VERSION ""

NS_ :

BS_:

BU_: VMCU VGGSECUSystem TECU TACHO RECU_Virt HMIIOM GSSA EMS EBS DACU CIOM BBM ATCU ACM

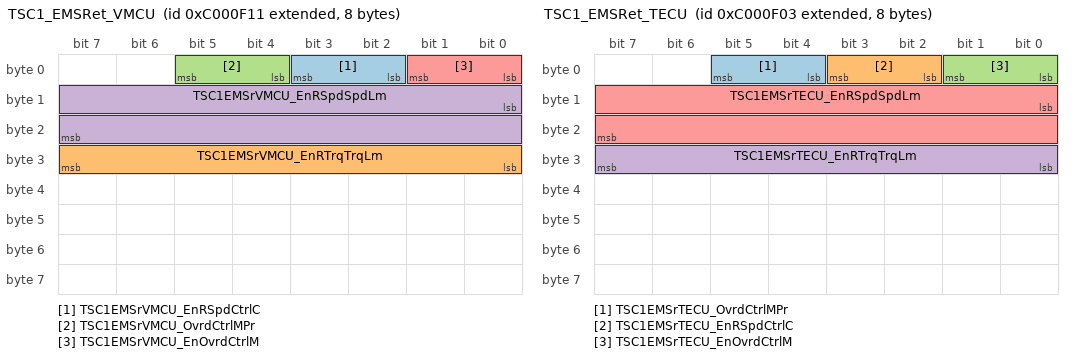
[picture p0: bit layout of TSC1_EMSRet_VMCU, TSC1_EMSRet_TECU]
BO_ 2348814097 TSC1_EMSRet_VMCU: 8 VMCU
 SG_ TSC1EMSrVMCU_EnRSpdCtrlC : 2|2@1+ (1,0) [0|0] ""  EBS,EMS
 SG_ TSC1EMSrVMCU_EnRTrqTrqLm : 24|8@1+ (1,-125) [-125|130] "Percent"  EMS,EBS
 SG_ TSC1EMSrVMCU_OvrdCtrlMPr : 4|2@1+ (1,0) [0|0] ""  EMS,EBS
 SG_ TSC1EMSrVMCU_EnRSpdSpdLm : 8|16@1+ (0.125,0) [0|8191.875] "rpm"  EBS,EMS
 SG_ TSC1EMSrVMCU_EnOvrdCtrlM : 0|2@1+ (1,0) [0|0] ""  EMS,EBS

BO_ 2348814083 TSC1_EMSRet_TECU: 8 TECU
 SG_ TSC1EMSrTECU_OvrdCtrlMPr : 4|2@1+ (1,0) [0|0] ""  EMS
 SG_ TSC1EMSrTECU_EnRSpdCtrlC : 2|2@1+ (1,0) [0|0] ""  EMS
 SG_ TSC1EMSrTECU_EnOvrdCtrlM : 0|2@1+ (1,0) [0|0] ""  EMS
 SG_ TSC1EMSrTECU_EnRTrqTrqLm : 24|8@1+ (1,-125) [-125|130] "Percent"  EMS
 SG_ TSC1EMSrTECU_EnRSpdSpdLm : 8|16@1+ (0.125,0) [0|8191.875] "rpm"  EMS

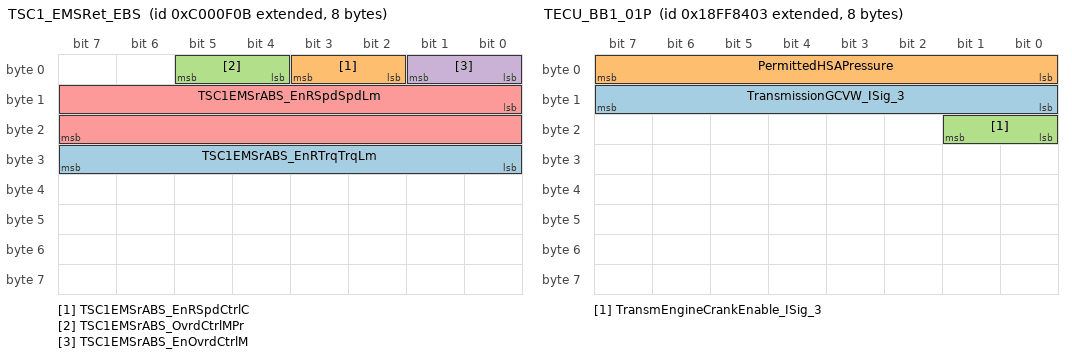
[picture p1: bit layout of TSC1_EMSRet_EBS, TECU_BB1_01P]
BO_ 2348814091 TSC1_EMSRet_EBS: 8 EBS
 SG_ TSC1EMSrABS_EnRTrqTrqLm : 24|8@1+ (1,-125) [-125|130] "Percent"  TECU,EMS
 SG_ TSC1EMSrABS_EnRSpdCtrlC : 2|2@1+ (1,0) [0|0] ""  TECU,EMS
 SG_ TSC1EMSrABS_OvrdCtrlMPr : 4|2@1+ (1,0) [0|0] ""  TECU,EMS
 SG_ TSC1EMSrABS_EnOvrdCtrlM : 0|2@1+ (1,0) [0|0] ""  TECU,EMS
 SG_ TSC1EMSrABS_EnRSpdSpdLm : 8|16@1+ (0.125,0) [0|8191.875] "rpm"  TECU,EMS

BO_ 2566755587 TRF2_X_TCU: 8 Vector__XXX

BO_ 2566846467 TRF1_X_TECU: 8 TECU
 SG_ TransmissionOilTemp_ISig_3 : 32|16@1+ (0.03125,-273) [-273|1774.96875] "DegreeC"  BBM,EMS,HMIIOM
 SG_ TransmissionOilLevel_ISig_3 : 8|8@1+ (0.4,0) [0|102] "Percent"  HMIIOM

BO_ 2565603075 TPDT_X_TECU: 8 TECU
 SG_ TPDT_SeqNo_TECU : 0|8@1+ (1,0) [0|0] ""  HMIIOM

BO_ 2565603310 TPDT_X_TACHO: 8 TACHO
 SG_ TPDT_SeqNo_TACHO : 0|8@1+ (1,0) [0|0] ""  HMIIOM,VMCU,CIOM

BO_ 2565603088 TPDT_X_RECU: 8 RECU_Virt
 SG_ TPDT_SeqNo_RECU : 0|8@1+ (1,0) [0|0] ""  DACU,EMS,VMCU,TECU,EBS

BO_ 2565603077 TPDT_X_GSSA: 8 Vector__XXX

BO_ 2565603087 TPDT_X_EMSRet: 8 EMS
 SG_ TPDT_SeqNo_EMSRet : 0|8@1+ (1,0) [0|0] ""  TECU,RECU_Virt,DACU,EBS,VGGSECUSystem,HMIIOM,VMCU

BO_ 2565603072 TPDT_X_EMS: 8 EMS
 SG_ TPDT_SeqNo_EMS : 0|8@1+ (1,0) [0|0] ""  TECU,DACU,HMIIOM,VMCU,VGGSECUSystem,EBS,RECU_Virt

BO_ 2565603083 TPDT_X_EBS: 8 EBS
 SG_ TPDT_SeqNo_EBS : 0|8@1+ (1,0) [0|0] ""  HMIIOM,VMCU

BO_ 2565603133 TPDT_X_ACM: 8 ACM
 SG_ TPDT_SeqNo_ACM : 0|8@1+ (1,0) [0|0] ""  HMIIOM

BO_ 2565668611 TPCM_X_TECU: 8 TECU
 SG_ TPCM_ControlByte_TECU : 0|8@1+ (1,0) [0|0] ""  HMIIOM

BO_ 2565668846 TPCM_X_TACHO: 8 TACHO
 SG_ TPCM_ControlByte_TACHO : 0|8@1+ (1,0) [0|0] ""  VMCU,CIOM,HMIIOM

BO_ 2565668624 TPCM_X_RECU: 8 RECU_Virt
 SG_ TPCM_ControlByte_RECU : 0|8@1+ (1,0) [0|0] ""  TECU,EMS,VMCU,DACU,EBS

BO_ 2565668613 TPCM_X_GSSA: 8 Vector__XXX

BO_ 2565668623 TPCM_X_EMSRet: 8 EMS
 SG_ TPCM_ControlByte_EMSRet : 0|8@1+ (1,0) [0|0] ""  DACU,VGGSECUSystem,HMIIOM,EBS,RECU_Virt,VMCU,TECU

BO_ 2565668608 TPCM_X_EMS: 8 EMS
 SG_ TPCM_ControlByte_EMS : 0|8@1+ (1,0) [0|0] ""  EBS,DACU,RECU_Virt,TECU,VGGSECUSystem,VMCU,HMIIOM

BO_ 2565668619 TPCM_X_EBS: 8 EBS
 SG_ TPCM_ControlByte_EBS : 0|8@1+ (1,0) [0|0] ""  HMIIOM,VMCU

BO_ 2565668669 TPCM_X_ACM: 8 ACM
 SG_ TPCM_ControlByte_ACM : 0|8@1+ (1,0) [0|0] ""  HMIIOM

BO_ 2633844483 TML_X_TCU: 8 Vector__XXX

BO_ 2566882307 TECU_BB1_01P: 8 TECU
 SG_ TransmissionGCVW_ISig_3 : 8|8@1+ (1000,0) [0|255000] "kg"  HMIIOM,EMS,VMCU
 SG_ PermittedHSAPressure : 0|8@1+ (0.4,0) [0|102] "Percent"  EBS
 SG_ TransmEngineCrankEnable_ISig_3 : 16|2@1+ (1,0) [0|0] ""  VMCU

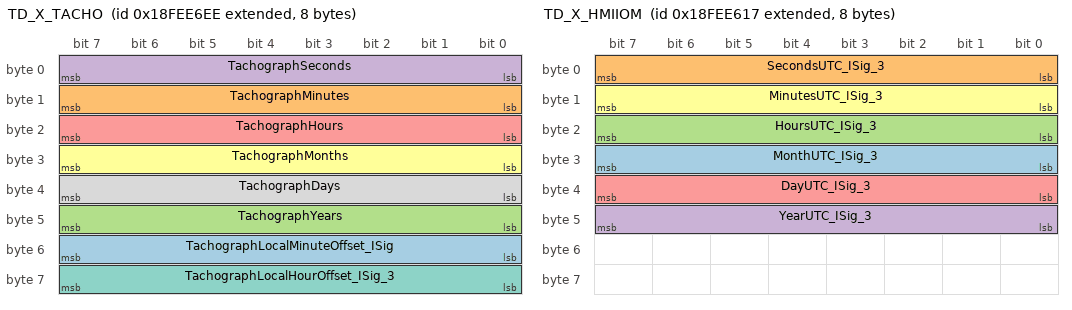
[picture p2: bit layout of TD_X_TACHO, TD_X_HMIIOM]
BO_ 2566842094 TD_X_TACHO: 8 TACHO
 SG_ TachographLocalMinuteOffset_ISig : 48|8@1+ (1,-125) [-125|130] "min"  HMIIOM,BBM
 SG_ TachographMinutes : 8|8@1+ (1,0) [0|255] "min"  HMIIOM
 SG_ TachographYears : 40|8@1+ (1,1985) [1985|2240] "Years"  HMIIOM
 SG_ TachographSeconds : 0|8@1+ (0.25,0) [0|63.75] "s"  HMIIOM
 SG_ TachographHours : 16|8@1+ (1,0) [0|255] "h"  HMIIOM
 SG_ TachographMonths : 24|8@1+ (1,0) [0|255] "Months"  HMIIOM
 SG_ TachographLocalHourOffset_ISig_3 : 56|8@1+ (1,-125) [-125|130] "h"  BBM,HMIIOM
 SG_ TachographDays : 32|8@1+ (0.25,0) [0|63.75] "Days"  HMIIOM

BO_ 2566841879 TD_X_HMIIOM: 8 HMIIOM
 SG_ MonthUTC_ISig_3 : 24|8@1+ (1,0) [0|255] "Months"  EBS,TECU,ACM,DACU,EMS,BBM,VMCU,CIOM
 SG_ SecondsUTC_ISig_3 : 0|8@1+ (0.25,0) [0|63.75] "s"  DACU,TECU,CIOM,ACM,VMCU,BBM,EBS,EMS
 SG_ HoursUTC_ISig_3 : 16|8@1+ (1,0) [0|255] "h"  EBS,DACU,ACM,BBM,TECU,CIOM,VMCU,EMS
 SG_ YearUTC_ISig_3 : 40|8@1+ (1,1985) [1985|2240] "Years"  EBS,EMS,DACU,VMCU,ACM,BBM,CIOM,TECU
 SG_ DayUTC_ISig_3 : 32|8@1+ (0.25,0) [0|63.75] "Days"  TECU,CIOM,EBS,VMCU,EMS,DACU,ACM,BBM
 SG_ MinutesUTC_ISig_3 : 8|8@1+ (1,0) [0|255] "min"  DACU,VMCU,TECU,CIOM,ACM,EMS,EBS,BBM

BO_ 2564156951 TDA_X_HMIIOM: 8 HMIIOM
 SG_ AdjustLocalMinuteOffset : 48|8@1+ (1,-125) [-125|130] "min"  TACHO
 SG_ AdjustLocalHourOffset : 56|8@1+ (1,-125) [-125|130] "h"  TACHO

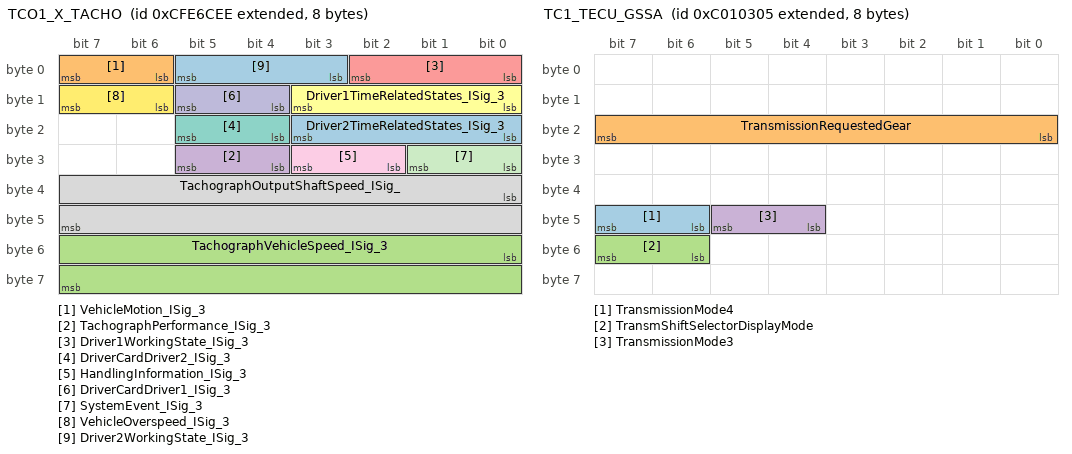
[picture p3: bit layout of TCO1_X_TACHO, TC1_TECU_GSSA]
BO_ 2365484270 TCO1_X_TACHO: 8 TACHO
 SG_ Driver2TimeRelatedStates_ISig_3 : 16|4@1+ (1,0) [0|0] ""  BBM,CIOM,HMIIOM
 SG_ VehicleMotion_ISig_3 : 6|2@1+ (1,0) [0|0] ""  HMIIOM,CIOM,BBM
 SG_ TachographVehicleSpeed_ISig_3 : 48|16@1+ (0.00390625,0) [0|255.99609375] "Km_per_h"  CIOM,VMCU,BBM,HMIIOM
 SG_ TachographPerformance_ISig_3 : 28|2@1+ (1,0) [0|0] ""  BBM,CIOM,HMIIOM,VMCU
 SG_ Driver1WorkingState_ISig_3 : 0|3@1+ (1,0) [0|0] ""  BBM,HMIIOM,CIOM
 SG_ Driver1TimeRelatedStates_ISig_3 : 8|4@1+ (1,0) [0|0] ""  CIOM,BBM,HMIIOM
 SG_ DriverCardDriver2_ISig_3 : 20|2@1+ (1,0) [0|0] ""  CIOM,BBM,HMIIOM
 SG_ TachographOutputShaftSpeed_ISig_ : 32|16@1+ (0.125,0) [0|8191.875] "rpm"  VMCU,BBM
 SG_ HandlingInformation_ISig_3 : 26|2@1+ (1,0) [0|0] ""  CIOM,VMCU,HMIIOM,BBM
 SG_ DriverCardDriver1_ISig_3 : 12|2@1+ (1,0) [0|0] ""  CIOM,VMCU,HMIIOM,BBM,DACU
 SG_ SystemEvent_ISig_3 : 24|2@1+ (1,0) [0|0] ""  HMIIOM,BBM,VMCU,CIOM
 SG_ VehicleOverspeed_ISig_3 : 14|2@1+ (1,0) [0|0] ""  CIOM,BBM,HMIIOM
 SG_ Driver2WorkingState_ISig_3 : 3|3@1+ (1,0) [0|0] ""  CIOM,BBM,HMIIOM

BO_ 2566840835 TCFG_X_TCU: 8 Vector__XXX

BO_ 2348876549 TC1_TECU_GSSA: 8 GSSA
 SG_ TransmissionMode4 : 46|2@1+ (1,0) [0|0] ""  TECU
 SG_ TransmissionRequestedGear : 16|8@1+ (1,-125) [-125|130] "GearValue"  TECU
 SG_ TransmShiftSelectorDisplayMode : 54|2@1+ (1,0) [0|0] ""  TECU
 SG_ TransmissionMode3 : 44|2@1+ (1,0) [0|0] ""  TECU

BO_ 2566838787 SOFT_X_TCU: 8 Vector__XXX

BO_ 2566838789 SOFT_X_GSSA: 8 Vector__XXX

BO_ 2566862055 Reserved_VDC_BB1: 8 Vector__XXX

BO_ 2566862311 Reserved_CCU_BB1_04P: 8 Vector__XXX

BO_ 2566861799 Reserved_CCU_BB1_03P: 8 Vector__XXX

BO_ 2566861543 Reserved_CCU_BB1_02P: 8 Vector__XXX

BO_ 2566861287 Reserved_CCU_BB1_01P: 8 Vector__XXX

BO_ 2566862567 Reserved_BMS_BB1_01P: 8 Vector__XXX

BO_ 2565537539 RQST_X_TCU: 8 Vector__XXX

BO_ 2565533233 RQST_TACHO_CIOM: 3 CIOM
 SG_ PGNReq_Tacho_CIOM : 0|24@1+ (1,0) [0|0] ""  TACHO

BO_ 2565473539 RQST_GSSA_TCU: 8 Vector__XXX

BO_ 2631855639 RESET_TACHO_HMIIOM: 8 HMIIOM
 SG_ CounterReset_GUIEventCmd : 2|2@1+ (1,0) [0|0] ""  TACHO

BO_ 2499792656 RECU_BB1_01P: 8 RECU_Virt
 SG_ DrivelineRetarderStat_ISig_3 : 0|2@1+ (1,0) [0|0] ""  HMIIOM

BO_ 2566840592 RC_X_RECU: 19 RECU_Virt
 SG_ DrivelineRetarderRefTorque : 128|16@1+ (1,0) [0|65535] "Nm"  EBS,VMCU,DACU,TECU,EMS
 SG_ DrivelineRetarderLocation : 4|4@1+ (1,0) [0|0] ""  EMS,DACU,EBS
 SG_ DrivelineRetarderType : 0|4@1+ (1,0) [0|0] ""  EBS

BO_ 2566840591 RC_X_EMSRet: 19 EMS
 SG_ EngRetConf_RetCtrlMethod : 8|8@1+ (1,0) [0|255] "Step"  TECU
 SG_ EngRetConf_RetSpeedAtP4 : 88|16@1+ (0.125,0) [0|8191.875] "rpm"  TECU
 SG_ EngRetConf_MaxRetSpeedP2 : 40|16@1+ (0.125,0) [0|8191.875] "rpm"  HMIIOM,TECU
 SG_ EngRetConf_PerTrqAtP3 : 80|8@1+ (1,-125) [-125|130] "Percent"  TECU
 SG_ EngRetConf_RetSpeedAtP5 : 112|16@1+ (0.125,0) [0|8191.875] "rpm"  TECU
 SG_ EngRetConf_speedAtIdleP1 : 16|16@1+ (0.125,0) [0|8191.875] "rpm"  TECU
 SG_ EngRetConf_PerTrqAtP4 : 104|8@1+ (1,-125) [-125|130] "Percent"  TECU
 SG_ ReferenceEngineRetarderTorque : 128|16@1+ (1,0) [0|65535] "Nm"  VMCU,EBS,VGGSECUSystem,DACU,RECU_Virt,TECU
 SG_ EngRetConf_PerTrqAtIdleP1 : 32|8@1+ (1,-125) [-125|130] "Percent"  TECU
 SG_ EngRetConf_RetSpeedAtP3 : 64|16@1+ (0.125,0) [0|8191.875] "rpm"  TECU
 SG_ EngRetConf_PerTrqAtMaxSpeedP2 : 56|8@1+ (1,-125) [-125|130] "Percent"  TECU
 SG_ EngRetConf_PerTrqAtP5 : 144|8@1+ (1,-125) [-125|130] "Percent"  TECU

BO_ 2566899694 PropTCO4_X_TACHO: 44 TACHO
 SG_ TwoWeeksTotalOdometer : 288|16@1+ (1,0) [0|65535] "km"  HMIIOM
 SG_ WeeklyTotalOdometer : 272|16@1+ (1,0) [0|65535] "km"  HMIIOM
 SG_ DailyRestingTimeShift1_ISig_3 : 144|15@1+ (1,0) [0|32767] "min"  HMIIOM
 SG_ RestingPeriodFlagShift2_ISig_3 : 79|1@1+ (1,0) [0|0] ""  HMIIOM
 SG_ AvailableCounter : 336|16@1+ (1,0) [0|65535] "min"  HMIIOM
 SG_ DailyDrivingTimeShift4_ISig_3 : 96|15@1+ (1,0) [0|32767] "min"  HMIIOM
 SG_ DailyDrivingPeriod_ISig_3 : 32|15@1+ (1,0) [0|32767] "min"  HMIIOM
 SG_ DailyRestingTimeShift7_ISig_3 : 240|15@1+ (1,0) [0|32767] "min"  HMIIOM
 SG_ UnknownPeriodShift1_ISig_3 : 159|1@1+ (1,0) [0|0] ""  HMIIOM
 SG_ RestingPeriodFlagShift1_ISig_3 : 63|1@1+ (1,0) [0|0] ""  HMIIOM
 SG_ DrivingCounter : 304|16@1+ (1,0) [0|65535] "min"  HMIIOM
 SG_ DailyDrivingTimeShift3_ISig_3 : 80|15@1+ (1,0) [0|32767] "min"  HMIIOM
 SG_ DailyRestingTimeShift2_ISig_3 : 160|15@1+ (1,0) [0|32767] "min"  HMIIOM
 SG_ DailyRestingTimeShift3_ISig_3 : 176|15@1+ (1,0) [0|32767] "min"  HMIIOM
 SG_ UnknownPeriodShift2_ISig_3 : 175|1@1+ (1,0) [0|0] ""  HMIIOM
 SG_ RestingPeriodFlag_ISig_3 : 47|1@1+ (1,0) [0|0] ""  HMIIOM
 SG_ TwoWeekTotalDrvingTime_ISig_3 : 0|16@1+ (1,0) [0|65535] "min"  HMIIOM
 SG_ UnknownPeriodShift4_ISig_3 : 207|1@1+ (1,0) [0|0] ""  HMIIOM
 SG_ DailyDrivingTimeShift2_ISig_3 : 64|15@1+ (1,0) [0|32767] "min"  HMIIOM
 SG_ RestingPeriodFlagShift6_ISig_3 : 143|1@1+ (1,0) [0|0] ""  HMIIOM
 SG_ DailyRestingTimeShift4_ISig_3 : 192|15@1+ (1,0) [0|32767] "min"  HMIIOM
 SG_ RestingPeriodFlagShift5_ISig_3 : 127|1@1+ (1,0) [0|0] ""  HMIIOM
 SG_ RestingPeriodFlagShift3_ISig_3 : 95|1@1+ (1,0) [0|0] ""  HMIIOM
 SG_ DailyDrivingTimeShift5_ISig_3 : 112|15@1+ (1,0) [0|32767] "min"  HMIIOM
 SG_ DailyRestingTimeShift6_ISig_3 : 224|15@1+ (1,0) [0|32767] "min"  HMIIOM
 SG_ WeeklyTotalDrivingTime_ISig_3 : 16|16@1+ (1,0) [0|65535] "min"  HMIIOM
 SG_ UnknownPeriodShift7_ISig_3 : 255|1@1+ (1,0) [0|0] ""  HMIIOM
 SG_ DailyOdometer : 256|16@1+ (1,0) [0|65535] "km"  HMIIOM
 SG_ UnknownPeriodShift6_ISig_3 : 239|1@1+ (1,0) [0|0] ""  HMIIOM
 SG_ DailyRestingTimeShift5_ISig_3 : 208|15@1+ (1,0) [0|32767] "min"  HMIIOM
 SG_ DailyDrivingTimeShift1_ISig_3 : 48|15@1+ (1,0) [0|32767] "min"  HMIIOM
 SG_ UnknownPeriodShift3_ISig_3 : 191|1@1+ (1,0) [0|0] ""  HMIIOM
 SG_ RestingPeriodFlagShift4_ISig_3 : 111|1@1+ (1,0) [0|0] ""  HMIIOM
 SG_ DailyDrivingTimeShift6_ISig_3 : 128|15@1+ (1,0) [0|32767] "min"  HMIIOM
 SG_ UnknownPeriodShift5_ISig_3 : 223|1@1+ (1,0) [0|0] ""  HMIIOM
 SG_ WorkCounter : 320|16@1+ (1,0) [0|65535] "min"  HMIIOM

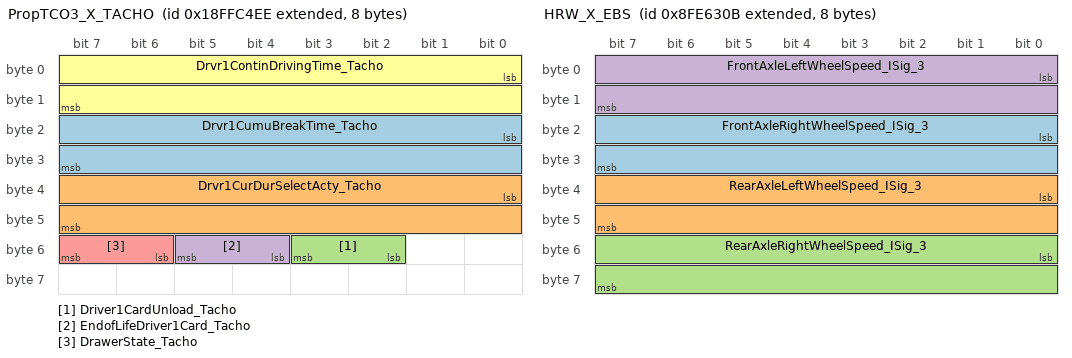
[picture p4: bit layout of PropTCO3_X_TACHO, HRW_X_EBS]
BO_ 2566898926 PropTCO3_X_TACHO: 8 TACHO
 SG_ Drvr1CumuBreakTime_Tacho : 16|16@1+ (1,0) [0|65535] "min"  VMCU
 SG_ Drvr1CurDurSelectActy_Tacho : 32|16@1+ (1,0) [0|65535] "min"  VMCU
 SG_ Driver1CardUnload_Tacho : 50|2@1+ (1,0) [0|0] ""  VMCU
 SG_ EndofLifeDriver1Card_Tacho : 52|2@1+ (1,0) [0|0] ""  VMCU
 SG_ DrawerState_Tacho : 54|2@1+ (1,0) [0|0] ""  VMCU
 SG_ Drvr1ContinDrivingTime_Tacho : 0|16@1+ (1,0) [0|65535] "min"  VMCU

BO_ 2566898670 PropTCO2_X_TACHO: 21 TACHO
 SG_ NextCalibrationDateDay : 136|8@1+ (0.25,0) [0|63.75] "Days"  VMCU
 SG_ WVehicleCharacteristicFactor : 152|16@1+ (0.001,0) [0|65.535] "NotApplicable"  VMCU
 SG_ NextCalibrationDateMonth : 128|8@1+ (1,0) [0|255] "Months"  VMCU
 SG_ Driver1Identification_ISig_3 : 0|112@1+ (1,0) [0|0] ""  HMIIOM,CIOM
 SG_ NextCalibrationDateYear : 144|8@1+ (1,1985) [1985|2240] "Years"  VMCU

BO_ 2565800709 PropA_TCU_GSSA: 8 Vector__XXX

BO_ 2565801219 PropA_GSSA_TCU: 8 Vector__XXX

BO_ 2671833838 PhysDiagRespMsg_F2_EE_BB1: 8 TACHO
 SG_ PhysDiagRespSig_F2_EE_ISig_3 : 0|64@1+ (1,0) [0|0] ""  VMCU

BO_ 2671833640 PhysDiagRespMsg_F2_28_BB1: 8 EBS
 SG_ PhysDiagRespSig_F2_28_ISig_3 : 0|64@1+ (1,0) [0|0] ""  VMCU

BO_ 2671833617 PhysDiagRespMsg_F2_11_BB1: 8 ACM
 SG_ PhysDiagRespSig_F2_11_ISig_3 : 0|64@1+ (1,0) [0|0] ""  VMCU

BO_ 2671833361 PhysDiagRespMsg_F1_11_BB1: 8 ACM
 SG_ PhysDiagRespSig_F1_11_ISig_3 : 0|64@1+ (1,0) [0|0] ""  VMCU

BO_ 2671832818 PhysDiagReqMsg_EE_F2_BB1: 8 VMCU
 SG_ PhysDiagReqSig_EE_F2_ISig_3 : 0|64@1+ (1,0) [0|0] ""  TACHO

BO_ 2671782130 PhysDiagReqMsg_28_F2_BB1: 8 VMCU
 SG_ PhysDiagReqSig_28_F2_ISig_3 : 0|64@1+ (1,0) [0|0] ""  EBS

BO_ 2671776242 PhysDiagReqMsg_11_F2_BB1: 8 VMCU
 SG_ PhysDiagReqSig_11_F2_ISig_3 : 0|64@1+ (1,0) [0|0] ""  ACM

BO_ 2671776241 PhysDiagReqMsg_11_F1_BB1: 8 VMCU
 SG_ PhysDiagReqSig_11_F1_ISig_3 : 0|64@1+ (1,0) [0|0] ""  ACM

BO_ 2566759457 PTODE_X_VMCU: 8 VMCU
 SG_ Pto2EnableSwitch : 4|2@1+ (1,0) [0|0] ""  TECU
 SG_ Pto1EnableSwitch : 6|2@1+ (1,0) [0|0] ""  TECU

BO_ 2566759427 PTODE_X_TECU: 8 TECU
 SG_ Pto2EngagementConsent : 20|2@1+ (1,0) [0|0] ""  VMCU
 SG_ Pto1EngagementConsent : 22|2@1+ (1,0) [0|0] ""  VMCU

BO_ 2671850481 OBDFuncDiagMsg_BB1: 8 VMCU
 SG_ FuncDiagDataOBD_ISig_3 : 0|64@1+ (1,0) [0|0] ""  ACM

BO_ 2566844928 LFE_X_EMS: 8 EMS
 SG_ InstantaneousFuelEconomy_ISig_3 : 16|16@1+ (0.001953125,0) [0|127.998046875] "km_per_l"  CIOM,HMIIOM
 SG_ EngineFuelRate_ISig_3 : 0|16@1+ (0.05,0) [0|3276.75] "l_per_h"  BBM,VMCU,HMIIOM,CIOM

BO_ 2564428270 KWP2000Resp_VMCU_TACHO: 8 TACHO
 SG_ KWP2000Response_TACHO : 0|64@1+ (1,0) [0|0] ""  VMCU

BO_ 2564484625 KWP2000Req_TACHO_VMCU: 8 VMCU
 SG_ KWP2000Request_TACHO : 0|64@1+ (1,0) [0|0] ""  TACHO

BO_ 2633861635 J2012_X_TCU: 8 Vector__XXX

BO_ 2671902708 IntTesterTGW2FuncDiagMsg_BB1: 8 HMIIOM
 SG_ FuncDiagDataIntTesterTGW2_ISig_3 : 0|64@1+ (1,0) [0|0] ""  TACHO,EBS,ACM

BO_ 2566825472 IMT1_X_EMS: 8 EMS
 SG_ EngineTurbo1BoostPressure : 0|16@1+ (0.125,0) [0|8191.875] "kPa"  VGGSECUSystem,HMIIOM,ACM

BO_ 2566845952 IC1_X_EMS: 8 EMS
 SG_ EngIntakeManifold1Temp : 16|8@1+ (1,-40) [-40|215] "DegreeC"  VGGSECUSystem

BO_ 2298372875 HRW_X_EBS: 8 EBS
 SG_ FrontAxleRightWheelSpeed_ISig_3 : 16|16@1+ (0.00390625,0) [0|255.99609375] "Km_per_h"  VMCU,BBM,DACU,VGGSECUSystem,TECU,HMIIOM
 SG_ RearAxleLeftWheelSpeed_ISig_3 : 32|16@1+ (0.00390625,0) [0|255.99609375] "Km_per_h"  BBM,VMCU,VGGSECUSystem,TECU,DACU
 SG_ RearAxleRightWheelSpeed_ISig_3 : 48|16@1+ (0.00390625,0) [0|255.99609375] "Km_per_h"  BBM,VMCU,TECU,DACU,VGGSECUSystem
 SG_ FrontAxleLeftWheelSpeed_ISig_3 : 0|16@1+ (0.00390625,0) [0|255.99609375] "Km_per_h"  TECU,HMIIOM,DACU,BBM,VMCU,VGGSECUSystem

BO_ 2566719744 HRLFC_X_EMS: 8 EMS
 SG_ HighResEngineTotalFuelUsed_ISig_ : 32|32@1+ (0.001,0) [0|4294967.295] "l"  HMIIOM,BBM,CIOM

BO_ 2566841600 HOURS_X_EMS: 8 EMS
 SG_ EngineRevolutions_ISig_3 : 32|32@1+ (1000,0) [0|4294967295000] "r"  HMIIOM

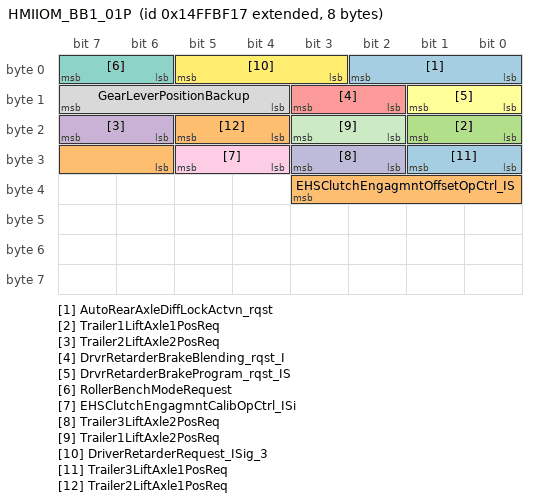
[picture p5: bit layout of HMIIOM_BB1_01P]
BO_ 2499788567 HMIIOM_BB1_01P: 8 HMIIOM
 SG_ AutoRearAxleDiffLockActvn_rqst : 0|3@1+ (1,0) [0|0] ""  EBS
 SG_ EHSClutchEngagmntOffsetOpCtrl_IS : 30|6@1+ (1,-30) [-30|33] "Step"  EBS
 SG_ Trailer1LiftAxle1PosReq : 16|2@1+ (1,0) [0|0] ""  EBS
 SG_ Trailer2LiftAxle2PosReq : 22|2@1+ (1,0) [0|0] ""  EBS
 SG_ DrvrRetarderBrakeBlending_rqst_I : 10|2@1+ (1,0) [0|0] ""  TECU,EBS,VMCU
 SG_ DrvrRetarderBrakeProgram_rqst_IS : 8|2@1+ (1,0) [0|0] ""  VMCU,TECU
 SG_ RollerBenchModeRequest : 6|2@1+ (1,0) [0|0] ""  EBS
 SG_ GearLeverPositionBackup : 12|4@1+ (1,0) [0|0] ""  TECU
 SG_ EHSClutchEngagmntCalibOpCtrl_ISi : 28|2@1+ (1,0) [0|0] ""  EBS
 SG_ Trailer3LiftAxle2PosReq : 26|2@1+ (1,0) [0|0] ""  EBS
 SG_ Trailer1LiftAxle2PosReq : 18|2@1+ (1,0) [0|0] ""  EBS
 SG_ DriverRetarderRequest_ISig_3 : 3|3@1+ (1,0) [0|0] ""  VMCU,EBS,TECU,EMS,RECU_Virt
 SG_ Trailer3LiftAxle1PosReq : 24|2@1+ (1,0) [0|0] ""  EBS
 SG_ Trailer2LiftAxle1PosReq : 20|2@1+ (1,0) [0|0] ""  EBS

CM_ BO_ 2348814097 "PGN 0 Torque/Speed Control 1, From VMCU to EMS Retarder";
CM_ SG_ 2348814097 TSC1EMSrVMCU_EnRTrqTrqLm "254 Error ; 255 Not available";
CM_ SG_ 2348814097 TSC1EMSrVMCU_EnRSpdSpdLm "65024 - 65279 Error ; 65280 - 65535 Not available";
CM_ BO_ 2348814083 "PGN 0 Torque/Speed Control 1, From TECU to EMS Retarder";
CM_ SG_ 2348814083 TSC1EMSrTECU_EnRTrqTrqLm "254 Error ; 255 Not available";
CM_ SG_ 2348814083 TSC1EMSrTECU_EnRSpdSpdLm "65024 - 65279 Error ; 65280 - 65535 Not available";
CM_ BO_ 2348814091 "PGN 0 Torque/Speed Control 1, From EBS to EMS Retarder";
CM_ SG_ 2348814091 TSC1EMSrABS_EnRTrqTrqLm "254 Error ; 255 Not available";
CM_ SG_ 2348814091 TSC1EMSrABS_EnRSpdSpdLm "65024 - 65279 Error ; 65280 - 65535 Not available";
CM_ BO_ 2566755587 "PGN 64917 Transmission Fluids 2";
CM_ BO_ 2566846467 "PGN 65272 Transmission Fluids 1";
CM_ SG_ 2566846467 TransmissionOilTemp_ISig_3 "65024 - 65279 Error ; 65280 - 65535 Not available";
CM_ BO_ 2565603075 "PGN 60160 Transport Protocol Data Transfer, From TECU";
CM_ BO_ 2565603310 "PGN 60160 Transport Protocol Data Transfer, From TACHO";
CM_ BO_ 2565603088 "PGN 60160 Transport Protocol Data Transfer, From RECU";
CM_ BO_ 2565603077 "PGN 60160 Transport Protocol Data Transfer";
CM_ BO_ 2565603087 "PGN 60160 Transport Protocol Data Transfer, From EMS Retarder";
CM_ BO_ 2565603072 "PGN 60160 Transport Protocol Data Transfer, From EMS";
CM_ BO_ 2565603083 "PGN 60160 Transport Protocol Data Transfer, From EBS";
CM_ BO_ 2565603133 "PGN 60160 Transport Protocol Data Transfer, From ACM";
CM_ BO_ 2565668611 "PGN 60416 Transport Protocol Connection Management, From TECU";
CM_ BO_ 2565668846 "PGN 60416 Transport Protocol Connection Management, From TACHO";
CM_ BO_ 2565668624 "PGN 60416 Transport Protocol Connection Management, From RECU";
CM_ BO_ 2565668613 "PGN 60416 Transport Protocol Connection Management";
CM_ BO_ 2565668623 "PGN 60416 Transport Protocol Connection Management, From EMS Retarder";
CM_ BO_ 2565668608 "PGN 60416 Transport Protocol Connection Management, From EMS";
CM_ BO_ 2565668619 "PGN 60416 Transport Protocol Connection Management, From EBS";
CM_ BO_ 2565668669 "PGN 60416 Transport Protocol Connection Management, From ACM";
CM_ BO_ 2633844483 "PGN64839 Transmission Mode Labels";
CM_ SG_ 2566882307 TransmissionGCVW_ISig_3 "254 Error ; 255 Not available";
CM_ SG_ 2566882307 PermittedHSAPressure "254 Error ; 255 Not available";
CM_ BO_ 2566842094 "PGN 65254 Time/Date, From TACHO";
CM_ SG_ 2566842094 TachographLocalMinuteOffset_ISig "254 Error ; 255 Not available";
CM_ SG_ 2566842094 TachographMinutes "254 Error ; 255 Not available";
CM_ SG_ 2566842094 TachographYears "254 Error ; 255 Not available";
CM_ SG_ 2566842094 TachographSeconds "254 Error ; 255 Not available";
CM_ SG_ 2566842094 TachographHours "254 Error ; 255 Not available";
CM_ SG_ 2566842094 TachographMonths "254 Error ; 255 Not available";
CM_ SG_ 2566842094 TachographLocalHourOffset_ISig_3 "254 Error ; 255 Not available";
CM_ SG_ 2566842094 TachographDays "254 Error ; 255 Not available";
CM_ BO_ 2566841879 "PGN 65254 Time/Date, From HMIIOM";
CM_ SG_ 2566841879 MonthUTC_ISig_3 "254 Error ; 255 Not available";
CM_ SG_ 2566841879 SecondsUTC_ISig_3 "254 Error ; 255 Not available";
CM_ SG_ 2566841879 HoursUTC_ISig_3 "254 Error ; 255 Not available";
CM_ SG_ 2566841879 YearUTC_ISig_3 "254 Error ; 255 Not available";
CM_ SG_ 2566841879 DayUTC_ISig_3 "254 Error ; 255 Not available";
CM_ SG_ 2566841879 MinutesUTC_ISig_3 "254 Error ; 255 Not available";
CM_ BO_ 2564156951 "PGN 54528 TimeDate Adjust";
CM_ SG_ 2564156951 AdjustLocalMinuteOffset "254 Error ; 255 Not available";
CM_ SG_ 2564156951 AdjustLocalHourOffset "254 Error ; 255 Not available";
CM_ BO_ 2365484270 "PGN 65132 Tachograph";
CM_ SG_ 2365484270 TachographVehicleSpeed_ISig_3 "65024 - 65279 Error ; 65280 - 65535 Not available";
CM_ SG_ 2365484270 TachographOutputShaftSpeed_ISig_ "65024 - 65279 Error ; 65280 - 65535 Not available";
CM_ BO_ 2566840835 "PGN 65250 Transmission Configuration";
CM_ BO_ 2348876549 "PGN 256 Transmission Control 1, Gearshift selector to Transmission.
Transmission rate: When active; 50 ms to transmission and axles";
CM_ BO_ 2566838787 "PGN 65242 Software Identification";
CM_ BO_ 2566838789 "PGN 65242 Software Identification";
CM_ BO_ 2566862055 "Reserved ID for EBMR tx100ms";
CM_ BO_ 2566862311 "Reserved ID for EBMR tx100ms";
CM_ BO_ 2566861799 "Reserved ID for EBMR tx100ms";
CM_ BO_ 2566861543 "Reserved ID for EBMR tx100ms";
CM_ BO_ 2566861287 "Reserved ID for EBMR tx250ms +100ms state change";
CM_ BO_ 2566862567 "Reserved ID for EBMR tx1000ms, Note SA may be modified";
CM_ BO_ 2565537539 "PGN59904 Request PGN Global sent by Transmission ECU";
CM_ BO_ 2565533233 "PGN 59904 Request PGN ";
CM_ BO_ 2565473539 "PGN59904 Request PGN to GearShiftSelector sent by Transmission ECU";
CM_ BO_ 2631855639 "PGN 56832 Reset, from HMIIOM to TACHO";
CM_ BO_ 2566840592 "PGN 65249 Retarder Configuration from RECU";
CM_ SG_ 2566840592 DrivelineRetarderRefTorque "65024 - 65279 Error ; 65280 - 65535 Not available";
CM_ BO_ 2566840591 "PGN 65249 Retarder Configuration from EMSRetarder";
CM_ SG_ 2566840591 EngRetConf_RetCtrlMethod "254 Error ; 255 Not available";
CM_ SG_ 2566840591 EngRetConf_RetSpeedAtP4 "65024 - 65279 Error ; 65280 - 65535 Not available";
CM_ SG_ 2566840591 EngRetConf_MaxRetSpeedP2 "65024 - 65279 Error ; 65280 - 65535 Not available";
CM_ SG_ 2566840591 EngRetConf_PerTrqAtP3 "254 Error ; 255 Not available";
CM_ SG_ 2566840591 EngRetConf_RetSpeedAtP5 "65024 - 65279 Error ; 65280 - 65535 Not available";
CM_ SG_ 2566840591 EngRetConf_speedAtIdleP1 "65024 - 65279 Error ; 65280 - 65535 Not available";
CM_ SG_ 2566840591 EngRetConf_PerTrqAtP4 "254 Error ; 255 Not available";
CM_ SG_ 2566840591 ReferenceEngineRetarderTorque "65024 - 65279 Error ; 65280 - 65535 Not available";
CM_ SG_ 2566840591 EngRetConf_PerTrqAtIdleP1 "254 Error ; 255 Not available";
CM_ SG_ 2566840591 EngRetConf_RetSpeedAtP3 "65024 - 65279 Error ; 65280 - 65535 Not available";
CM_ SG_ 2566840591 EngRetConf_PerTrqAtMaxSpeedP2 "254 Error ; 255 Not available";
CM_ SG_ 2566840591 EngRetConf_PerTrqAtP5 "254 Error ; 255 Not available";
CM_ BO_ 2566899694 "Proprietary TACHO message 4";
CM_ SG_ 2566899694 TwoWeekTotalDrvingTime_ISig_3 "65024 - 65279 Error ; 65280 - 65535 Not available";
CM_ SG_ 2566899694 WeeklyTotalDrivingTime_ISig_3 "65024 - 65279 Error ; 65280 - 65535 Not available";
CM_ BO_ 2566898926 "Proprietary TACHO message 3";
CM_ SG_ 2566898926 Drvr1CumuBreakTime_Tacho "65024 - 65279 Error ; 65280 - 65535 Not available";
CM_ SG_ 2566898926 Drvr1CurDurSelectActy_Tacho "65024 - 65279 Error ; 65280 - 65535 Not available";
CM_ SG_ 2566898926 Drvr1ContinDrivingTime_Tacho "65024 - 65279 Error ; 65280 - 65535 Not available";
CM_ BO_ 2566898670 "Proprietary TACHO message 2";
CM_ SG_ 2566898670 NextCalibrationDateDay "254 Error ; 255 Not available";
CM_ SG_ 2566898670 NextCalibrationDateMonth "254 Error ; 255 Not available";
CM_ SG_ 2566898670 NextCalibrationDateYear "254 Error ; 255 Not available";
CM_ BO_ 2565800709 "PGN61184 Proprietary A data sent by Transmission ECU to Gearshift selector";
CM_ BO_ 2565801219 "PGN61184 Proprietary A data sent by Gearshift selector to Transmission ECU";
CM_ BO_ 2566759457 "PGN 64932 PTO Drive Engagement";
CM_ BO_ 2566759427 "PGN 64932 PTO Drive Engagement
";
CM_ BO_ 2566844928 "PGN 65266 Fuel Economy (Liquid)";
CM_ SG_ 2566844928 InstantaneousFuelEconomy_ISig_3 "64256 - 65023 Spare
65024 - 65279 Error
65280 - 65535 NotAvailable";
CM_ SG_ 2566844928 EngineFuelRate_ISig_3 "65024 - 65279 Error ; 65280 - 65535 Not available";
CM_ BO_ 2633861635 "PGN 64906 SAE J2012 DTC Display";
CM_ BO_ 2566825472 "PGN 65190 Intake Manifold Information 1";
CM_ SG_ 2566825472 EngineTurbo1BoostPressure "65024 - 65279 Error ; 65280 - 65535 Not Available";
CM_ BO_ 2566845952 "PGN 65270 Inlet/Exhaust Conditions 1";
CM_ BO_ 2298372875 "PGN 65134 High Resolution Wheel Speed";
CM_ SG_ 2298372875 FrontAxleRightWheelSpeed_ISig_3 "65024 - 65279 Error ; 65280 - 65535 Not available";
CM_ SG_ 2298372875 RearAxleLeftWheelSpeed_ISig_3 "65024 - 65279 Error ; 65280 - 65535 Not available";
CM_ SG_ 2298372875 RearAxleRightWheelSpeed_ISig_3 "65024 - 65279 Error ; 65280 - 65535 Not available";
CM_ SG_ 2298372875 FrontAxleLeftWheelSpeed_ISig_3 "65024 - 65279 Error ; 65280 - 65535 Not available";
CM_ BO_ 2566719744 "PGN 64777 High Resolution Fuel Consumption (Liquid)";
CM_ SG_ 2566719744 HighResEngineTotalFuelUsed_ISig_ "4211081216 - 4261412863 Spare
4261412864 - 4278190079 Error
4278190080 - 4294967295 NotAvailable";
CM_ BO_ 2566841600 "PGN 65253 Engine Hours, Revolutions";
CM_ SG_ 2566841600 EngineRevolutions_ISig_3 "4261412864 - 4278190079 Error ; 4278190080 - 4294967295 Not available";
BA_DEF_ BO_  "GenMsgStartDelayTime" INT 0 0;
BA_DEF_ BO_  "GenMsgDelayTime" INT 0 0;
BA_DEF_ BO_  "GenMsgNrOfRepetition" INT 0 0;
BA_DEF_ BO_  "GenMsgCycleTimeFast" INT 0 0;
BA_DEF_ BO_  "GenMsgCycleTime" INT 0 0;
BA_DEF_ BO_  "GenMsgSendType" ENUM  "Cyclic","NotUsed","NotUsed","NotUsed","NotUsed","NotUsed","NotUsed","IfActive","NoMsgSendType","NotUsed";
BA_DEF_ SG_  "GenSigStartValue" INT 0 0;
BA_DEF_ SG_  "GenSigCycleTimeActive" INT 0 0;
BA_DEF_ SG_  "GenSigCycleTime" INT 0 0;
BA_DEF_ SG_  "GenSigSendType" ENUM  "Cyclic","OnWrite","OnWriteWithRepetition","OnChange","OnChangeWithRepetition","IfActive","IfActiveWithRepetition","NoSigSendType","NotUsed","NotUsed","NotUsed","NotUsed","NotUsed";
BA_DEF_ BO_  "VFrameFormat" ENUM  "StandardCAN","ExtendedCAN","reserved","J1939PG";
BA_DEF_ BO_  "TpJ1939VarDlc" ENUM  "No","Yes";
BA_DEF_ SG_  "SigType" ENUM  "Default","Range","RangeSigned","ASCII","Discrete","Control","ReferencePGN","DTC","StringDelimiter","StringLength","StringLengthControl";
BA_DEF_ SG_  "SeToolVersion_SIGNAL" STRING ;
BA_DEF_ SG_  "SeToolUniqueID_SIGNAL" STRING ;
BA_DEF_ SG_  "SeToolOwnerSigGroup_SIGNAL" STRING ;
BA_DEF_ SG_  "SeToolOwnerSigGroupID_SIGNAL" STRING ;
BA_DEF_ SG_  "SeToolName_SIGNAL" STRING ;
BA_DEF_ SG_  "SeToolItemID_SIGNAL" STRING ;
BA_DEF_ SG_  "SeToolAncestorID_SIGNAL" STRING ;
BA_DEF_ SG_  "SPN" INT 0 524287;
BA_DEF_ SG_  "Platform_VMCU1_Sig" ENUM  "No","Yes";
BA_DEF_ SG_  "NeedsUpdateBit" ENUM  "No","Yes";
BA_DEF_ SG_  "GenSigMaxLatency" INT 0 65535;
BA_DEF_ SG_  "GenSigILSupport" ENUM  "Yes","No";
BA_DEF_ BO_  "GenMsgRequestable" INT 0 1;
BA_DEF_ BO_  "GenMsgILSupport" ENUM  "No","Yes";
BA_DEF_ BO_  "DiagUUDTResponse" ENUM  "No","Yes";
BA_DEF_ BO_  "DiagState" ENUM  "No","Yes";
BA_DEF_ BO_  "DiagResponse" ENUM  "No","Yes";
BA_DEF_ BO_  "DiagRequest" ENUM  "No","Yes";
BA_DEF_ BO_  "DiagConnection" HEX 0 65535;
BA_DEF_ BO_  "CanTpFcFrameId" HEX 0 2147483647;
BA_DEF_ BO_  "CanTpBs" INT 0 255;
BA_DEF_ SG_  "SystemSignalLongSymbol" STRING ;
BA_DEF_REL_ BU_SG_REL_  "GenSigTimeoutTime" INT 0 65535;
BA_DEF_REL_ BU_SG_REL_  "GenSigFirstTimeoutTime" INT 0 65535;
BA_DEF_DEF_  "GenMsgStartDelayTime" 0;
BA_DEF_DEF_  "GenMsgDelayTime" 0;
BA_DEF_DEF_  "GenMsgNrOfRepetition" 0;
BA_DEF_DEF_  "GenMsgCycleTimeFast" 0;
BA_DEF_DEF_  "GenMsgCycleTime" 0;
BA_DEF_DEF_  "GenMsgSendType" "Cyclic";
BA_DEF_DEF_  "GenSigStartValue" 0;
BA_DEF_DEF_  "GenSigCycleTimeActive" 0;
BA_DEF_DEF_  "GenSigCycleTime" 0;
BA_DEF_DEF_  "GenSigSendType" "Cyclic";
BA_DEF_DEF_  "VFrameFormat" "ExtendedCAN";
BA_DEF_DEF_  "TpJ1939VarDlc" "No";
BA_DEF_DEF_  "SigType" "Default";
BA_DEF_DEF_  "SeToolVersion_SIGNAL" "";
BA_DEF_DEF_  "SeToolUniqueID_SIGNAL" "";
BA_DEF_DEF_  "SeToolOwnerSigGroup_SIGNAL" "";
BA_DEF_DEF_  "SeToolOwnerSigGroupID_SIGNAL" "";
BA_DEF_DEF_  "SeToolName_SIGNAL" "";
BA_DEF_DEF_  "SeToolItemID_SIGNAL" "";
BA_DEF_DEF_  "SeToolAncestorID_SIGNAL" "";
BA_DEF_DEF_  "SPN" 0;
BA_DEF_DEF_  "Platform_VMCU1_Sig" "No";
BA_DEF_DEF_  "NeedsUpdateBit" "No";
BA_DEF_DEF_  "GenSigMaxLatency" 0;
BA_DEF_DEF_  "GenSigILSupport" "Yes";
BA_DEF_DEF_  "GenMsgRequestable" 1;
BA_DEF_DEF_  "GenMsgILSupport" "Yes";
BA_DEF_DEF_  "DiagUUDTResponse" "No";
BA_DEF_DEF_  "DiagState" "No";
BA_DEF_DEF_  "DiagResponse" "No";
BA_DEF_DEF_  "DiagRequest" "No";
BA_DEF_DEF_  "DiagConnection" 0;
BA_DEF_DEF_  "CanTpFcFrameId" 2147483647;
BA_DEF_DEF_  "CanTpBs" 255;
BA_DEF_DEF_REL_ "GenSigTimeoutTime" 0;
BA_DEF_DEF_REL_ "GenSigFirstTimeoutTime" 0;
BA_DEF_DEF_  "SystemSignalLongSymbol" "";
BA_ "GenMsgSendType" BO_ 2348814097 7;
BA_ "GenMsgCycleTimeFast" BO_ 2348814097 50;
BA_ "GenMsgNrOfRepetition" BO_ 2348814097 3;
BA_ "VFrameFormat" BO_ 2348814097 3;
BA_ "GenMsgSendType" BO_ 2348814083 7;
BA_ "GenMsgCycleTimeFast" BO_ 2348814083 50;
BA_ "GenMsgNrOfRepetition" BO_ 2348814083 3;
BA_ "VFrameFormat" BO_ 2348814083 3;
BA_ "GenMsgSendType" BO_ 2348814091 7;
BA_ "GenMsgCycleTimeFast" BO_ 2348814091 50;
BA_ "GenMsgNrOfRepetition" BO_ 2348814091 3;
BA_ "VFrameFormat" BO_ 2348814091 3;
BA_ "VFrameFormat" BO_ 2566755587 3;
BA_ "GenMsgCycleTime" BO_ 2566846467 1000;
BA_ "GenMsgStartDelayTime" BO_ 2566846467 20;
BA_ "VFrameFormat" BO_ 2566846467 3;
BA_ "GenMsgILSupport" BO_ 2565603075 0;
BA_ "GenMsgSendType" BO_ 2565603075 8;
BA_ "VFrameFormat" BO_ 2565603075 3;
BA_ "GenMsgILSupport" BO_ 2565603310 0;
BA_ "GenMsgSendType" BO_ 2565603310 8;
BA_ "VFrameFormat" BO_ 2565603310 3;
BA_ "GenMsgILSupport" BO_ 2565603088 0;
BA_ "GenMsgSendType" BO_ 2565603088 8;
BA_ "VFrameFormat" BO_ 2565603088 3;
BA_ "GenMsgILSupport" BO_ 2565603077 0;
BA_ "VFrameFormat" BO_ 2565603077 3;
BA_ "GenMsgILSupport" BO_ 2565603087 0;
BA_ "GenMsgSendType" BO_ 2565603087 8;
BA_ "VFrameFormat" BO_ 2565603087 3;
BA_ "GenMsgILSupport" BO_ 2565603072 0;
BA_ "GenMsgSendType" BO_ 2565603072 8;
BA_ "VFrameFormat" BO_ 2565603072 3;
BA_ "GenMsgILSupport" BO_ 2565603083 0;
BA_ "GenMsgSendType" BO_ 2565603083 8;
BA_ "VFrameFormat" BO_ 2565603083 3;
BA_ "GenMsgILSupport" BO_ 2565603133 0;
BA_ "GenMsgSendType" BO_ 2565603133 8;
BA_ "VFrameFormat" BO_ 2565603133 3;
BA_ "GenMsgILSupport" BO_ 2565668611 0;
BA_ "GenMsgSendType" BO_ 2565668611 8;
BA_ "VFrameFormat" BO_ 2565668611 3;
BA_ "GenMsgILSupport" BO_ 2565668846 0;
BA_ "GenMsgSendType" BO_ 2565668846 8;
BA_ "VFrameFormat" BO_ 2565668846 3;
BA_ "GenMsgILSupport" BO_ 2565668624 0;
BA_ "GenMsgSendType" BO_ 2565668624 8;
BA_ "VFrameFormat" BO_ 2565668624 3;
BA_ "GenMsgILSupport" BO_ 2565668613 0;
BA_ "VFrameFormat" BO_ 2565668613 3;
BA_ "GenMsgILSupport" BO_ 2565668623 0;
BA_ "GenMsgSendType" BO_ 2565668623 8;
BA_ "VFrameFormat" BO_ 2565668623 3;
BA_ "GenMsgILSupport" BO_ 2565668608 0;
BA_ "GenMsgSendType" BO_ 2565668608 8;
BA_ "VFrameFormat" BO_ 2565668608 3;
BA_ "GenMsgILSupport" BO_ 2565668619 0;
BA_ "GenMsgSendType" BO_ 2565668619 8;
BA_ "VFrameFormat" BO_ 2565668619 3;
BA_ "GenMsgILSupport" BO_ 2565668669 0;
BA_ "GenMsgSendType" BO_ 2565668669 8;
BA_ "VFrameFormat" BO_ 2565668669 3;
BA_ "TpJ1939VarDlc" BO_ 2633844483 1;
BA_ "VFrameFormat" BO_ 2633844483 3;
BA_ "GenMsgCycleTime" BO_ 2566882307 95;
BA_ "GenMsgStartDelayTime" BO_ 2566882307 5;
BA_ "VFrameFormat" BO_ 2566882307 3;
BA_ "GenMsgCycleTime" BO_ 2566842094 1000;
BA_ "VFrameFormat" BO_ 2566842094 3;
BA_ "GenMsgCycleTime" BO_ 2566841879 250;
BA_ "GenMsgStartDelayTime" BO_ 2566841879 50;
BA_ "VFrameFormat" BO_ 2566841879 3;
BA_ "GenMsgSendType" BO_ 2564156951 8;
BA_ "GenMsgDelayTime" BO_ 2564156951 100;
BA_ "VFrameFormat" BO_ 2564156951 3;
BA_ "GenMsgCycleTime" BO_ 2365484270 20;
BA_ "VFrameFormat" BO_ 2365484270 3;
BA_ "TpJ1939VarDlc" BO_ 2566840835 1;
BA_ "VFrameFormat" BO_ 2566840835 3;
BA_ "GenMsgCycleTime" BO_ 2348876549 50;
BA_ "VFrameFormat" BO_ 2348876549 3;
BA_ "TpJ1939VarDlc" BO_ 2566838787 1;
BA_ "VFrameFormat" BO_ 2566838787 3;
BA_ "TpJ1939VarDlc" BO_ 2566838789 1;
BA_ "VFrameFormat" BO_ 2566838789 3;
BA_ "VFrameFormat" BO_ 2566862055 3;
BA_ "VFrameFormat" BO_ 2566862311 3;
BA_ "VFrameFormat" BO_ 2566861799 3;
BA_ "VFrameFormat" BO_ 2566861543 3;
BA_ "VFrameFormat" BO_ 2566861287 3;
BA_ "VFrameFormat" BO_ 2566862567 3;
BA_ "VFrameFormat" BO_ 2565537539 3;
BA_ "GenMsgCycleTime" BO_ 2565533233 30000;
BA_ "GenMsgStartDelayTime" BO_ 2565533233 25;
BA_ "VFrameFormat" BO_ 2565533233 3;
BA_ "VFrameFormat" BO_ 2565473539 3;
BA_ "GenMsgSendType" BO_ 2631855639 8;
BA_ "GenMsgDelayTime" BO_ 2631855639 200;
BA_ "VFrameFormat" BO_ 2631855639 3;
BA_ "GenMsgCycleTime" BO_ 2499792656 150;
BA_ "GenMsgStartDelayTime" BO_ 2499792656 10;
BA_ "VFrameFormat" BO_ 2499792656 3;
BA_ "GenMsgCycleTime" BO_ 2566840592 5000;
BA_ "GenMsgStartDelayTime" BO_ 2566840592 25;
BA_ "VFrameFormat" BO_ 2566840592 3;
BA_ "GenMsgCycleTime" BO_ 2566840591 5000;
BA_ "GenMsgStartDelayTime" BO_ 2566840591 555;
BA_ "VFrameFormat" BO_ 2566840591 3;
BA_ "GenMsgCycleTime" BO_ 2566899694 60000;
BA_ "GenMsgDelayTime" BO_ 2566899694 995;
BA_ "VFrameFormat" BO_ 2566899694 3;
BA_ "GenMsgCycleTime" BO_ 2566898926 10000;
BA_ "GenMsgDelayTime" BO_ 2566898926 995;
BA_ "VFrameFormat" BO_ 2566898926 3;
BA_ "GenMsgCycleTime" BO_ 2566898670 60000;
BA_ "GenMsgDelayTime" BO_ 2566898670 995;
BA_ "VFrameFormat" BO_ 2566898670 3;
BA_ "VFrameFormat" BO_ 2565800709 3;
BA_ "VFrameFormat" BO_ 2565801219 3;
BA_ "DiagConnection" BO_ 2671833838 62190;
BA_ "DiagResponse" BO_ 2671833838 1;
BA_ "GenMsgILSupport" BO_ 2671833838 0;
BA_ "GenMsgSendType" BO_ 2671833838 8;
BA_ "VFrameFormat" BO_ 2671833838 3;
BA_ "DiagConnection" BO_ 2671833640 61992;
BA_ "DiagResponse" BO_ 2671833640 1;
BA_ "GenMsgILSupport" BO_ 2671833640 0;
BA_ "GenMsgSendType" BO_ 2671833640 8;
BA_ "VFrameFormat" BO_ 2671833640 3;
BA_ "DiagConnection" BO_ 2671833617 61969;
BA_ "DiagResponse" BO_ 2671833617 1;
BA_ "GenMsgILSupport" BO_ 2671833617 0;
BA_ "GenMsgSendType" BO_ 2671833617 8;
BA_ "VFrameFormat" BO_ 2671833617 3;
BA_ "DiagConnection" BO_ 2671833361 61713;
BA_ "DiagResponse" BO_ 2671833361 1;
BA_ "GenMsgILSupport" BO_ 2671833361 0;
BA_ "GenMsgSendType" BO_ 2671833361 8;
BA_ "VFrameFormat" BO_ 2671833361 3;
BA_ "DiagConnection" BO_ 2671832818 62190;
BA_ "DiagRequest" BO_ 2671832818 1;
BA_ "GenMsgILSupport" BO_ 2671832818 0;
BA_ "GenMsgSendType" BO_ 2671832818 8;
BA_ "VFrameFormat" BO_ 2671832818 3;
BA_ "DiagConnection" BO_ 2671782130 61992;
BA_ "DiagRequest" BO_ 2671782130 1;
BA_ "GenMsgILSupport" BO_ 2671782130 0;
BA_ "GenMsgSendType" BO_ 2671782130 8;
BA_ "VFrameFormat" BO_ 2671782130 3;
BA_ "DiagConnection" BO_ 2671776242 61969;
BA_ "DiagRequest" BO_ 2671776242 1;
BA_ "GenMsgILSupport" BO_ 2671776242 0;
BA_ "GenMsgSendType" BO_ 2671776242 8;
BA_ "VFrameFormat" BO_ 2671776242 3;
BA_ "DiagConnection" BO_ 2671776241 61713;
BA_ "DiagRequest" BO_ 2671776241 1;
BA_ "GenMsgILSupport" BO_ 2671776241 0;
BA_ "GenMsgSendType" BO_ 2671776241 8;
BA_ "VFrameFormat" BO_ 2671776241 3;
BA_ "GenMsgCycleTime" BO_ 2566759457 100;
BA_ "VFrameFormat" BO_ 2566759457 3;
BA_ "GenMsgCycleTime" BO_ 2566759427 100;
BA_ "GenMsgStartDelayTime" BO_ 2566759427 20;
BA_ "VFrameFormat" BO_ 2566759427 3;
BA_ "DiagConnection" BO_ 2671850481 61713;
BA_ "DiagState" BO_ 2671850481 1;
BA_ "GenMsgILSupport" BO_ 2671850481 0;
BA_ "GenMsgSendType" BO_ 2671850481 8;
BA_ "VFrameFormat" BO_ 2671850481 3;
BA_ "GenMsgCycleTime" BO_ 2566844928 100;
BA_ "GenMsgStartDelayTime" BO_ 2566844928 15;
BA_ "VFrameFormat" BO_ 2566844928 3;
BA_ "GenMsgSendType" BO_ 2564428270 8;
BA_ "VFrameFormat" BO_ 2564428270 3;
BA_ "GenMsgSendType" BO_ 2564484625 8;
BA_ "VFrameFormat" BO_ 2564484625 3;
BA_ "TpJ1939VarDlc" BO_ 2633861635 1;
BA_ "VFrameFormat" BO_ 2633861635 3;
BA_ "DiagConnection" BO_ 2671902708 62467;
BA_ "DiagState" BO_ 2671902708 1;
BA_ "GenMsgILSupport" BO_ 2671902708 0;
BA_ "GenMsgSendType" BO_ 2671902708 8;
BA_ "VFrameFormat" BO_ 2671902708 3;
BA_ "GenMsgCycleTime" BO_ 2566825472 500;
BA_ "VFrameFormat" BO_ 2566825472 3;
BA_ "GenMsgCycleTime" BO_ 2566845952 500;
BA_ "VFrameFormat" BO_ 2566845952 3;
BA_ "GenMsgCycleTime" BO_ 2298372875 20;
BA_ "VFrameFormat" BO_ 2298372875 3;
BA_ "GenMsgCycleTime" BO_ 2566719744 1000;
BA_ "VFrameFormat" BO_ 2566719744 3;
BA_ "GenMsgCycleTime" BO_ 2566841600 5000;
BA_ "GenMsgStartDelayTime" BO_ 2566841600 345;
BA_ "VFrameFormat" BO_ 2566841600 3;
BA_ "GenMsgCycleTime" BO_ 2499788567 75;
BA_ "GenMsgStartDelayTime" BO_ 2499788567 5;
BA_ "VFrameFormat" BO_ 2499788567 3;
BA_ "GenSigSendType" SG_ 2348814097 TSC1EMSrVMCU_EnRSpdCtrlC 7;
BA_ "GenSigCycleTime" SG_ 2348814097 TSC1EMSrVMCU_EnRSpdCtrlC 100;
BA_ "GenSigCycleTimeActive" SG_ 2348814097 TSC1EMSrVMCU_EnRSpdCtrlC 100;
BA_ "Platform_VMCU1_Sig" SG_ 2348814097 TSC1EMSrVMCU_EnRSpdCtrlC 1;
BA_ "SPN" SG_ 2348814097 TSC1EMSrVMCU_EnRSpdCtrlC 696;
BA_ "SeToolAncestorID_SIGNAL" SG_ 2348814097 TSC1EMSrVMCU_EnRSpdCtrlC "x0000001D042564C9";
BA_ "SeToolItemID_SIGNAL" SG_ 2348814097 TSC1EMSrVMCU_EnRSpdCtrlC "x0000001D042564C9";
BA_ "SeToolName_SIGNAL" SG_ 2348814097 TSC1EMSrVMCU_EnRSpdCtrlC "EnRSpdCtrlC";
BA_ "SeToolOwnerSigGroupID_SIGNAL" SG_ 2348814097 TSC1EMSrVMCU_EnRSpdCtrlC "x0000001D043FB6F7";
BA_ "SeToolOwnerSigGroup_SIGNAL" SG_ 2348814097 TSC1EMSrVMCU_EnRSpdCtrlC "TSC1EMSrVMCU";
BA_ "SeToolVersion_SIGNAL" SG_ 2348814097 TSC1EMSrVMCU_EnRSpdCtrlC "1";
BA_ "GenSigSendType" SG_ 2348814097 TSC1EMSrVMCU_EnRTrqTrqLm 7;
BA_ "GenSigCycleTime" SG_ 2348814097 TSC1EMSrVMCU_EnRTrqTrqLm 100;
BA_ "GenSigCycleTimeActive" SG_ 2348814097 TSC1EMSrVMCU_EnRTrqTrqLm 100;
BA_ "GenSigStartValue" SG_ 2348814097 TSC1EMSrVMCU_EnRTrqTrqLm 255;
BA_ "Platform_VMCU1_Sig" SG_ 2348814097 TSC1EMSrVMCU_EnRTrqTrqLm 1;
BA_ "SPN" SG_ 2348814097 TSC1EMSrVMCU_EnRTrqTrqLm 518;
BA_ "SeToolAncestorID_SIGNAL" SG_ 2348814097 TSC1EMSrVMCU_EnRTrqTrqLm "x0000001D042564D4";
BA_ "SeToolItemID_SIGNAL" SG_ 2348814097 TSC1EMSrVMCU_EnRTrqTrqLm "x0000001D042564D4";
BA_ "SeToolName_SIGNAL" SG_ 2348814097 TSC1EMSrVMCU_EnRTrqTrqLm "EnRTrqTrqLm";
BA_ "SeToolOwnerSigGroupID_SIGNAL" SG_ 2348814097 TSC1EMSrVMCU_EnRTrqTrqLm "x0000001D043FB6F7";
BA_ "SeToolOwnerSigGroup_SIGNAL" SG_ 2348814097 TSC1EMSrVMCU_EnRTrqTrqLm "TSC1EMSrVMCU";
BA_ "SeToolVersion_SIGNAL" SG_ 2348814097 TSC1EMSrVMCU_EnRTrqTrqLm "1";
BA_ "GenSigSendType" SG_ 2348814097 TSC1EMSrVMCU_OvrdCtrlMPr 7;
BA_ "GenSigCycleTime" SG_ 2348814097 TSC1EMSrVMCU_OvrdCtrlMPr 100;
BA_ "GenSigCycleTimeActive" SG_ 2348814097 TSC1EMSrVMCU_OvrdCtrlMPr 100;
BA_ "GenSigStartValue" SG_ 2348814097 TSC1EMSrVMCU_OvrdCtrlMPr 3;
BA_ "Platform_VMCU1_Sig" SG_ 2348814097 TSC1EMSrVMCU_OvrdCtrlMPr 1;
BA_ "SPN" SG_ 2348814097 TSC1EMSrVMCU_OvrdCtrlMPr 897;
BA_ "SeToolAncestorID_SIGNAL" SG_ 2348814097 TSC1EMSrVMCU_OvrdCtrlMPr "x0000001D042564CE";
BA_ "SeToolItemID_SIGNAL" SG_ 2348814097 TSC1EMSrVMCU_OvrdCtrlMPr "x0000001D042564CE";
BA_ "SeToolName_SIGNAL" SG_ 2348814097 TSC1EMSrVMCU_OvrdCtrlMPr "OvrdCtrlMPr";
BA_ "SeToolOwnerSigGroupID_SIGNAL" SG_ 2348814097 TSC1EMSrVMCU_OvrdCtrlMPr "x0000001D043FB6F7";
BA_ "SeToolOwnerSigGroup_SIGNAL" SG_ 2348814097 TSC1EMSrVMCU_OvrdCtrlMPr "TSC1EMSrVMCU";
BA_ "SeToolVersion_SIGNAL" SG_ 2348814097 TSC1EMSrVMCU_OvrdCtrlMPr "1";
BA_ "GenSigSendType" SG_ 2348814097 TSC1EMSrVMCU_EnRSpdSpdLm 7;
BA_ "GenSigCycleTime" SG_ 2348814097 TSC1EMSrVMCU_EnRSpdSpdLm 100;
BA_ "GenSigCycleTimeActive" SG_ 2348814097 TSC1EMSrVMCU_EnRSpdSpdLm 100;
BA_ "GenSigStartValue" SG_ 2348814097 TSC1EMSrVMCU_EnRSpdSpdLm 65535;
BA_ "Platform_VMCU1_Sig" SG_ 2348814097 TSC1EMSrVMCU_EnRSpdSpdLm 1;
BA_ "SPN" SG_ 2348814097 TSC1EMSrVMCU_EnRSpdSpdLm 898;
BA_ "SeToolAncestorID_SIGNAL" SG_ 2348814097 TSC1EMSrVMCU_EnRSpdSpdLm "x0000001D042564D1";
BA_ "SeToolItemID_SIGNAL" SG_ 2348814097 TSC1EMSrVMCU_EnRSpdSpdLm "x0000001D042564D1";
BA_ "SeToolName_SIGNAL" SG_ 2348814097 TSC1EMSrVMCU_EnRSpdSpdLm "EnRSpdSpdLm";
BA_ "SeToolOwnerSigGroupID_SIGNAL" SG_ 2348814097 TSC1EMSrVMCU_EnRSpdSpdLm "x0000001D043FB6F7";
BA_ "SeToolOwnerSigGroup_SIGNAL" SG_ 2348814097 TSC1EMSrVMCU_EnRSpdSpdLm "TSC1EMSrVMCU";
BA_ "SeToolVersion_SIGNAL" SG_ 2348814097 TSC1EMSrVMCU_EnRSpdSpdLm "1";
BA_ "GenSigSendType" SG_ 2348814097 TSC1EMSrVMCU_EnOvrdCtrlM 6;
BA_ "Platform_VMCU1_Sig" SG_ 2348814097 TSC1EMSrVMCU_EnOvrdCtrlM 1;
BA_ "SPN" SG_ 2348814097 TSC1EMSrVMCU_EnOvrdCtrlM 695;
BA_ "SeToolAncestorID_SIGNAL" SG_ 2348814097 TSC1EMSrVMCU_EnOvrdCtrlM "x0000001D042564C7";
BA_ "SeToolItemID_SIGNAL" SG_ 2348814097 TSC1EMSrVMCU_EnOvrdCtrlM "x0000001D042564C7";
BA_ "SeToolName_SIGNAL" SG_ 2348814097 TSC1EMSrVMCU_EnOvrdCtrlM "EnOvrdCtrlM";
BA_ "SeToolOwnerSigGroupID_SIGNAL" SG_ 2348814097 TSC1EMSrVMCU_EnOvrdCtrlM "x0000001D043FB6F7";
BA_ "SeToolOwnerSigGroup_SIGNAL" SG_ 2348814097 TSC1EMSrVMCU_EnOvrdCtrlM "TSC1EMSrVMCU";
BA_ "SeToolVersion_SIGNAL" SG_ 2348814097 TSC1EMSrVMCU_EnOvrdCtrlM "1";
BA_ "GenSigSendType" SG_ 2348814083 TSC1EMSrTECU_OvrdCtrlMPr 7;
BA_ "GenSigCycleTime" SG_ 2348814083 TSC1EMSrTECU_OvrdCtrlMPr 100;
BA_ "GenSigCycleTimeActive" SG_ 2348814083 TSC1EMSrTECU_OvrdCtrlMPr 100;
BA_ "GenSigStartValue" SG_ 2348814083 TSC1EMSrTECU_OvrdCtrlMPr 3;
BA_ "Platform_VMCU1_Sig" SG_ 2348814083 TSC1EMSrTECU_OvrdCtrlMPr 1;
BA_ "SPN" SG_ 2348814083 TSC1EMSrTECU_OvrdCtrlMPr 897;
BA_ "SeToolAncestorID_SIGNAL" SG_ 2348814083 TSC1EMSrTECU_OvrdCtrlMPr "x0000001D042564CE";
BA_ "SeToolItemID_SIGNAL" SG_ 2348814083 TSC1EMSrTECU_OvrdCtrlMPr "x0000001D042564CE";
BA_ "SeToolName_SIGNAL" SG_ 2348814083 TSC1EMSrTECU_OvrdCtrlMPr "OvrdCtrlMPr";
BA_ "SeToolOwnerSigGroupID_SIGNAL" SG_ 2348814083 TSC1EMSrTECU_OvrdCtrlMPr "x0000001D043D766D";
BA_ "SeToolOwnerSigGroup_SIGNAL" SG_ 2348814083 TSC1EMSrTECU_OvrdCtrlMPr "TSC1_TECU_EMS_Ret";
BA_ "SeToolVersion_SIGNAL" SG_ 2348814083 TSC1EMSrTECU_OvrdCtrlMPr "1";
BA_ "GenSigSendType" SG_ 2348814083 TSC1EMSrTECU_EnRSpdCtrlC 7;
BA_ "GenSigCycleTime" SG_ 2348814083 TSC1EMSrTECU_EnRSpdCtrlC 100;
BA_ "GenSigCycleTimeActive" SG_ 2348814083 TSC1EMSrTECU_EnRSpdCtrlC 100;
BA_ "Platform_VMCU1_Sig" SG_ 2348814083 TSC1EMSrTECU_EnRSpdCtrlC 1;
BA_ "SPN" SG_ 2348814083 TSC1EMSrTECU_EnRSpdCtrlC 696;
BA_ "SeToolAncestorID_SIGNAL" SG_ 2348814083 TSC1EMSrTECU_EnRSpdCtrlC "x0000001D042564C9";
BA_ "SeToolItemID_SIGNAL" SG_ 2348814083 TSC1EMSrTECU_EnRSpdCtrlC "x0000001D042564C9";
BA_ "SeToolName_SIGNAL" SG_ 2348814083 TSC1EMSrTECU_EnRSpdCtrlC "EnRSpdCtrlC";
BA_ "SeToolOwnerSigGroupID_SIGNAL" SG_ 2348814083 TSC1EMSrTECU_EnRSpdCtrlC "x0000001D043D766D";
BA_ "SeToolOwnerSigGroup_SIGNAL" SG_ 2348814083 TSC1EMSrTECU_EnRSpdCtrlC "TSC1_TECU_EMS_Ret";
BA_ "SeToolVersion_SIGNAL" SG_ 2348814083 TSC1EMSrTECU_EnRSpdCtrlC "1";
BA_ "GenSigSendType" SG_ 2348814083 TSC1EMSrTECU_EnOvrdCtrlM 6;
BA_ "Platform_VMCU1_Sig" SG_ 2348814083 TSC1EMSrTECU_EnOvrdCtrlM 1;
BA_ "SPN" SG_ 2348814083 TSC1EMSrTECU_EnOvrdCtrlM 695;
BA_ "SeToolAncestorID_SIGNAL" SG_ 2348814083 TSC1EMSrTECU_EnOvrdCtrlM "x0000001D042564C7";
BA_ "SeToolItemID_SIGNAL" SG_ 2348814083 TSC1EMSrTECU_EnOvrdCtrlM "x0000001D042564C7";
BA_ "SeToolName_SIGNAL" SG_ 2348814083 TSC1EMSrTECU_EnOvrdCtrlM "EnOvrdCtrlM";
BA_ "SeToolOwnerSigGroupID_SIGNAL" SG_ 2348814083 TSC1EMSrTECU_EnOvrdCtrlM "x0000001D043D766D";
BA_ "SeToolOwnerSigGroup_SIGNAL" SG_ 2348814083 TSC1EMSrTECU_EnOvrdCtrlM "TSC1_TECU_EMS_Ret";
BA_ "SeToolVersion_SIGNAL" SG_ 2348814083 TSC1EMSrTECU_EnOvrdCtrlM "1";
BA_ "GenSigSendType" SG_ 2348814083 TSC1EMSrTECU_EnRTrqTrqLm 7;
BA_ "GenSigCycleTime" SG_ 2348814083 TSC1EMSrTECU_EnRTrqTrqLm 100;
BA_ "GenSigCycleTimeActive" SG_ 2348814083 TSC1EMSrTECU_EnRTrqTrqLm 100;
BA_ "GenSigStartValue" SG_ 2348814083 TSC1EMSrTECU_EnRTrqTrqLm 255;
BA_ "Platform_VMCU1_Sig" SG_ 2348814083 TSC1EMSrTECU_EnRTrqTrqLm 1;
BA_ "SPN" SG_ 2348814083 TSC1EMSrTECU_EnRTrqTrqLm 518;
BA_ "SeToolAncestorID_SIGNAL" SG_ 2348814083 TSC1EMSrTECU_EnRTrqTrqLm "x0000001D042564D4";
BA_ "SeToolItemID_SIGNAL" SG_ 2348814083 TSC1EMSrTECU_EnRTrqTrqLm "x0000001D042564D4";
BA_ "SeToolName_SIGNAL" SG_ 2348814083 TSC1EMSrTECU_EnRTrqTrqLm "EnRTrqTrqLm";
BA_ "SeToolOwnerSigGroupID_SIGNAL" SG_ 2348814083 TSC1EMSrTECU_EnRTrqTrqLm "x0000001D043D766D";
BA_ "SeToolOwnerSigGroup_SIGNAL" SG_ 2348814083 TSC1EMSrTECU_EnRTrqTrqLm "TSC1_TECU_EMS_Ret";
BA_ "SeToolVersion_SIGNAL" SG_ 2348814083 TSC1EMSrTECU_EnRTrqTrqLm "1";
BA_ "GenSigSendType" SG_ 2348814083 TSC1EMSrTECU_EnRSpdSpdLm 7;
BA_ "GenSigCycleTime" SG_ 2348814083 TSC1EMSrTECU_EnRSpdSpdLm 100;
BA_ "GenSigCycleTimeActive" SG_ 2348814083 TSC1EMSrTECU_EnRSpdSpdLm 100;
BA_ "GenSigStartValue" SG_ 2348814083 TSC1EMSrTECU_EnRSpdSpdLm 65535;
BA_ "Platform_VMCU1_Sig" SG_ 2348814083 TSC1EMSrTECU_EnRSpdSpdLm 1;
BA_ "SPN" SG_ 2348814083 TSC1EMSrTECU_EnRSpdSpdLm 898;
BA_ "SeToolAncestorID_SIGNAL" SG_ 2348814083 TSC1EMSrTECU_EnRSpdSpdLm "x0000001D042564D1";
BA_ "SeToolItemID_SIGNAL" SG_ 2348814083 TSC1EMSrTECU_EnRSpdSpdLm "x0000001D042564D1";
BA_ "SeToolName_SIGNAL" SG_ 2348814083 TSC1EMSrTECU_EnRSpdSpdLm "EnRSpdSpdLm";
BA_ "SeToolOwnerSigGroupID_SIGNAL" SG_ 2348814083 TSC1EMSrTECU_EnRSpdSpdLm "x0000001D043D766D";
BA_ "SeToolOwnerSigGroup_SIGNAL" SG_ 2348814083 TSC1EMSrTECU_EnRSpdSpdLm "TSC1_TECU_EMS_Ret";
BA_ "SeToolVersion_SIGNAL" SG_ 2348814083 TSC1EMSrTECU_EnRSpdSpdLm "1";
BA_ "GenSigSendType" SG_ 2348814091 TSC1EMSrABS_EnRTrqTrqLm 7;
BA_ "GenSigCycleTime" SG_ 2348814091 TSC1EMSrABS_EnRTrqTrqLm 100;
BA_ "GenSigCycleTimeActive" SG_ 2348814091 TSC1EMSrABS_EnRTrqTrqLm 100;
BA_ "GenSigStartValue" SG_ 2348814091 TSC1EMSrABS_EnRTrqTrqLm 255;
BA_ "Platform_VMCU1_Sig" SG_ 2348814091 TSC1EMSrABS_EnRTrqTrqLm 1;
BA_ "SPN" SG_ 2348814091 TSC1EMSrABS_EnRTrqTrqLm 518;
BA_ "SeToolAncestorID_SIGNAL" SG_ 2348814091 TSC1EMSrABS_EnRTrqTrqLm "x0000001D042564D4";
BA_ "SeToolItemID_SIGNAL" SG_ 2348814091 TSC1EMSrABS_EnRTrqTrqLm "x0000001D042564D4";
BA_ "SeToolName_SIGNAL" SG_ 2348814091 TSC1EMSrABS_EnRTrqTrqLm "EnRTrqTrqLm";
BA_ "SeToolOwnerSigGroupID_SIGNAL" SG_ 2348814091 TSC1EMSrABS_EnRTrqTrqLm "x0000001D043D6A13";
BA_ "SeToolOwnerSigGroup_SIGNAL" SG_ 2348814091 TSC1EMSrABS_EnRTrqTrqLm "TSC1EMSrABS";
BA_ "SeToolVersion_SIGNAL" SG_ 2348814091 TSC1EMSrABS_EnRTrqTrqLm "1";
BA_ "GenSigSendType" SG_ 2348814091 TSC1EMSrABS_EnRSpdCtrlC 7;
BA_ "GenSigCycleTime" SG_ 2348814091 TSC1EMSrABS_EnRSpdCtrlC 100;
BA_ "GenSigCycleTimeActive" SG_ 2348814091 TSC1EMSrABS_EnRSpdCtrlC 100;
BA_ "Platform_VMCU1_Sig" SG_ 2348814091 TSC1EMSrABS_EnRSpdCtrlC 1;
BA_ "SPN" SG_ 2348814091 TSC1EMSrABS_EnRSpdCtrlC 696;
BA_ "SeToolAncestorID_SIGNAL" SG_ 2348814091 TSC1EMSrABS_EnRSpdCtrlC "x0000001D042564C9";
BA_ "SeToolItemID_SIGNAL" SG_ 2348814091 TSC1EMSrABS_EnRSpdCtrlC "x0000001D042564C9";
BA_ "SeToolName_SIGNAL" SG_ 2348814091 TSC1EMSrABS_EnRSpdCtrlC "EnRSpdCtrlC";
BA_ "SeToolOwnerSigGroupID_SIGNAL" SG_ 2348814091 TSC1EMSrABS_EnRSpdCtrlC "x0000001D043D6A13";
BA_ "SeToolOwnerSigGroup_SIGNAL" SG_ 2348814091 TSC1EMSrABS_EnRSpdCtrlC "TSC1EMSrABS";
BA_ "SeToolVersion_SIGNAL" SG_ 2348814091 TSC1EMSrABS_EnRSpdCtrlC "1";
BA_ "GenSigSendType" SG_ 2348814091 TSC1EMSrABS_OvrdCtrlMPr 7;
BA_ "GenSigCycleTime" SG_ 2348814091 TSC1EMSrABS_OvrdCtrlMPr 100;
BA_ "GenSigCycleTimeActive" SG_ 2348814091 TSC1EMSrABS_OvrdCtrlMPr 100;
BA_ "GenSigStartValue" SG_ 2348814091 TSC1EMSrABS_OvrdCtrlMPr 3;
BA_ "Platform_VMCU1_Sig" SG_ 2348814091 TSC1EMSrABS_OvrdCtrlMPr 1;
BA_ "SPN" SG_ 2348814091 TSC1EMSrABS_OvrdCtrlMPr 897;
BA_ "SeToolAncestorID_SIGNAL" SG_ 2348814091 TSC1EMSrABS_OvrdCtrlMPr "x0000001D042564CE";
BA_ "SeToolItemID_SIGNAL" SG_ 2348814091 TSC1EMSrABS_OvrdCtrlMPr "x0000001D042564CE";
BA_ "SeToolName_SIGNAL" SG_ 2348814091 TSC1EMSrABS_OvrdCtrlMPr "OvrdCtrlMPr";
BA_ "SeToolOwnerSigGroupID_SIGNAL" SG_ 2348814091 TSC1EMSrABS_OvrdCtrlMPr "x0000001D043D6A13";
BA_ "SeToolOwnerSigGroup_SIGNAL" SG_ 2348814091 TSC1EMSrABS_OvrdCtrlMPr "TSC1EMSrABS";
BA_ "SeToolVersion_SIGNAL" SG_ 2348814091 TSC1EMSrABS_OvrdCtrlMPr "1";
BA_ "GenSigSendType" SG_ 2348814091 TSC1EMSrABS_EnOvrdCtrlM 6;
BA_ "Platform_VMCU1_Sig" SG_ 2348814091 TSC1EMSrABS_EnOvrdCtrlM 1;
BA_ "SPN" SG_ 2348814091 TSC1EMSrABS_EnOvrdCtrlM 695;
BA_ "SeToolAncestorID_SIGNAL" SG_ 2348814091 TSC1EMSrABS_EnOvrdCtrlM "x0000001D042564C7";
BA_ "SeToolItemID_SIGNAL" SG_ 2348814091 TSC1EMSrABS_EnOvrdCtrlM "x0000001D042564C7";
BA_ "SeToolName_SIGNAL" SG_ 2348814091 TSC1EMSrABS_EnOvrdCtrlM "EnOvrdCtrlM";
BA_ "SeToolOwnerSigGroupID_SIGNAL" SG_ 2348814091 TSC1EMSrABS_EnOvrdCtrlM "x0000001D043D6A13";
BA_ "SeToolOwnerSigGroup_SIGNAL" SG_ 2348814091 TSC1EMSrABS_EnOvrdCtrlM "TSC1EMSrABS";
BA_ "SeToolVersion_SIGNAL" SG_ 2348814091 TSC1EMSrABS_EnOvrdCtrlM "1";
BA_ "GenSigSendType" SG_ 2348814091 TSC1EMSrABS_EnRSpdSpdLm 7;
BA_ "GenSigCycleTime" SG_ 2348814091 TSC1EMSrABS_EnRSpdSpdLm 100;
BA_ "GenSigCycleTimeActive" SG_ 2348814091 TSC1EMSrABS_EnRSpdSpdLm 100;
BA_ "GenSigStartValue" SG_ 2348814091 TSC1EMSrABS_EnRSpdSpdLm 65535;
BA_ "Platform_VMCU1_Sig" SG_ 2348814091 TSC1EMSrABS_EnRSpdSpdLm 1;
BA_ "SPN" SG_ 2348814091 TSC1EMSrABS_EnRSpdSpdLm 898;
BA_ "SeToolAncestorID_SIGNAL" SG_ 2348814091 TSC1EMSrABS_EnRSpdSpdLm "x0000001D042564D1";
BA_ "SeToolItemID_SIGNAL" SG_ 2348814091 TSC1EMSrABS_EnRSpdSpdLm "x0000001D042564D1";
BA_ "SeToolName_SIGNAL" SG_ 2348814091 TSC1EMSrABS_EnRSpdSpdLm "EnRSpdSpdLm";
BA_ "SeToolOwnerSigGroupID_SIGNAL" SG_ 2348814091 TSC1EMSrABS_EnRSpdSpdLm "x0000001D043D6A13";
BA_ "SeToolOwnerSigGroup_SIGNAL" SG_ 2348814091 TSC1EMSrABS_EnRSpdSpdLm "TSC1EMSrABS";
BA_ "SeToolVersion_SIGNAL" SG_ 2348814091 TSC1EMSrABS_EnRSpdSpdLm "1";
BA_ "GenSigCycleTime" SG_ 2566846467 TransmissionOilTemp_ISig_3 100;
BA_ "GenSigCycleTimeActive" SG_ 2566846467 TransmissionOilTemp_ISig_3 100;
BA_ "GenSigStartValue" SG_ 2566846467 TransmissionOilTemp_ISig_3 65535;
BA_ "Platform_VMCU1_Sig" SG_ 2566846467 TransmissionOilTemp_ISig_3 1;
BA_ "SPN" SG_ 2566846467 TransmissionOilTemp_ISig_3 177;
BA_ "SeToolAncestorID_SIGNAL" SG_ 2566846467 TransmissionOilTemp_ISig_3 "x0000001D04131792";
BA_ "SeToolItemID_SIGNAL" SG_ 2566846467 TransmissionOilTemp_ISig_3 "x0000001D04131792";
BA_ "SeToolName_SIGNAL" SG_ 2566846467 TransmissionOilTemp_ISig_3 "TransmissionOilTemp";
BA_ "SeToolVersion_SIGNAL" SG_ 2566846467 TransmissionOilTemp_ISig_3 "1";
BA_ "GenSigCycleTime" SG_ 2566846467 TransmissionOilLevel_ISig_3 100;
BA_ "GenSigCycleTimeActive" SG_ 2566846467 TransmissionOilLevel_ISig_3 100;
BA_ "GenSigStartValue" SG_ 2566846467 TransmissionOilLevel_ISig_3 255;
BA_ "Platform_VMCU1_Sig" SG_ 2566846467 TransmissionOilLevel_ISig_3 1;
BA_ "SPN" SG_ 2566846467 TransmissionOilLevel_ISig_3 124;
BA_ "GenSigSendType" SG_ 2565603075 TPDT_SeqNo_TECU 7;
BA_ "Platform_VMCU1_Sig" SG_ 2565603075 TPDT_SeqNo_TECU 1;
BA_ "GenSigSendType" SG_ 2565603310 TPDT_SeqNo_TACHO 7;
BA_ "Platform_VMCU1_Sig" SG_ 2565603310 TPDT_SeqNo_TACHO 1;
BA_ "GenSigSendType" SG_ 2565603088 TPDT_SeqNo_RECU 7;
BA_ "Platform_VMCU1_Sig" SG_ 2565603088 TPDT_SeqNo_RECU 1;
BA_ "GenSigSendType" SG_ 2565603087 TPDT_SeqNo_EMSRet 7;
BA_ "Platform_VMCU1_Sig" SG_ 2565603087 TPDT_SeqNo_EMSRet 1;
BA_ "GenSigSendType" SG_ 2565603072 TPDT_SeqNo_EMS 7;
BA_ "Platform_VMCU1_Sig" SG_ 2565603072 TPDT_SeqNo_EMS 1;
BA_ "GenSigSendType" SG_ 2565603083 TPDT_SeqNo_EBS 7;
BA_ "GenSigSendType" SG_ 2565603133 TPDT_SeqNo_ACM 7;
BA_ "Platform_VMCU1_Sig" SG_ 2565603133 TPDT_SeqNo_ACM 1;
BA_ "GenSigSendType" SG_ 2565668611 TPCM_ControlByte_TECU 7;
BA_ "Platform_VMCU1_Sig" SG_ 2565668611 TPCM_ControlByte_TECU 1;
BA_ "GenSigSendType" SG_ 2565668846 TPCM_ControlByte_TACHO 7;
BA_ "Platform_VMCU1_Sig" SG_ 2565668846 TPCM_ControlByte_TACHO 1;
BA_ "GenSigSendType" SG_ 2565668624 TPCM_ControlByte_RECU 7;
BA_ "Platform_VMCU1_Sig" SG_ 2565668624 TPCM_ControlByte_RECU 1;
BA_ "GenSigSendType" SG_ 2565668623 TPCM_ControlByte_EMSRet 7;
BA_ "Platform_VMCU1_Sig" SG_ 2565668623 TPCM_ControlByte_EMSRet 1;
BA_ "GenSigSendType" SG_ 2565668608 TPCM_ControlByte_EMS 7;
BA_ "Platform_VMCU1_Sig" SG_ 2565668608 TPCM_ControlByte_EMS 1;
BA_ "GenSigSendType" SG_ 2565668619 TPCM_ControlByte_EBS 7;
BA_ "GenSigSendType" SG_ 2565668669 TPCM_ControlByte_ACM 7;
BA_ "Platform_VMCU1_Sig" SG_ 2565668669 TPCM_ControlByte_ACM 1;
BA_ "GenSigCycleTime" SG_ 2566882307 TransmissionGCVW_ISig_3 100;
BA_ "GenSigCycleTimeActive" SG_ 2566882307 TransmissionGCVW_ISig_3 100;
BA_ "GenSigStartValue" SG_ 2566882307 TransmissionGCVW_ISig_3 255;
BA_ "Platform_VMCU1_Sig" SG_ 2566882307 TransmissionGCVW_ISig_3 1;
BA_ "GenSigCycleTime" SG_ 2566882307 PermittedHSAPressure 100;
BA_ "GenSigCycleTimeActive" SG_ 2566882307 PermittedHSAPressure 100;
BA_ "GenSigStartValue" SG_ 2566882307 PermittedHSAPressure 255;
BA_ "GenSigMaxLatency" SG_ 2566882307 PermittedHSAPressure 110;
BA_ "Platform_VMCU1_Sig" SG_ 2566882307 PermittedHSAPressure 1;
BA_ "SeToolAncestorID_SIGNAL" SG_ 2566882307 PermittedHSAPressure "x0000001D0410CF7A";
BA_ "SeToolItemID_SIGNAL" SG_ 2566882307 PermittedHSAPressure "x0000001D0435749F";
BA_ "SeToolName_SIGNAL" SG_ 2566882307 PermittedHSAPressure "PermittedHSAPressure";
BA_ "SeToolVersion_SIGNAL" SG_ 2566882307 PermittedHSAPressure "2";
BA_ "GenSigCycleTime" SG_ 2566882307 TransmEngineCrankEnable_ISig_3 100;
BA_ "GenSigCycleTimeActive" SG_ 2566882307 TransmEngineCrankEnable_ISig_3 100;
BA_ "GenSigStartValue" SG_ 2566882307 TransmEngineCrankEnable_ISig_3 3;
BA_ "Platform_VMCU1_Sig" SG_ 2566882307 TransmEngineCrankEnable_ISig_3 1;
BA_ "SeToolAncestorID_SIGNAL" SG_ 2566882307 TransmEngineCrankEnable_ISig_3 "x0000001D041FEE2F";
BA_ "SeToolItemID_SIGNAL" SG_ 2566882307 TransmEngineCrankEnable_ISig_3 "x0000001D041FEE2F";
BA_ "SeToolName_SIGNAL" SG_ 2566882307 TransmEngineCrankEnable_ISig_3 "TransmEngineCrankEnable";
BA_ "SeToolVersion_SIGNAL" SG_ 2566882307 TransmEngineCrankEnable_ISig_3 "1";
BA_ "GenSigCycleTime" SG_ 2566842094 TachographLocalMinuteOffset_ISig 100;
BA_ "GenSigCycleTimeActive" SG_ 2566842094 TachographLocalMinuteOffset_ISig 100;
BA_ "GenSigStartValue" SG_ 2566842094 TachographLocalMinuteOffset_ISig 255;
BA_ "Platform_VMCU1_Sig" SG_ 2566842094 TachographLocalMinuteOffset_ISig 1;
BA_ "SPN" SG_ 2566842094 TachographLocalMinuteOffset_ISig 1601;
BA_ "SystemSignalLongSymbol" SG_ 2566842094 TachographLocalMinuteOffset_ISig "TachographLocalMinuteOffset_ISig_3";
BA_ "GenSigCycleTime" SG_ 2566842094 TachographMinutes 100;
BA_ "GenSigCycleTimeActive" SG_ 2566842094 TachographMinutes 100;
BA_ "GenSigStartValue" SG_ 2566842094 TachographMinutes 255;
BA_ "Platform_VMCU1_Sig" SG_ 2566842094 TachographMinutes 1;
BA_ "SPN" SG_ 2566842094 TachographMinutes 960;
BA_ "GenSigCycleTime" SG_ 2566842094 TachographYears 100;
BA_ "GenSigCycleTimeActive" SG_ 2566842094 TachographYears 100;
BA_ "GenSigStartValue" SG_ 2566842094 TachographYears 255;
BA_ "Platform_VMCU1_Sig" SG_ 2566842094 TachographYears 1;
BA_ "SPN" SG_ 2566842094 TachographYears 964;
BA_ "SeToolAncestorID_SIGNAL" SG_ 2566842094 TachographYears "x0000001D0419B88C";
BA_ "SeToolItemID_SIGNAL" SG_ 2566842094 TachographYears "x0000001D0419B88C";
BA_ "SeToolName_SIGNAL" SG_ 2566842094 TachographYears "TachographYears";
BA_ "SeToolVersion_SIGNAL" SG_ 2566842094 TachographYears "1";
BA_ "GenSigCycleTime" SG_ 2566842094 TachographSeconds 100;
BA_ "GenSigCycleTimeActive" SG_ 2566842094 TachographSeconds 100;
BA_ "GenSigStartValue" SG_ 2566842094 TachographSeconds 255;
BA_ "Platform_VMCU1_Sig" SG_ 2566842094 TachographSeconds 1;
BA_ "SPN" SG_ 2566842094 TachographSeconds 959;
BA_ "GenSigCycleTime" SG_ 2566842094 TachographHours 100;
BA_ "GenSigCycleTimeActive" SG_ 2566842094 TachographHours 100;
BA_ "GenSigStartValue" SG_ 2566842094 TachographHours 255;
BA_ "Platform_VMCU1_Sig" SG_ 2566842094 TachographHours 1;
BA_ "SPN" SG_ 2566842094 TachographHours 961;
BA_ "GenSigCycleTime" SG_ 2566842094 TachographMonths 100;
BA_ "GenSigCycleTimeActive" SG_ 2566842094 TachographMonths 100;
BA_ "GenSigStartValue" SG_ 2566842094 TachographMonths 255;
BA_ "Platform_VMCU1_Sig" SG_ 2566842094 TachographMonths 1;
BA_ "SPN" SG_ 2566842094 TachographMonths 963;
BA_ "SeToolAncestorID_SIGNAL" SG_ 2566842094 TachographMonths "x0000001D0419B85C";
BA_ "SeToolItemID_SIGNAL" SG_ 2566842094 TachographMonths "x0000001D0419B85C";
BA_ "SeToolName_SIGNAL" SG_ 2566842094 TachographMonths "TachographMonths";
BA_ "SeToolVersion_SIGNAL" SG_ 2566842094 TachographMonths "1";
BA_ "GenSigCycleTime" SG_ 2566842094 TachographLocalHourOffset_ISig_3 100;
BA_ "GenSigCycleTimeActive" SG_ 2566842094 TachographLocalHourOffset_ISig_3 100;
BA_ "GenSigStartValue" SG_ 2566842094 TachographLocalHourOffset_ISig_3 255;
BA_ "Platform_VMCU1_Sig" SG_ 2566842094 TachographLocalHourOffset_ISig_3 1;
BA_ "SPN" SG_ 2566842094 TachographLocalHourOffset_ISig_3 1602;
BA_ "GenSigCycleTime" SG_ 2566842094 TachographDays 100;
BA_ "GenSigCycleTimeActive" SG_ 2566842094 TachographDays 100;
BA_ "GenSigStartValue" SG_ 2566842094 TachographDays 255;
BA_ "Platform_VMCU1_Sig" SG_ 2566842094 TachographDays 1;
BA_ "SPN" SG_ 2566842094 TachographDays 962;
BA_ "SeToolAncestorID_SIGNAL" SG_ 2566842094 TachographDays "x0000001D0419B848";
BA_ "SeToolItemID_SIGNAL" SG_ 2566842094 TachographDays "x0000001D0419B848";
BA_ "SeToolName_SIGNAL" SG_ 2566842094 TachographDays "TachographDays";
BA_ "SeToolVersion_SIGNAL" SG_ 2566842094 TachographDays "1";
BA_ "GenSigCycleTime" SG_ 2566841879 MonthUTC_ISig_3 100;
BA_ "GenSigCycleTimeActive" SG_ 2566841879 MonthUTC_ISig_3 100;
BA_ "GenSigStartValue" SG_ 2566841879 MonthUTC_ISig_3 255;
BA_ "Platform_VMCU1_Sig" SG_ 2566841879 MonthUTC_ISig_3 1;
BA_ "SPN" SG_ 2566841879 MonthUTC_ISig_3 963;
BA_ "SeToolAncestorID_SIGNAL" SG_ 2566841879 MonthUTC_ISig_3 "x0000001D0412FAC9";
BA_ "SeToolItemID_SIGNAL" SG_ 2566841879 MonthUTC_ISig_3 "x0000001D041EBD16";
BA_ "SeToolName_SIGNAL" SG_ 2566841879 MonthUTC_ISig_3 "MonthUTC";
BA_ "SeToolVersion_SIGNAL" SG_ 2566841879 MonthUTC_ISig_3 "2";
BA_ "GenSigCycleTime" SG_ 2566841879 SecondsUTC_ISig_3 100;
BA_ "GenSigCycleTimeActive" SG_ 2566841879 SecondsUTC_ISig_3 100;
BA_ "GenSigStartValue" SG_ 2566841879 SecondsUTC_ISig_3 255;
BA_ "Platform_VMCU1_Sig" SG_ 2566841879 SecondsUTC_ISig_3 1;
BA_ "SPN" SG_ 2566841879 SecondsUTC_ISig_3 959;
BA_ "SeToolAncestorID_SIGNAL" SG_ 2566841879 SecondsUTC_ISig_3 "x0000001D0412FABE";
BA_ "SeToolItemID_SIGNAL" SG_ 2566841879 SecondsUTC_ISig_3 "x0000001D041EBD32";
BA_ "SeToolName_SIGNAL" SG_ 2566841879 SecondsUTC_ISig_3 "SecondsUTC";
BA_ "SeToolVersion_SIGNAL" SG_ 2566841879 SecondsUTC_ISig_3 "2";
BA_ "GenSigCycleTime" SG_ 2566841879 HoursUTC_ISig_3 100;
BA_ "GenSigCycleTimeActive" SG_ 2566841879 HoursUTC_ISig_3 100;
BA_ "GenSigStartValue" SG_ 2566841879 HoursUTC_ISig_3 255;
BA_ "Platform_VMCU1_Sig" SG_ 2566841879 HoursUTC_ISig_3 1;
BA_ "SPN" SG_ 2566841879 HoursUTC_ISig_3 961;
BA_ "SeToolAncestorID_SIGNAL" SG_ 2566841879 HoursUTC_ISig_3 "x0000001D0412FAC2";
BA_ "SeToolItemID_SIGNAL" SG_ 2566841879 HoursUTC_ISig_3 "x0000001D041EBD20";
BA_ "SeToolName_SIGNAL" SG_ 2566841879 HoursUTC_ISig_3 "HoursUTC";
BA_ "SeToolVersion_SIGNAL" SG_ 2566841879 HoursUTC_ISig_3 "2";
BA_ "GenSigCycleTime" SG_ 2566841879 YearUTC_ISig_3 100;
BA_ "GenSigCycleTimeActive" SG_ 2566841879 YearUTC_ISig_3 100;
BA_ "GenSigStartValue" SG_ 2566841879 YearUTC_ISig_3 255;
BA_ "Platform_VMCU1_Sig" SG_ 2566841879 YearUTC_ISig_3 1;
BA_ "SPN" SG_ 2566841879 YearUTC_ISig_3 964;
BA_ "SeToolAncestorID_SIGNAL" SG_ 2566841879 YearUTC_ISig_3 "x0000001D0412FACB";
BA_ "SeToolItemID_SIGNAL" SG_ 2566841879 YearUTC_ISig_3 "x0000001D041EBCEF";
BA_ "SeToolName_SIGNAL" SG_ 2566841879 YearUTC_ISig_3 "YearUTC";
BA_ "SeToolVersion_SIGNAL" SG_ 2566841879 YearUTC_ISig_3 "2";
BA_ "GenSigCycleTime" SG_ 2566841879 DayUTC_ISig_3 100;
BA_ "GenSigCycleTimeActive" SG_ 2566841879 DayUTC_ISig_3 100;
BA_ "GenSigStartValue" SG_ 2566841879 DayUTC_ISig_3 255;
BA_ "Platform_VMCU1_Sig" SG_ 2566841879 DayUTC_ISig_3 1;
BA_ "SPN" SG_ 2566841879 DayUTC_ISig_3 962;
BA_ "SeToolAncestorID_SIGNAL" SG_ 2566841879 DayUTC_ISig_3 "x0000001D0412FAC4";
BA_ "SeToolItemID_SIGNAL" SG_ 2566841879 DayUTC_ISig_3 "x0000001D041EBD81";
BA_ "SeToolName_SIGNAL" SG_ 2566841879 DayUTC_ISig_3 "DayUTC";
BA_ "SeToolVersion_SIGNAL" SG_ 2566841879 DayUTC_ISig_3 "2";
BA_ "GenSigCycleTime" SG_ 2566841879 MinutesUTC_ISig_3 100;
BA_ "GenSigCycleTimeActive" SG_ 2566841879 MinutesUTC_ISig_3 100;
BA_ "GenSigStartValue" SG_ 2566841879 MinutesUTC_ISig_3 255;
BA_ "Platform_VMCU1_Sig" SG_ 2566841879 MinutesUTC_ISig_3 1;
BA_ "SPN" SG_ 2566841879 MinutesUTC_ISig_3 960;
BA_ "SeToolAncestorID_SIGNAL" SG_ 2566841879 MinutesUTC_ISig_3 "x0000001D0412FAC0";
BA_ "SeToolItemID_SIGNAL" SG_ 2566841879 MinutesUTC_ISig_3 "x0000001D041EBD29";
BA_ "SeToolName_SIGNAL" SG_ 2566841879 MinutesUTC_ISig_3 "MinutesUTC";
BA_ "SeToolVersion_SIGNAL" SG_ 2566841879 MinutesUTC_ISig_3 "2";
BA_ "GenSigSendType" SG_ 2564156951 AdjustLocalMinuteOffset 1;
BA_ "GenSigStartValue" SG_ 2564156951 AdjustLocalMinuteOffset 255;
BA_ "Platform_VMCU1_Sig" SG_ 2564156951 AdjustLocalMinuteOffset 1;
BA_ "SPN" SG_ 2564156951 AdjustLocalMinuteOffset 1609;
BA_ "GenSigSendType" SG_ 2564156951 AdjustLocalHourOffset 1;
BA_ "GenSigStartValue" SG_ 2564156951 AdjustLocalHourOffset 255;
BA_ "Platform_VMCU1_Sig" SG_ 2564156951 AdjustLocalHourOffset 1;
BA_ "SPN" SG_ 2564156951 AdjustLocalHourOffset 1610;
BA_ "GenSigCycleTime" SG_ 2365484270 Driver2TimeRelatedStates_ISig_3 100;
BA_ "GenSigCycleTimeActive" SG_ 2365484270 Driver2TimeRelatedStates_ISig_3 100;
BA_ "GenSigStartValue" SG_ 2365484270 Driver2TimeRelatedStates_ISig_3 15;
BA_ "Platform_VMCU1_Sig" SG_ 2365484270 Driver2TimeRelatedStates_ISig_3 1;
BA_ "SPN" SG_ 2365484270 Driver2TimeRelatedStates_ISig_3 1618;
BA_ "GenSigCycleTime" SG_ 2365484270 VehicleMotion_ISig_3 100;
BA_ "GenSigCycleTimeActive" SG_ 2365484270 VehicleMotion_ISig_3 100;
BA_ "GenSigStartValue" SG_ 2365484270 VehicleMotion_ISig_3 3;
BA_ "Platform_VMCU1_Sig" SG_ 2365484270 VehicleMotion_ISig_3 1;
BA_ "SPN" SG_ 2365484270 VehicleMotion_ISig_3 1611;
BA_ "GenSigCycleTime" SG_ 2365484270 TachographVehicleSpeed_ISig_3 100;
BA_ "GenSigCycleTimeActive" SG_ 2365484270 TachographVehicleSpeed_ISig_3 100;
BA_ "GenSigStartValue" SG_ 2365484270 TachographVehicleSpeed_ISig_3 65535;
BA_ "Platform_VMCU1_Sig" SG_ 2365484270 TachographVehicleSpeed_ISig_3 1;
BA_ "SPN" SG_ 2365484270 TachographVehicleSpeed_ISig_3 1624;
BA_ "SeToolAncestorID_SIGNAL" SG_ 2365484270 TachographVehicleSpeed_ISig_3 "x0000001D0414CAF5";
BA_ "SeToolItemID_SIGNAL" SG_ 2365484270 TachographVehicleSpeed_ISig_3 "x0000001D0414CAF5";
BA_ "SeToolName_SIGNAL" SG_ 2365484270 TachographVehicleSpeed_ISig_3 "TachographVehicleSpeed";
BA_ "SeToolVersion_SIGNAL" SG_ 2365484270 TachographVehicleSpeed_ISig_3 "1";
BA_ "GenSigCycleTime" SG_ 2365484270 TachographPerformance_ISig_3 100;
BA_ "GenSigCycleTimeActive" SG_ 2365484270 TachographPerformance_ISig_3 100;
BA_ "GenSigStartValue" SG_ 2365484270 TachographPerformance_ISig_3 3;
BA_ "Platform_VMCU1_Sig" SG_ 2365484270 TachographPerformance_ISig_3 1;
BA_ "SPN" SG_ 2365484270 TachographPerformance_ISig_3 1620;
BA_ "GenSigCycleTime" SG_ 2365484270 Driver1WorkingState_ISig_3 100;
BA_ "GenSigCycleTimeActive" SG_ 2365484270 Driver1WorkingState_ISig_3 100;
BA_ "GenSigStartValue" SG_ 2365484270 Driver1WorkingState_ISig_3 7;
BA_ "Platform_VMCU1_Sig" SG_ 2365484270 Driver1WorkingState_ISig_3 1;
BA_ "SPN" SG_ 2365484270 Driver1WorkingState_ISig_3 1612;
BA_ "SeToolAncestorID_SIGNAL" SG_ 2365484270 Driver1WorkingState_ISig_3 "x0000001D0417BE44";
BA_ "SeToolItemID_SIGNAL" SG_ 2365484270 Driver1WorkingState_ISig_3 "x0000001D0417BE44";
BA_ "SeToolName_SIGNAL" SG_ 2365484270 Driver1WorkingState_ISig_3 "Driver1WorkingState";
BA_ "SeToolVersion_SIGNAL" SG_ 2365484270 Driver1WorkingState_ISig_3 "1";
BA_ "GenSigCycleTime" SG_ 2365484270 Driver1TimeRelatedStates_ISig_3 100;
BA_ "GenSigCycleTimeActive" SG_ 2365484270 Driver1TimeRelatedStates_ISig_3 100;
BA_ "GenSigStartValue" SG_ 2365484270 Driver1TimeRelatedStates_ISig_3 15;
BA_ "Platform_VMCU1_Sig" SG_ 2365484270 Driver1TimeRelatedStates_ISig_3 1;
BA_ "SPN" SG_ 2365484270 Driver1TimeRelatedStates_ISig_3 1617;
BA_ "SeToolAncestorID_SIGNAL" SG_ 2365484270 Driver1TimeRelatedStates_ISig_3 "x0000001D0417BECF";
BA_ "SeToolItemID_SIGNAL" SG_ 2365484270 Driver1TimeRelatedStates_ISig_3 "x0000001D0417BECF";
BA_ "SeToolName_SIGNAL" SG_ 2365484270 Driver1TimeRelatedStates_ISig_3 "Driver1TimeRelatedStates";
BA_ "SeToolVersion_SIGNAL" SG_ 2365484270 Driver1TimeRelatedStates_ISig_3 "1";
BA_ "GenSigCycleTime" SG_ 2365484270 DriverCardDriver2_ISig_3 100;
BA_ "GenSigCycleTimeActive" SG_ 2365484270 DriverCardDriver2_ISig_3 100;
BA_ "GenSigStartValue" SG_ 2365484270 DriverCardDriver2_ISig_3 3;
BA_ "Platform_VMCU1_Sig" SG_ 2365484270 DriverCardDriver2_ISig_3 1;
BA_ "SPN" SG_ 2365484270 DriverCardDriver2_ISig_3 1616;
BA_ "GenSigCycleTime" SG_ 2365484270 TachographOutputShaftSpeed_ISig_ 100;
BA_ "GenSigCycleTimeActive" SG_ 2365484270 TachographOutputShaftSpeed_ISig_ 100;
BA_ "GenSigStartValue" SG_ 2365484270 TachographOutputShaftSpeed_ISig_ 65535;
BA_ "Platform_VMCU1_Sig" SG_ 2365484270 TachographOutputShaftSpeed_ISig_ 1;
BA_ "SPN" SG_ 2365484270 TachographOutputShaftSpeed_ISig_ 1623;
BA_ "SeToolAncestorID_SIGNAL" SG_ 2365484270 TachographOutputShaftSpeed_ISig_ "x0000001D041285E8";
BA_ "SeToolItemID_SIGNAL" SG_ 2365484270 TachographOutputShaftSpeed_ISig_ "x0000001D041285E8";
BA_ "SeToolName_SIGNAL" SG_ 2365484270 TachographOutputShaftSpeed_ISig_ "TachographOutputShaftSpeed";
BA_ "SeToolVersion_SIGNAL" SG_ 2365484270 TachographOutputShaftSpeed_ISig_ "1";
BA_ "SystemSignalLongSymbol" SG_ 2365484270 TachographOutputShaftSpeed_ISig_ "TachographOutputShaftSpeed_ISig_3";
BA_ "GenSigCycleTime" SG_ 2365484270 HandlingInformation_ISig_3 100;
BA_ "GenSigCycleTimeActive" SG_ 2365484270 HandlingInformation_ISig_3 100;
BA_ "GenSigStartValue" SG_ 2365484270 HandlingInformation_ISig_3 3;
BA_ "Platform_VMCU1_Sig" SG_ 2365484270 HandlingInformation_ISig_3 1;
BA_ "SPN" SG_ 2365484270 HandlingInformation_ISig_3 1621;
BA_ "GenSigCycleTime" SG_ 2365484270 DriverCardDriver1_ISig_3 100;
BA_ "GenSigCycleTimeActive" SG_ 2365484270 DriverCardDriver1_ISig_3 100;
BA_ "GenSigStartValue" SG_ 2365484270 DriverCardDriver1_ISig_3 3;
BA_ "Platform_VMCU1_Sig" SG_ 2365484270 DriverCardDriver1_ISig_3 1;
BA_ "SPN" SG_ 2365484270 DriverCardDriver1_ISig_3 1615;
BA_ "GenSigCycleTime" SG_ 2365484270 SystemEvent_ISig_3 100;
BA_ "GenSigCycleTimeActive" SG_ 2365484270 SystemEvent_ISig_3 100;
BA_ "GenSigStartValue" SG_ 2365484270 SystemEvent_ISig_3 3;
BA_ "Platform_VMCU1_Sig" SG_ 2365484270 SystemEvent_ISig_3 1;
BA_ "SPN" SG_ 2365484270 SystemEvent_ISig_3 1622;
BA_ "GenSigCycleTime" SG_ 2365484270 VehicleOverspeed_ISig_3 100;
BA_ "GenSigCycleTimeActive" SG_ 2365484270 VehicleOverspeed_ISig_3 100;
BA_ "GenSigStartValue" SG_ 2365484270 VehicleOverspeed_ISig_3 3;
BA_ "Platform_VMCU1_Sig" SG_ 2365484270 VehicleOverspeed_ISig_3 1;
BA_ "SPN" SG_ 2365484270 VehicleOverspeed_ISig_3 1614;
BA_ "SeToolAncestorID_SIGNAL" SG_ 2365484270 VehicleOverspeed_ISig_3 "x0000001D0417BEBB";
BA_ "SeToolItemID_SIGNAL" SG_ 2365484270 VehicleOverspeed_ISig_3 "x0000001D0417BEBB";
BA_ "SeToolName_SIGNAL" SG_ 2365484270 VehicleOverspeed_ISig_3 "VehicleOverspeed";
BA_ "SeToolVersion_SIGNAL" SG_ 2365484270 VehicleOverspeed_ISig_3 "1";
BA_ "GenSigCycleTime" SG_ 2365484270 Driver2WorkingState_ISig_3 100;
BA_ "GenSigCycleTimeActive" SG_ 2365484270 Driver2WorkingState_ISig_3 100;
BA_ "GenSigStartValue" SG_ 2365484270 Driver2WorkingState_ISig_3 7;
BA_ "Platform_VMCU1_Sig" SG_ 2365484270 Driver2WorkingState_ISig_3 1;
BA_ "SPN" SG_ 2365484270 Driver2WorkingState_ISig_3 1613;
BA_ "SeToolAncestorID_SIGNAL" SG_ 2365484270 Driver2WorkingState_ISig_3 "x0000001D0417BEAC";
BA_ "SeToolItemID_SIGNAL" SG_ 2365484270 Driver2WorkingState_ISig_3 "x0000001D0417BEAC";
BA_ "SeToolName_SIGNAL" SG_ 2365484270 Driver2WorkingState_ISig_3 "Driver2WorkingState";
BA_ "SeToolVersion_SIGNAL" SG_ 2365484270 Driver2WorkingState_ISig_3 "1";
BA_ "GenSigCycleTime" SG_ 2348876549 TransmissionMode4 100;
BA_ "GenSigCycleTimeActive" SG_ 2348876549 TransmissionMode4 100;
BA_ "GenSigStartValue" SG_ 2348876549 TransmissionMode4 3;
BA_ "SPN" SG_ 2348876549 TransmissionMode4 1855;
BA_ "GenSigCycleTime" SG_ 2348876549 TransmissionRequestedGear 100;
BA_ "GenSigCycleTimeActive" SG_ 2348876549 TransmissionRequestedGear 100;
BA_ "GenSigStartValue" SG_ 2348876549 TransmissionRequestedGear 255;
BA_ "SPN" SG_ 2348876549 TransmissionRequestedGear 525;
BA_ "GenSigCycleTime" SG_ 2348876549 TransmShiftSelectorDisplayMode 100;
BA_ "GenSigCycleTimeActive" SG_ 2348876549 TransmShiftSelectorDisplayMode 100;
BA_ "GenSigStartValue" SG_ 2348876549 TransmShiftSelectorDisplayMode 3;
BA_ "SPN" SG_ 2348876549 TransmShiftSelectorDisplayMode 2985;
BA_ "GenSigCycleTime" SG_ 2348876549 TransmissionMode3 100;
BA_ "GenSigCycleTimeActive" SG_ 2348876549 TransmissionMode3 100;
BA_ "GenSigStartValue" SG_ 2348876549 TransmissionMode3 3;
BA_ "SPN" SG_ 2348876549 TransmissionMode3 1854;
BA_ "GenSigCycleTime" SG_ 2565533233 PGNReq_Tacho_CIOM 100;
BA_ "GenSigCycleTimeActive" SG_ 2565533233 PGNReq_Tacho_CIOM 100;
BA_ "GenSigStartValue" SG_ 2565533233 PGNReq_Tacho_CIOM 65131;
BA_ "Platform_VMCU1_Sig" SG_ 2565533233 PGNReq_Tacho_CIOM 1;
BA_ "GenSigSendType" SG_ 2631855639 CounterReset_GUIEventCmd 1;
BA_ "GenSigStartValue" SG_ 2631855639 CounterReset_GUIEventCmd 3;
BA_ "Platform_VMCU1_Sig" SG_ 2631855639 CounterReset_GUIEventCmd 1;
BA_ "SPN" SG_ 2631855639 CounterReset_GUIEventCmd 989;
BA_ "GenSigCycleTime" SG_ 2499792656 DrivelineRetarderStat_ISig_3 100;
BA_ "GenSigCycleTimeActive" SG_ 2499792656 DrivelineRetarderStat_ISig_3 100;
BA_ "GenSigStartValue" SG_ 2499792656 DrivelineRetarderStat_ISig_3 3;
BA_ "GenSigMaxLatency" SG_ 2499792656 DrivelineRetarderStat_ISig_3 100;
BA_ "Platform_VMCU1_Sig" SG_ 2499792656 DrivelineRetarderStat_ISig_3 1;
BA_ "GenSigCycleTime" SG_ 2566840592 DrivelineRetarderRefTorque 100;
BA_ "GenSigCycleTimeActive" SG_ 2566840592 DrivelineRetarderRefTorque 100;
BA_ "GenSigStartValue" SG_ 2566840592 DrivelineRetarderRefTorque 65535;
BA_ "Platform_VMCU1_Sig" SG_ 2566840592 DrivelineRetarderRefTorque 1;
BA_ "SPN" SG_ 2566840592 DrivelineRetarderRefTorque 556;
BA_ "SeToolAncestorID_SIGNAL" SG_ 2566840592 DrivelineRetarderRefTorque "x0000001D041286D2";
BA_ "SeToolItemID_SIGNAL" SG_ 2566840592 DrivelineRetarderRefTorque "x0000001D041286D2";
BA_ "SeToolName_SIGNAL" SG_ 2566840592 DrivelineRetarderRefTorque "ReferenceDrivelineRetarderTorque";
BA_ "SeToolVersion_SIGNAL" SG_ 2566840592 DrivelineRetarderRefTorque "1";
BA_ "GenSigCycleTime" SG_ 2566840592 DrivelineRetarderLocation 100;
BA_ "GenSigCycleTimeActive" SG_ 2566840592 DrivelineRetarderLocation 100;
BA_ "GenSigStartValue" SG_ 2566840592 DrivelineRetarderLocation 15;
BA_ "Platform_VMCU1_Sig" SG_ 2566840592 DrivelineRetarderLocation 1;
BA_ "SPN" SG_ 2566840592 DrivelineRetarderLocation 902;
BA_ "GenSigCycleTime" SG_ 2566840592 DrivelineRetarderType 100;
BA_ "GenSigCycleTimeActive" SG_ 2566840592 DrivelineRetarderType 100;
BA_ "GenSigStartValue" SG_ 2566840592 DrivelineRetarderType 15;
BA_ "Platform_VMCU1_Sig" SG_ 2566840592 DrivelineRetarderType 1;
BA_ "SPN" SG_ 2566840592 DrivelineRetarderType 901;
BA_ "GenSigCycleTime" SG_ 2566840591 EngRetConf_RetCtrlMethod 100;
BA_ "GenSigCycleTimeActive" SG_ 2566840591 EngRetConf_RetCtrlMethod 100;
BA_ "GenSigStartValue" SG_ 2566840591 EngRetConf_RetCtrlMethod 255;
BA_ "Platform_VMCU1_Sig" SG_ 2566840591 EngRetConf_RetCtrlMethod 1;
BA_ "SPN" SG_ 2566840591 EngRetConf_RetCtrlMethod 557;
BA_ "SeToolAncestorID_SIGNAL" SG_ 2566840591 EngRetConf_RetCtrlMethod "x0000001D0431F119";
BA_ "SeToolItemID_SIGNAL" SG_ 2566840591 EngRetConf_RetCtrlMethod "x0000001D0431F119";
BA_ "SeToolName_SIGNAL" SG_ 2566840591 EngRetConf_RetCtrlMethod "EngRetConf_RetCtrlMethod";
BA_ "SeToolVersion_SIGNAL" SG_ 2566840591 EngRetConf_RetCtrlMethod "1";
BA_ "GenSigCycleTime" SG_ 2566840591 EngRetConf_RetSpeedAtP4 100;
BA_ "GenSigCycleTimeActive" SG_ 2566840591 EngRetConf_RetSpeedAtP4 100;
BA_ "GenSigStartValue" SG_ 2566840591 EngRetConf_RetSpeedAtP4 65535;
BA_ "Platform_VMCU1_Sig" SG_ 2566840591 EngRetConf_RetSpeedAtP4 1;
BA_ "SPN" SG_ 2566840591 EngRetConf_RetSpeedAtP4 550;
BA_ "SeToolAncestorID_SIGNAL" SG_ 2566840591 EngRetConf_RetSpeedAtP4 "x0000001D0431F0E0";
BA_ "SeToolItemID_SIGNAL" SG_ 2566840591 EngRetConf_RetSpeedAtP4 "x0000001D0431F0E0";
BA_ "SeToolName_SIGNAL" SG_ 2566840591 EngRetConf_RetSpeedAtP4 "EngRetConf_RetSpeedAtP4";
BA_ "SeToolVersion_SIGNAL" SG_ 2566840591 EngRetConf_RetSpeedAtP4 "1";
BA_ "GenSigCycleTime" SG_ 2566840591 EngRetConf_MaxRetSpeedP2 100;
BA_ "GenSigCycleTimeActive" SG_ 2566840591 EngRetConf_MaxRetSpeedP2 100;
BA_ "GenSigStartValue" SG_ 2566840591 EngRetConf_MaxRetSpeedP2 65535;
BA_ "Platform_VMCU1_Sig" SG_ 2566840591 EngRetConf_MaxRetSpeedP2 1;
BA_ "SPN" SG_ 2566840591 EngRetConf_MaxRetSpeedP2 548;
BA_ "SeToolAncestorID_SIGNAL" SG_ 2566840591 EngRetConf_MaxRetSpeedP2 "x0000001D0431F0DC";
BA_ "SeToolItemID_SIGNAL" SG_ 2566840591 EngRetConf_MaxRetSpeedP2 "x0000001D0431F0DC";
BA_ "SeToolName_SIGNAL" SG_ 2566840591 EngRetConf_MaxRetSpeedP2 "EngRetConf_MaxRetSpeedP2";
BA_ "SeToolVersion_SIGNAL" SG_ 2566840591 EngRetConf_MaxRetSpeedP2 "1";
BA_ "GenSigCycleTime" SG_ 2566840591 EngRetConf_PerTrqAtP3 100;
BA_ "GenSigCycleTimeActive" SG_ 2566840591 EngRetConf_PerTrqAtP3 100;
BA_ "GenSigStartValue" SG_ 2566840591 EngRetConf_PerTrqAtP3 255;
BA_ "Platform_VMCU1_Sig" SG_ 2566840591 EngRetConf_PerTrqAtP3 1;
BA_ "SPN" SG_ 2566840591 EngRetConf_PerTrqAtP3 553;
BA_ "SeToolAncestorID_SIGNAL" SG_ 2566840591 EngRetConf_PerTrqAtP3 "x0000001D0431F0E4";
BA_ "SeToolItemID_SIGNAL" SG_ 2566840591 EngRetConf_PerTrqAtP3 "x0000001D0431F0E4";
BA_ "SeToolName_SIGNAL" SG_ 2566840591 EngRetConf_PerTrqAtP3 "EngRetConf_PerTrqAtP3";
BA_ "SeToolVersion_SIGNAL" SG_ 2566840591 EngRetConf_PerTrqAtP3 "1";
BA_ "GenSigCycleTime" SG_ 2566840591 EngRetConf_RetSpeedAtP5 100;
BA_ "GenSigCycleTimeActive" SG_ 2566840591 EngRetConf_RetSpeedAtP5 100;
BA_ "GenSigStartValue" SG_ 2566840591 EngRetConf_RetSpeedAtP5 65535;
BA_ "Platform_VMCU1_Sig" SG_ 2566840591 EngRetConf_RetSpeedAtP5 1;
BA_ "SPN" SG_ 2566840591 EngRetConf_RetSpeedAtP5 547;
BA_ "SeToolAncestorID_SIGNAL" SG_ 2566840591 EngRetConf_RetSpeedAtP5 "x0000001D0431F107";
BA_ "SeToolItemID_SIGNAL" SG_ 2566840591 EngRetConf_RetSpeedAtP5 "x0000001D0431F107";
BA_ "SeToolName_SIGNAL" SG_ 2566840591 EngRetConf_RetSpeedAtP5 "EngRetConf_RetSpeedAtP5";
BA_ "SeToolVersion_SIGNAL" SG_ 2566840591 EngRetConf_RetSpeedAtP5 "1";
BA_ "GenSigCycleTime" SG_ 2566840591 EngRetConf_speedAtIdleP1 100;
BA_ "GenSigCycleTimeActive" SG_ 2566840591 EngRetConf_speedAtIdleP1 100;
BA_ "GenSigStartValue" SG_ 2566840591 EngRetConf_speedAtIdleP1 65535;
BA_ "Platform_VMCU1_Sig" SG_ 2566840591 EngRetConf_speedAtIdleP1 1;
BA_ "SPN" SG_ 2566840591 EngRetConf_speedAtIdleP1 546;
BA_ "SeToolAncestorID_SIGNAL" SG_ 2566840591 EngRetConf_speedAtIdleP1 "x0000001D0431F0CB";
BA_ "SeToolItemID_SIGNAL" SG_ 2566840591 EngRetConf_speedAtIdleP1 "x0000001D0431F0CB";
BA_ "SeToolName_SIGNAL" SG_ 2566840591 EngRetConf_speedAtIdleP1 "EngRetConf_speedAtIdleP1";
BA_ "SeToolVersion_SIGNAL" SG_ 2566840591 EngRetConf_speedAtIdleP1 "1";
BA_ "GenSigCycleTime" SG_ 2566840591 EngRetConf_PerTrqAtP4 100;
BA_ "GenSigCycleTimeActive" SG_ 2566840591 EngRetConf_PerTrqAtP4 100;
BA_ "GenSigStartValue" SG_ 2566840591 EngRetConf_PerTrqAtP4 255;
BA_ "Platform_VMCU1_Sig" SG_ 2566840591 EngRetConf_PerTrqAtP4 1;
BA_ "SPN" SG_ 2566840591 EngRetConf_PerTrqAtP4 554;
BA_ "SeToolAncestorID_SIGNAL" SG_ 2566840591 EngRetConf_PerTrqAtP4 "x0000001D0431F101";
BA_ "SeToolItemID_SIGNAL" SG_ 2566840591 EngRetConf_PerTrqAtP4 "x0000001D0431F101";
BA_ "SeToolName_SIGNAL" SG_ 2566840591 EngRetConf_PerTrqAtP4 "EngRetConf_PerTrqAtP4";
BA_ "SeToolVersion_SIGNAL" SG_ 2566840591 EngRetConf_PerTrqAtP4 "1";
BA_ "GenSigCycleTime" SG_ 2566840591 ReferenceEngineRetarderTorque 100;
BA_ "GenSigCycleTimeActive" SG_ 2566840591 ReferenceEngineRetarderTorque 100;
BA_ "GenSigStartValue" SG_ 2566840591 ReferenceEngineRetarderTorque 65535;
BA_ "Platform_VMCU1_Sig" SG_ 2566840591 ReferenceEngineRetarderTorque 1;
BA_ "SPN" SG_ 2566840591 ReferenceEngineRetarderTorque 556;
BA_ "SeToolAncestorID_SIGNAL" SG_ 2566840591 ReferenceEngineRetarderTorque "x0000001D041286C7";
BA_ "SeToolItemID_SIGNAL" SG_ 2566840591 ReferenceEngineRetarderTorque "x0000001D041286C7";
BA_ "SeToolName_SIGNAL" SG_ 2566840591 ReferenceEngineRetarderTorque "ReferenceEngineRetarderTorque";
BA_ "SeToolVersion_SIGNAL" SG_ 2566840591 ReferenceEngineRetarderTorque "1";
BA_ "GenSigCycleTime" SG_ 2566840591 EngRetConf_PerTrqAtIdleP1 100;
BA_ "GenSigCycleTimeActive" SG_ 2566840591 EngRetConf_PerTrqAtIdleP1 100;
BA_ "GenSigStartValue" SG_ 2566840591 EngRetConf_PerTrqAtIdleP1 255;
BA_ "Platform_VMCU1_Sig" SG_ 2566840591 EngRetConf_PerTrqAtIdleP1 1;
BA_ "SPN" SG_ 2566840591 EngRetConf_PerTrqAtIdleP1 551;
BA_ "SeToolAncestorID_SIGNAL" SG_ 2566840591 EngRetConf_PerTrqAtIdleP1 "x0000001D0431F0CE";
BA_ "SeToolItemID_SIGNAL" SG_ 2566840591 EngRetConf_PerTrqAtIdleP1 "x0000001D0431F0CE";
BA_ "SeToolName_SIGNAL" SG_ 2566840591 EngRetConf_PerTrqAtIdleP1 "EngRetConf_PerTrqAtIdleP1";
BA_ "SeToolVersion_SIGNAL" SG_ 2566840591 EngRetConf_PerTrqAtIdleP1 "1";
BA_ "GenSigCycleTime" SG_ 2566840591 EngRetConf_RetSpeedAtP3 100;
BA_ "GenSigCycleTimeActive" SG_ 2566840591 EngRetConf_RetSpeedAtP3 100;
BA_ "GenSigStartValue" SG_ 2566840591 EngRetConf_RetSpeedAtP3 65535;
BA_ "Platform_VMCU1_Sig" SG_ 2566840591 EngRetConf_RetSpeedAtP3 1;
BA_ "SPN" SG_ 2566840591 EngRetConf_RetSpeedAtP3 549;
BA_ "SeToolAncestorID_SIGNAL" SG_ 2566840591 EngRetConf_RetSpeedAtP3 "x0000001D0431F0DE";
BA_ "SeToolItemID_SIGNAL" SG_ 2566840591 EngRetConf_RetSpeedAtP3 "x0000001D0431F0DE";
BA_ "SeToolName_SIGNAL" SG_ 2566840591 EngRetConf_RetSpeedAtP3 "EngRetConf_RetSpeedAtP3";
BA_ "SeToolVersion_SIGNAL" SG_ 2566840591 EngRetConf_RetSpeedAtP3 "1";
BA_ "GenSigCycleTime" SG_ 2566840591 EngRetConf_PerTrqAtMaxSpeedP2 100;
BA_ "GenSigCycleTimeActive" SG_ 2566840591 EngRetConf_PerTrqAtMaxSpeedP2 100;
BA_ "GenSigStartValue" SG_ 2566840591 EngRetConf_PerTrqAtMaxSpeedP2 255;
BA_ "Platform_VMCU1_Sig" SG_ 2566840591 EngRetConf_PerTrqAtMaxSpeedP2 1;
BA_ "SPN" SG_ 2566840591 EngRetConf_PerTrqAtMaxSpeedP2 552;
BA_ "SeToolAncestorID_SIGNAL" SG_ 2566840591 EngRetConf_PerTrqAtMaxSpeedP2 "x0000001D0431F0E2";
BA_ "SeToolItemID_SIGNAL" SG_ 2566840591 EngRetConf_PerTrqAtMaxSpeedP2 "x0000001D0431F0E2";
BA_ "SeToolName_SIGNAL" SG_ 2566840591 EngRetConf_PerTrqAtMaxSpeedP2 "EngRetConf_PerTrqAtMaxSpeedP2";
BA_ "SeToolVersion_SIGNAL" SG_ 2566840591 EngRetConf_PerTrqAtMaxSpeedP2 "1";
BA_ "GenSigCycleTime" SG_ 2566840591 EngRetConf_PerTrqAtP5 100;
BA_ "GenSigCycleTimeActive" SG_ 2566840591 EngRetConf_PerTrqAtP5 100;
BA_ "GenSigStartValue" SG_ 2566840591 EngRetConf_PerTrqAtP5 255;
BA_ "Platform_VMCU1_Sig" SG_ 2566840591 EngRetConf_PerTrqAtP5 1;
BA_ "SPN" SG_ 2566840591 EngRetConf_PerTrqAtP5 555;
BA_ "SeToolAncestorID_SIGNAL" SG_ 2566840591 EngRetConf_PerTrqAtP5 "x0000001D0431F103";
BA_ "SeToolItemID_SIGNAL" SG_ 2566840591 EngRetConf_PerTrqAtP5 "x0000001D0431F103";
BA_ "SeToolName_SIGNAL" SG_ 2566840591 EngRetConf_PerTrqAtP5 "EngRetConf_PerTrqAtP5";
BA_ "SeToolVersion_SIGNAL" SG_ 2566840591 EngRetConf_PerTrqAtP5 "1";
BA_ "GenSigSendType" SG_ 2566899694 TwoWeeksTotalOdometer 1;
BA_ "GenSigStartValue" SG_ 2566899694 TwoWeeksTotalOdometer 65535;
BA_ "Platform_VMCU1_Sig" SG_ 2566899694 TwoWeeksTotalOdometer 1;
BA_ "GenSigSendType" SG_ 2566899694 WeeklyTotalOdometer 1;
BA_ "GenSigStartValue" SG_ 2566899694 WeeklyTotalOdometer 65535;
BA_ "Platform_VMCU1_Sig" SG_ 2566899694 WeeklyTotalOdometer 1;
BA_ "GenSigSendType" SG_ 2566899694 DailyRestingTimeShift1_ISig_3 1;
BA_ "GenSigStartValue" SG_ 2566899694 DailyRestingTimeShift1_ISig_3 32767;
BA_ "Platform_VMCU1_Sig" SG_ 2566899694 DailyRestingTimeShift1_ISig_3 1;
BA_ "GenSigSendType" SG_ 2566899694 RestingPeriodFlagShift2_ISig_3 1;
BA_ "Platform_VMCU1_Sig" SG_ 2566899694 RestingPeriodFlagShift2_ISig_3 1;
BA_ "GenSigSendType" SG_ 2566899694 AvailableCounter 1;
BA_ "GenSigStartValue" SG_ 2566899694 AvailableCounter 65535;
BA_ "Platform_VMCU1_Sig" SG_ 2566899694 AvailableCounter 1;
BA_ "GenSigSendType" SG_ 2566899694 DailyDrivingTimeShift4_ISig_3 1;
BA_ "GenSigStartValue" SG_ 2566899694 DailyDrivingTimeShift4_ISig_3 32767;
BA_ "Platform_VMCU1_Sig" SG_ 2566899694 DailyDrivingTimeShift4_ISig_3 1;
BA_ "GenSigSendType" SG_ 2566899694 DailyDrivingPeriod_ISig_3 1;
BA_ "GenSigStartValue" SG_ 2566899694 DailyDrivingPeriod_ISig_3 32767;
BA_ "Platform_VMCU1_Sig" SG_ 2566899694 DailyDrivingPeriod_ISig_3 1;
BA_ "GenSigSendType" SG_ 2566899694 DailyRestingTimeShift7_ISig_3 1;
BA_ "GenSigStartValue" SG_ 2566899694 DailyRestingTimeShift7_ISig_3 32767;
BA_ "Platform_VMCU1_Sig" SG_ 2566899694 DailyRestingTimeShift7_ISig_3 1;
BA_ "GenSigSendType" SG_ 2566899694 UnknownPeriodShift1_ISig_3 1;
BA_ "Platform_VMCU1_Sig" SG_ 2566899694 UnknownPeriodShift1_ISig_3 1;
BA_ "GenSigSendType" SG_ 2566899694 RestingPeriodFlagShift1_ISig_3 1;
BA_ "Platform_VMCU1_Sig" SG_ 2566899694 RestingPeriodFlagShift1_ISig_3 1;
BA_ "GenSigSendType" SG_ 2566899694 DrivingCounter 1;
BA_ "GenSigStartValue" SG_ 2566899694 DrivingCounter 65535;
BA_ "Platform_VMCU1_Sig" SG_ 2566899694 DrivingCounter 1;
BA_ "GenSigSendType" SG_ 2566899694 DailyDrivingTimeShift3_ISig_3 1;
BA_ "GenSigStartValue" SG_ 2566899694 DailyDrivingTimeShift3_ISig_3 32767;
BA_ "Platform_VMCU1_Sig" SG_ 2566899694 DailyDrivingTimeShift3_ISig_3 1;
BA_ "GenSigSendType" SG_ 2566899694 DailyRestingTimeShift2_ISig_3 1;
BA_ "GenSigStartValue" SG_ 2566899694 DailyRestingTimeShift2_ISig_3 32767;
BA_ "Platform_VMCU1_Sig" SG_ 2566899694 DailyRestingTimeShift2_ISig_3 1;
BA_ "GenSigSendType" SG_ 2566899694 DailyRestingTimeShift3_ISig_3 1;
BA_ "GenSigStartValue" SG_ 2566899694 DailyRestingTimeShift3_ISig_3 32767;
BA_ "Platform_VMCU1_Sig" SG_ 2566899694 DailyRestingTimeShift3_ISig_3 1;
BA_ "GenSigSendType" SG_ 2566899694 UnknownPeriodShift2_ISig_3 1;
BA_ "Platform_VMCU1_Sig" SG_ 2566899694 UnknownPeriodShift2_ISig_3 1;
BA_ "GenSigSendType" SG_ 2566899694 RestingPeriodFlag_ISig_3 1;
BA_ "Platform_VMCU1_Sig" SG_ 2566899694 RestingPeriodFlag_ISig_3 1;
BA_ "GenSigSendType" SG_ 2566899694 TwoWeekTotalDrvingTime_ISig_3 1;
BA_ "GenSigStartValue" SG_ 2566899694 TwoWeekTotalDrvingTime_ISig_3 65535;
BA_ "Platform_VMCU1_Sig" SG_ 2566899694 TwoWeekTotalDrvingTime_ISig_3 1;
BA_ "GenSigSendType" SG_ 2566899694 UnknownPeriodShift4_ISig_3 1;
BA_ "Platform_VMCU1_Sig" SG_ 2566899694 UnknownPeriodShift4_ISig_3 1;
BA_ "GenSigSendType" SG_ 2566899694 DailyDrivingTimeShift2_ISig_3 1;
BA_ "GenSigStartValue" SG_ 2566899694 DailyDrivingTimeShift2_ISig_3 32767;
BA_ "Platform_VMCU1_Sig" SG_ 2566899694 DailyDrivingTimeShift2_ISig_3 1;
BA_ "GenSigSendType" SG_ 2566899694 RestingPeriodFlagShift6_ISig_3 1;
BA_ "Platform_VMCU1_Sig" SG_ 2566899694 RestingPeriodFlagShift6_ISig_3 1;
BA_ "GenSigSendType" SG_ 2566899694 DailyRestingTimeShift4_ISig_3 1;
BA_ "GenSigStartValue" SG_ 2566899694 DailyRestingTimeShift4_ISig_3 32767;
BA_ "Platform_VMCU1_Sig" SG_ 2566899694 DailyRestingTimeShift4_ISig_3 1;
BA_ "GenSigSendType" SG_ 2566899694 RestingPeriodFlagShift5_ISig_3 1;
BA_ "Platform_VMCU1_Sig" SG_ 2566899694 RestingPeriodFlagShift5_ISig_3 1;
BA_ "GenSigSendType" SG_ 2566899694 RestingPeriodFlagShift3_ISig_3 1;
BA_ "Platform_VMCU1_Sig" SG_ 2566899694 RestingPeriodFlagShift3_ISig_3 1;
BA_ "GenSigSendType" SG_ 2566899694 DailyDrivingTimeShift5_ISig_3 1;
BA_ "GenSigStartValue" SG_ 2566899694 DailyDrivingTimeShift5_ISig_3 32767;
BA_ "Platform_VMCU1_Sig" SG_ 2566899694 DailyDrivingTimeShift5_ISig_3 1;
BA_ "GenSigSendType" SG_ 2566899694 DailyRestingTimeShift6_ISig_3 1;
BA_ "GenSigStartValue" SG_ 2566899694 DailyRestingTimeShift6_ISig_3 32767;
BA_ "Platform_VMCU1_Sig" SG_ 2566899694 DailyRestingTimeShift6_ISig_3 1;
BA_ "GenSigSendType" SG_ 2566899694 WeeklyTotalDrivingTime_ISig_3 1;
BA_ "GenSigStartValue" SG_ 2566899694 WeeklyTotalDrivingTime_ISig_3 65535;
BA_ "Platform_VMCU1_Sig" SG_ 2566899694 WeeklyTotalDrivingTime_ISig_3 1;
BA_ "GenSigSendType" SG_ 2566899694 UnknownPeriodShift7_ISig_3 1;
BA_ "Platform_VMCU1_Sig" SG_ 2566899694 UnknownPeriodShift7_ISig_3 1;
BA_ "GenSigSendType" SG_ 2566899694 DailyOdometer 1;
BA_ "GenSigStartValue" SG_ 2566899694 DailyOdometer 65535;
BA_ "Platform_VMCU1_Sig" SG_ 2566899694 DailyOdometer 1;
BA_ "GenSigSendType" SG_ 2566899694 UnknownPeriodShift6_ISig_3 1;
BA_ "Platform_VMCU1_Sig" SG_ 2566899694 UnknownPeriodShift6_ISig_3 1;
BA_ "GenSigSendType" SG_ 2566899694 DailyRestingTimeShift5_ISig_3 1;
BA_ "GenSigStartValue" SG_ 2566899694 DailyRestingTimeShift5_ISig_3 32767;
BA_ "Platform_VMCU1_Sig" SG_ 2566899694 DailyRestingTimeShift5_ISig_3 1;
BA_ "GenSigSendType" SG_ 2566899694 DailyDrivingTimeShift1_ISig_3 1;
BA_ "GenSigStartValue" SG_ 2566899694 DailyDrivingTimeShift1_ISig_3 32767;
BA_ "Platform_VMCU1_Sig" SG_ 2566899694 DailyDrivingTimeShift1_ISig_3 1;
BA_ "GenSigSendType" SG_ 2566899694 UnknownPeriodShift3_ISig_3 1;
BA_ "Platform_VMCU1_Sig" SG_ 2566899694 UnknownPeriodShift3_ISig_3 1;
BA_ "GenSigSendType" SG_ 2566899694 RestingPeriodFlagShift4_ISig_3 1;
BA_ "Platform_VMCU1_Sig" SG_ 2566899694 RestingPeriodFlagShift4_ISig_3 1;
BA_ "GenSigSendType" SG_ 2566899694 DailyDrivingTimeShift6_ISig_3 1;
BA_ "GenSigStartValue" SG_ 2566899694 DailyDrivingTimeShift6_ISig_3 32767;
BA_ "Platform_VMCU1_Sig" SG_ 2566899694 DailyDrivingTimeShift6_ISig_3 1;
BA_ "GenSigSendType" SG_ 2566899694 UnknownPeriodShift5_ISig_3 1;
BA_ "Platform_VMCU1_Sig" SG_ 2566899694 UnknownPeriodShift5_ISig_3 1;
BA_ "GenSigSendType" SG_ 2566899694 WorkCounter 1;
BA_ "GenSigStartValue" SG_ 2566899694 WorkCounter 65535;
BA_ "Platform_VMCU1_Sig" SG_ 2566899694 WorkCounter 1;
BA_ "GenSigSendType" SG_ 2566898926 Drvr1CumuBreakTime_Tacho 1;
BA_ "GenSigStartValue" SG_ 2566898926 Drvr1CumuBreakTime_Tacho 65535;
BA_ "Platform_VMCU1_Sig" SG_ 2566898926 Drvr1CumuBreakTime_Tacho 1;
BA_ "GenSigSendType" SG_ 2566898926 Drvr1CurDurSelectActy_Tacho 1;
BA_ "GenSigStartValue" SG_ 2566898926 Drvr1CurDurSelectActy_Tacho 65535;
BA_ "Platform_VMCU1_Sig" SG_ 2566898926 Drvr1CurDurSelectActy_Tacho 1;
BA_ "GenSigSendType" SG_ 2566898926 Driver1CardUnload_Tacho 1;
BA_ "GenSigStartValue" SG_ 2566898926 Driver1CardUnload_Tacho 3;
BA_ "Platform_VMCU1_Sig" SG_ 2566898926 Driver1CardUnload_Tacho 1;
BA_ "GenSigSendType" SG_ 2566898926 EndofLifeDriver1Card_Tacho 1;
BA_ "GenSigStartValue" SG_ 2566898926 EndofLifeDriver1Card_Tacho 3;
BA_ "Platform_VMCU1_Sig" SG_ 2566898926 EndofLifeDriver1Card_Tacho 1;
BA_ "GenSigSendType" SG_ 2566898926 DrawerState_Tacho 1;
BA_ "GenSigStartValue" SG_ 2566898926 DrawerState_Tacho 3;
BA_ "Platform_VMCU1_Sig" SG_ 2566898926 DrawerState_Tacho 1;
BA_ "GenSigSendType" SG_ 2566898926 Drvr1ContinDrivingTime_Tacho 1;
BA_ "GenSigStartValue" SG_ 2566898926 Drvr1ContinDrivingTime_Tacho 65535;
BA_ "Platform_VMCU1_Sig" SG_ 2566898926 Drvr1ContinDrivingTime_Tacho 1;
BA_ "GenSigSendType" SG_ 2566898670 NextCalibrationDateDay 1;
BA_ "GenSigStartValue" SG_ 2566898670 NextCalibrationDateDay 255;
BA_ "Platform_VMCU1_Sig" SG_ 2566898670 NextCalibrationDateDay 1;
BA_ "GenSigSendType" SG_ 2566898670 WVehicleCharacteristicFactor 1;
BA_ "GenSigStartValue" SG_ 2566898670 WVehicleCharacteristicFactor 65535;
BA_ "Platform_VMCU1_Sig" SG_ 2566898670 WVehicleCharacteristicFactor 1;
BA_ "GenSigSendType" SG_ 2566898670 NextCalibrationDateMonth 1;
BA_ "GenSigStartValue" SG_ 2566898670 NextCalibrationDateMonth 255;
BA_ "Platform_VMCU1_Sig" SG_ 2566898670 NextCalibrationDateMonth 1;
BA_ "GenSigSendType" SG_ 2566898670 Driver1Identification_ISig_3 1;
BA_ "Platform_VMCU1_Sig" SG_ 2566898670 Driver1Identification_ISig_3 1;
BA_ "GenSigSendType" SG_ 2566898670 NextCalibrationDateYear 1;
BA_ "GenSigStartValue" SG_ 2566898670 NextCalibrationDateYear 255;
BA_ "Platform_VMCU1_Sig" SG_ 2566898670 NextCalibrationDateYear 1;
BA_ "GenSigSendType" SG_ 2671833838 PhysDiagRespSig_F2_EE_ISig_3 7;
BA_ "Platform_VMCU1_Sig" SG_ 2671833838 PhysDiagRespSig_F2_EE_ISig_3 1;
BA_ "GenSigSendType" SG_ 2671833640 PhysDiagRespSig_F2_28_ISig_3 7;
BA_ "Platform_VMCU1_Sig" SG_ 2671833640 PhysDiagRespSig_F2_28_ISig_3 1;
BA_ "GenSigSendType" SG_ 2671833617 PhysDiagRespSig_F2_11_ISig_3 7;
BA_ "Platform_VMCU1_Sig" SG_ 2671833617 PhysDiagRespSig_F2_11_ISig_3 1;
BA_ "GenSigSendType" SG_ 2671833361 PhysDiagRespSig_F1_11_ISig_3 7;
BA_ "Platform_VMCU1_Sig" SG_ 2671833361 PhysDiagRespSig_F1_11_ISig_3 1;
BA_ "GenSigSendType" SG_ 2671832818 PhysDiagReqSig_EE_F2_ISig_3 7;
BA_ "Platform_VMCU1_Sig" SG_ 2671832818 PhysDiagReqSig_EE_F2_ISig_3 1;
BA_ "GenSigSendType" SG_ 2671782130 PhysDiagReqSig_28_F2_ISig_3 7;
BA_ "Platform_VMCU1_Sig" SG_ 2671782130 PhysDiagReqSig_28_F2_ISig_3 1;
BA_ "GenSigSendType" SG_ 2671776242 PhysDiagReqSig_11_F2_ISig_3 7;
BA_ "Platform_VMCU1_Sig" SG_ 2671776242 PhysDiagReqSig_11_F2_ISig_3 1;
BA_ "GenSigSendType" SG_ 2671776241 PhysDiagReqSig_11_F1_ISig_3 7;
BA_ "Platform_VMCU1_Sig" SG_ 2671776241 PhysDiagReqSig_11_F1_ISig_3 1;
BA_ "GenSigCycleTime" SG_ 2566759457 Pto2EnableSwitch 100;
BA_ "GenSigCycleTimeActive" SG_ 2566759457 Pto2EnableSwitch 100;
BA_ "GenSigStartValue" SG_ 2566759457 Pto2EnableSwitch 3;
BA_ "Platform_VMCU1_Sig" SG_ 2566759457 Pto2EnableSwitch 1;
BA_ "SPN" SG_ 2566759457 Pto2EnableSwitch 3453;
BA_ "GenSigCycleTime" SG_ 2566759457 Pto1EnableSwitch 100;
BA_ "GenSigCycleTimeActive" SG_ 2566759457 Pto1EnableSwitch 100;
BA_ "GenSigStartValue" SG_ 2566759457 Pto1EnableSwitch 3;
BA_ "Platform_VMCU1_Sig" SG_ 2566759457 Pto1EnableSwitch 1;
BA_ "SPN" SG_ 2566759457 Pto1EnableSwitch 3452;
BA_ "GenSigCycleTime" SG_ 2566759427 Pto2EngagementConsent 100;
BA_ "GenSigCycleTimeActive" SG_ 2566759427 Pto2EngagementConsent 100;
BA_ "GenSigStartValue" SG_ 2566759427 Pto2EngagementConsent 3;
BA_ "Platform_VMCU1_Sig" SG_ 2566759427 Pto2EngagementConsent 1;
BA_ "SPN" SG_ 2566759427 Pto2EngagementConsent 3457;
BA_ "GenSigCycleTime" SG_ 2566759427 Pto1EngagementConsent 100;
BA_ "GenSigCycleTimeActive" SG_ 2566759427 Pto1EngagementConsent 100;
BA_ "GenSigStartValue" SG_ 2566759427 Pto1EngagementConsent 3;
BA_ "Platform_VMCU1_Sig" SG_ 2566759427 Pto1EngagementConsent 1;
BA_ "SPN" SG_ 2566759427 Pto1EngagementConsent 3456;
BA_ "GenSigSendType" SG_ 2671850481 FuncDiagDataOBD_ISig_3 7;
BA_ "Platform_VMCU1_Sig" SG_ 2671850481 FuncDiagDataOBD_ISig_3 1;
BA_ "GenSigCycleTime" SG_ 2566844928 InstantaneousFuelEconomy_ISig_3 100;
BA_ "GenSigCycleTimeActive" SG_ 2566844928 InstantaneousFuelEconomy_ISig_3 100;
BA_ "GenSigStartValue" SG_ 2566844928 InstantaneousFuelEconomy_ISig_3 65535;
BA_ "Platform_VMCU1_Sig" SG_ 2566844928 InstantaneousFuelEconomy_ISig_3 1;
BA_ "SPN" SG_ 2566844928 InstantaneousFuelEconomy_ISig_3 184;
BA_ "GenSigCycleTime" SG_ 2566844928 EngineFuelRate_ISig_3 100;
BA_ "GenSigCycleTimeActive" SG_ 2566844928 EngineFuelRate_ISig_3 100;
BA_ "GenSigStartValue" SG_ 2566844928 EngineFuelRate_ISig_3 65535;
BA_ "Platform_VMCU1_Sig" SG_ 2566844928 EngineFuelRate_ISig_3 1;
BA_ "SPN" SG_ 2566844928 EngineFuelRate_ISig_3 183;
BA_ "GenSigSendType" SG_ 2564428270 KWP2000Response_TACHO 1;
BA_ "Platform_VMCU1_Sig" SG_ 2564428270 KWP2000Response_TACHO 1;
BA_ "GenSigSendType" SG_ 2564484625 KWP2000Request_TACHO 1;
BA_ "Platform_VMCU1_Sig" SG_ 2564484625 KWP2000Request_TACHO 1;
BA_ "GenSigSendType" SG_ 2671902708 FuncDiagDataIntTesterTGW2_ISig_3 7;
BA_ "Platform_VMCU1_Sig" SG_ 2671902708 FuncDiagDataIntTesterTGW2_ISig_3 1;
BA_ "GenSigCycleTime" SG_ 2566825472 EngineTurbo1BoostPressure 100;
BA_ "GenSigCycleTimeActive" SG_ 2566825472 EngineTurbo1BoostPressure 100;
BA_ "GenSigStartValue" SG_ 2566825472 EngineTurbo1BoostPressure 65535;
BA_ "Platform_VMCU1_Sig" SG_ 2566825472 EngineTurbo1BoostPressure 1;
BA_ "SPN" SG_ 2566825472 EngineTurbo1BoostPressure 1127;
BA_ "GenSigCycleTime" SG_ 2566845952 EngIntakeManifold1Temp 100;
BA_ "GenSigCycleTimeActive" SG_ 2566845952 EngIntakeManifold1Temp 100;
BA_ "GenSigStartValue" SG_ 2566845952 EngIntakeManifold1Temp 255;
BA_ "GenSigCycleTime" SG_ 2298372875 FrontAxleRightWheelSpeed_ISig_3 100;
BA_ "GenSigCycleTimeActive" SG_ 2298372875 FrontAxleRightWheelSpeed_ISig_3 100;
BA_ "GenSigStartValue" SG_ 2298372875 FrontAxleRightWheelSpeed_ISig_3 65535;
BA_ "Platform_VMCU1_Sig" SG_ 2298372875 FrontAxleRightWheelSpeed_ISig_3 1;
BA_ "SPN" SG_ 2298372875 FrontAxleRightWheelSpeed_ISig_3 1593;
BA_ "SeToolAncestorID_SIGNAL" SG_ 2298372875 FrontAxleRightWheelSpeed_ISig_3 "x0000001D0410DA6F";
BA_ "SeToolItemID_SIGNAL" SG_ 2298372875 FrontAxleRightWheelSpeed_ISig_3 "x0000001D0410DA6F";
BA_ "SeToolName_SIGNAL" SG_ 2298372875 FrontAxleRightWheelSpeed_ISig_3 "FrontAxleRightWheelSpeed";
BA_ "SeToolVersion_SIGNAL" SG_ 2298372875 FrontAxleRightWheelSpeed_ISig_3 "1";
BA_ "GenSigCycleTime" SG_ 2298372875 RearAxleLeftWheelSpeed_ISig_3 100;
BA_ "GenSigCycleTimeActive" SG_ 2298372875 RearAxleLeftWheelSpeed_ISig_3 100;
BA_ "GenSigStartValue" SG_ 2298372875 RearAxleLeftWheelSpeed_ISig_3 65535;
BA_ "Platform_VMCU1_Sig" SG_ 2298372875 RearAxleLeftWheelSpeed_ISig_3 1;
BA_ "SPN" SG_ 2298372875 RearAxleLeftWheelSpeed_ISig_3 1594;
BA_ "SeToolAncestorID_SIGNAL" SG_ 2298372875 RearAxleLeftWheelSpeed_ISig_3 "x0000001D0410DA87";
BA_ "SeToolItemID_SIGNAL" SG_ 2298372875 RearAxleLeftWheelSpeed_ISig_3 "x0000001D0410DA87";
BA_ "SeToolName_SIGNAL" SG_ 2298372875 RearAxleLeftWheelSpeed_ISig_3 "RearAxleLeftWheelSpeed";
BA_ "SeToolVersion_SIGNAL" SG_ 2298372875 RearAxleLeftWheelSpeed_ISig_3 "1";
BA_ "GenSigCycleTime" SG_ 2298372875 RearAxleRightWheelSpeed_ISig_3 100;
BA_ "GenSigCycleTimeActive" SG_ 2298372875 RearAxleRightWheelSpeed_ISig_3 100;
BA_ "GenSigStartValue" SG_ 2298372875 RearAxleRightWheelSpeed_ISig_3 65535;
BA_ "Platform_VMCU1_Sig" SG_ 2298372875 RearAxleRightWheelSpeed_ISig_3 1;
BA_ "SPN" SG_ 2298372875 RearAxleRightWheelSpeed_ISig_3 1595;
BA_ "SeToolAncestorID_SIGNAL" SG_ 2298372875 RearAxleRightWheelSpeed_ISig_3 "x0000001D0410DA80";
BA_ "SeToolItemID_SIGNAL" SG_ 2298372875 RearAxleRightWheelSpeed_ISig_3 "x0000001D0410DA80";
BA_ "SeToolName_SIGNAL" SG_ 2298372875 RearAxleRightWheelSpeed_ISig_3 "RearAxleRightWheelSpeed";
BA_ "SeToolVersion_SIGNAL" SG_ 2298372875 RearAxleRightWheelSpeed_ISig_3 "1";
BA_ "GenSigCycleTime" SG_ 2298372875 FrontAxleLeftWheelSpeed_ISig_3 100;
BA_ "GenSigCycleTimeActive" SG_ 2298372875 FrontAxleLeftWheelSpeed_ISig_3 100;
BA_ "GenSigStartValue" SG_ 2298372875 FrontAxleLeftWheelSpeed_ISig_3 65535;
BA_ "Platform_VMCU1_Sig" SG_ 2298372875 FrontAxleLeftWheelSpeed_ISig_3 1;
BA_ "SPN" SG_ 2298372875 FrontAxleLeftWheelSpeed_ISig_3 1592;
BA_ "SeToolAncestorID_SIGNAL" SG_ 2298372875 FrontAxleLeftWheelSpeed_ISig_3 "x0000001D0410DA66";
BA_ "SeToolItemID_SIGNAL" SG_ 2298372875 FrontAxleLeftWheelSpeed_ISig_3 "x0000001D0410DA66";
BA_ "SeToolName_SIGNAL" SG_ 2298372875 FrontAxleLeftWheelSpeed_ISig_3 "FrontAxleLeftWheelSpeed";
BA_ "SeToolVersion_SIGNAL" SG_ 2298372875 FrontAxleLeftWheelSpeed_ISig_3 "1";
BA_ "GenSigCycleTime" SG_ 2566719744 HighResEngineTotalFuelUsed_ISig_ 100;
BA_ "GenSigCycleTimeActive" SG_ 2566719744 HighResEngineTotalFuelUsed_ISig_ 100;
BA_ "GenSigStartValue" SG_ 2566719744 HighResEngineTotalFuelUsed_ISig_ 4294967295;
BA_ "Platform_VMCU1_Sig" SG_ 2566719744 HighResEngineTotalFuelUsed_ISig_ 1;
BA_ "SPN" SG_ 2566719744 HighResEngineTotalFuelUsed_ISig_ 5054;
BA_ "SystemSignalLongSymbol" SG_ 2566719744 HighResEngineTotalFuelUsed_ISig_ "HighResEngineTotalFuelUsed_ISig_3";
BA_ "GenSigCycleTime" SG_ 2566841600 EngineRevolutions_ISig_3 100;
BA_ "GenSigCycleTimeActive" SG_ 2566841600 EngineRevolutions_ISig_3 100;
BA_ "GenSigStartValue" SG_ 2566841600 EngineRevolutions_ISig_3 4294967295;
BA_ "Platform_VMCU1_Sig" SG_ 2566841600 EngineRevolutions_ISig_3 1;
BA_ "SPN" SG_ 2566841600 EngineRevolutions_ISig_3 249;
BA_ "GenSigCycleTime" SG_ 2499788567 AutoRearAxleDiffLockActvn_rqst 100;
BA_ "GenSigCycleTimeActive" SG_ 2499788567 AutoRearAxleDiffLockActvn_rqst 100;
BA_ "GenSigStartValue" SG_ 2499788567 AutoRearAxleDiffLockActvn_rqst 7;
BA_ "Platform_VMCU1_Sig" SG_ 2499788567 AutoRearAxleDiffLockActvn_rqst 1;
BA_ "SeToolAncestorID_SIGNAL" SG_ 2499788567 AutoRearAxleDiffLockActvn_rqst "x0000001D04417EE5";
BA_ "SeToolItemID_SIGNAL" SG_ 2499788567 AutoRearAxleDiffLockActvn_rqst "x0000001D04417EE5";
BA_ "SeToolName_SIGNAL" SG_ 2499788567 AutoRearAxleDiffLockActvn_rqst "AutomaticRearAxleDiffLockActivationRequest";
BA_ "SeToolVersion_SIGNAL" SG_ 2499788567 AutoRearAxleDiffLockActvn_rqst "1";
BA_ "GenSigCycleTime" SG_ 2499788567 EHSClutchEngagmntOffsetOpCtrl_IS 100;
BA_ "GenSigCycleTimeActive" SG_ 2499788567 EHSClutchEngagmntOffsetOpCtrl_IS 100;
BA_ "GenSigStartValue" SG_ 2499788567 EHSClutchEngagmntOffsetOpCtrl_IS 63;
BA_ "SystemSignalLongSymbol" SG_ 2499788567 EHSClutchEngagmntOffsetOpCtrl_IS "EHSClutchEngagmntOffsetOpCtrl_ISig_3";
BA_ "GenSigCycleTime" SG_ 2499788567 Trailer1LiftAxle1PosReq 100;
BA_ "GenSigCycleTimeActive" SG_ 2499788567 Trailer1LiftAxle1PosReq 100;
BA_ "GenSigStartValue" SG_ 2499788567 Trailer1LiftAxle1PosReq 3;
BA_ "Platform_VMCU1_Sig" SG_ 2499788567 Trailer1LiftAxle1PosReq 1;
BA_ "GenSigCycleTime" SG_ 2499788567 Trailer2LiftAxle2PosReq 100;
BA_ "GenSigCycleTimeActive" SG_ 2499788567 Trailer2LiftAxle2PosReq 100;
BA_ "GenSigStartValue" SG_ 2499788567 Trailer2LiftAxle2PosReq 3;
BA_ "Platform_VMCU1_Sig" SG_ 2499788567 Trailer2LiftAxle2PosReq 1;
BA_ "GenSigCycleTime" SG_ 2499788567 DrvrRetarderBrakeBlending_rqst_I 100;
BA_ "GenSigCycleTimeActive" SG_ 2499788567 DrvrRetarderBrakeBlending_rqst_I 100;
BA_ "GenSigStartValue" SG_ 2499788567 DrvrRetarderBrakeBlending_rqst_I 3;
BA_ "GenSigMaxLatency" SG_ 2499788567 DrvrRetarderBrakeBlending_rqst_I 65;
BA_ "Platform_VMCU1_Sig" SG_ 2499788567 DrvrRetarderBrakeBlending_rqst_I 1;
BA_ "SeToolAncestorID_SIGNAL" SG_ 2499788567 DrvrRetarderBrakeBlending_rqst_I "x0000001D0413D707";
BA_ "SeToolItemID_SIGNAL" SG_ 2499788567 DrvrRetarderBrakeBlending_rqst_I "x0000001D043135DD";
BA_ "SeToolName_SIGNAL" SG_ 2499788567 DrvrRetarderBrakeBlending_rqst_I "DriverRetarderBrakeBlendingRequest";
BA_ "SeToolVersion_SIGNAL" SG_ 2499788567 DrvrRetarderBrakeBlending_rqst_I "2";
BA_ "SystemSignalLongSymbol" SG_ 2499788567 DrvrRetarderBrakeBlending_rqst_I "DrvrRetarderBrakeBlending_rqst_ISig_3";
BA_ "GenSigCycleTime" SG_ 2499788567 DrvrRetarderBrakeProgram_rqst_IS 100;
BA_ "GenSigCycleTimeActive" SG_ 2499788567 DrvrRetarderBrakeProgram_rqst_IS 100;
BA_ "GenSigStartValue" SG_ 2499788567 DrvrRetarderBrakeProgram_rqst_IS 3;
BA_ "GenSigMaxLatency" SG_ 2499788567 DrvrRetarderBrakeProgram_rqst_IS 65;
BA_ "Platform_VMCU1_Sig" SG_ 2499788567 DrvrRetarderBrakeProgram_rqst_IS 1;
BA_ "SeToolAncestorID_SIGNAL" SG_ 2499788567 DrvrRetarderBrakeProgram_rqst_IS "x0000001D0414BF93";
BA_ "SeToolItemID_SIGNAL" SG_ 2499788567 DrvrRetarderBrakeProgram_rqst_IS "x0000001D042D7CE4";
BA_ "SeToolName_SIGNAL" SG_ 2499788567 DrvrRetarderBrakeProgram_rqst_IS "DriverRetarderBrakeProgramRequest";
BA_ "SeToolVersion_SIGNAL" SG_ 2499788567 DrvrRetarderBrakeProgram_rqst_IS "2";
BA_ "SystemSignalLongSymbol" SG_ 2499788567 DrvrRetarderBrakeProgram_rqst_IS "DrvrRetarderBrakeProgram_rqst_ISig_3";
BA_ "GenSigCycleTime" SG_ 2499788567 RollerBenchModeRequest 100;
BA_ "GenSigCycleTimeActive" SG_ 2499788567 RollerBenchModeRequest 100;
BA_ "GenSigStartValue" SG_ 2499788567 RollerBenchModeRequest 3;
BA_ "Platform_VMCU1_Sig" SG_ 2499788567 RollerBenchModeRequest 1;
BA_ "GenSigCycleTime" SG_ 2499788567 GearLeverPositionBackup 100;
BA_ "GenSigCycleTimeActive" SG_ 2499788567 GearLeverPositionBackup 100;
BA_ "GenSigStartValue" SG_ 2499788567 GearLeverPositionBackup 15;
BA_ "Platform_VMCU1_Sig" SG_ 2499788567 GearLeverPositionBackup 1;
BA_ "GenSigCycleTime" SG_ 2499788567 EHSClutchEngagmntCalibOpCtrl_ISi 100;
BA_ "GenSigCycleTimeActive" SG_ 2499788567 EHSClutchEngagmntCalibOpCtrl_ISi 100;
BA_ "GenSigStartValue" SG_ 2499788567 EHSClutchEngagmntCalibOpCtrl_ISi 3;
BA_ "SystemSignalLongSymbol" SG_ 2499788567 EHSClutchEngagmntCalibOpCtrl_ISi "EHSClutchEngagmntCalibOpCtrl_ISig_3";
BA_ "GenSigCycleTime" SG_ 2499788567 Trailer3LiftAxle2PosReq 100;
BA_ "GenSigCycleTimeActive" SG_ 2499788567 Trailer3LiftAxle2PosReq 100;
BA_ "GenSigStartValue" SG_ 2499788567 Trailer3LiftAxle2PosReq 3;
BA_ "Platform_VMCU1_Sig" SG_ 2499788567 Trailer3LiftAxle2PosReq 1;
BA_ "GenSigCycleTime" SG_ 2499788567 Trailer1LiftAxle2PosReq 100;
BA_ "GenSigCycleTimeActive" SG_ 2499788567 Trailer1LiftAxle2PosReq 100;
BA_ "GenSigStartValue" SG_ 2499788567 Trailer1LiftAxle2PosReq 3;
BA_ "Platform_VMCU1_Sig" SG_ 2499788567 Trailer1LiftAxle2PosReq 1;
BA_ "GenSigCycleTime" SG_ 2499788567 DriverRetarderRequest_ISig_3 100;
BA_ "GenSigCycleTimeActive" SG_ 2499788567 DriverRetarderRequest_ISig_3 100;
BA_ "GenSigStartValue" SG_ 2499788567 DriverRetarderRequest_ISig_3 7;
BA_ "GenSigMaxLatency" SG_ 2499788567 DriverRetarderRequest_ISig_3 65;
BA_ "Platform_VMCU1_Sig" SG_ 2499788567 DriverRetarderRequest_ISig_3 1;
BA_ "SeToolAncestorID_SIGNAL" SG_ 2499788567 DriverRetarderRequest_ISig_3 "x0000001D0414BEA2";
BA_ "SeToolItemID_SIGNAL" SG_ 2499788567 DriverRetarderRequest_ISig_3 "x0000001D043806A5";
BA_ "SeToolName_SIGNAL" SG_ 2499788567 DriverRetarderRequest_ISig_3 "DriverRetarderRequest";
BA_ "SeToolVersion_SIGNAL" SG_ 2499788567 DriverRetarderRequest_ISig_3 "2";
BA_ "GenSigCycleTime" SG_ 2499788567 Trailer3LiftAxle1PosReq 100;
BA_ "GenSigCycleTimeActive" SG_ 2499788567 Trailer3LiftAxle1PosReq 100;
BA_ "GenSigStartValue" SG_ 2499788567 Trailer3LiftAxle1PosReq 3;
BA_ "Platform_VMCU1_Sig" SG_ 2499788567 Trailer3LiftAxle1PosReq 1;
BA_ "GenSigCycleTime" SG_ 2499788567 Trailer2LiftAxle1PosReq 100;
BA_ "GenSigCycleTimeActive" SG_ 2499788567 Trailer2LiftAxle1PosReq 100;
BA_ "GenSigStartValue" SG_ 2499788567 Trailer2LiftAxle1PosReq 3;
BA_ "Platform_VMCU1_Sig" SG_ 2499788567 Trailer2LiftAxle1PosReq 1;
BA_REL_ "GenSigFirstTimeoutTime" BU_SG_REL_ EBS SG_ 2348814097 TSC1EMSrVMCU_EnRSpdCtrlC 3000;
BA_REL_ "GenSigTimeoutTime" BU_SG_REL_ EBS SG_ 2348814097 TSC1EMSrVMCU_EnRSpdCtrlC 300;
BA_REL_ "GenSigFirstTimeoutTime" BU_SG_REL_ EMS SG_ 2348814097 TSC1EMSrVMCU_EnRSpdCtrlC 3000;
BA_REL_ "GenSigTimeoutTime" BU_SG_REL_ EMS SG_ 2348814097 TSC1EMSrVMCU_EnRSpdCtrlC 300;
BA_REL_ "GenSigFirstTimeoutTime" BU_SG_REL_ EMS SG_ 2348814097 TSC1EMSrVMCU_EnRTrqTrqLm 3000;
BA_REL_ "GenSigTimeoutTime" BU_SG_REL_ EMS SG_ 2348814097 TSC1EMSrVMCU_EnRTrqTrqLm 300;
BA_REL_ "GenSigFirstTimeoutTime" BU_SG_REL_ EBS SG_ 2348814097 TSC1EMSrVMCU_EnRTrqTrqLm 3000;
BA_REL_ "GenSigTimeoutTime" BU_SG_REL_ EBS SG_ 2348814097 TSC1EMSrVMCU_EnRTrqTrqLm 300;
BA_REL_ "GenSigFirstTimeoutTime" BU_SG_REL_ EMS SG_ 2348814097 TSC1EMSrVMCU_OvrdCtrlMPr 3000;
BA_REL_ "GenSigTimeoutTime" BU_SG_REL_ EMS SG_ 2348814097 TSC1EMSrVMCU_OvrdCtrlMPr 300;
BA_REL_ "GenSigFirstTimeoutTime" BU_SG_REL_ EBS SG_ 2348814097 TSC1EMSrVMCU_OvrdCtrlMPr 3000;
BA_REL_ "GenSigTimeoutTime" BU_SG_REL_ EBS SG_ 2348814097 TSC1EMSrVMCU_OvrdCtrlMPr 300;
BA_REL_ "GenSigFirstTimeoutTime" BU_SG_REL_ EBS SG_ 2348814097 TSC1EMSrVMCU_EnRSpdSpdLm 3000;
BA_REL_ "GenSigTimeoutTime" BU_SG_REL_ EBS SG_ 2348814097 TSC1EMSrVMCU_EnRSpdSpdLm 300;
BA_REL_ "GenSigFirstTimeoutTime" BU_SG_REL_ EMS SG_ 2348814097 TSC1EMSrVMCU_EnRSpdSpdLm 3000;
BA_REL_ "GenSigTimeoutTime" BU_SG_REL_ EMS SG_ 2348814097 TSC1EMSrVMCU_EnRSpdSpdLm 300;
BA_REL_ "GenSigFirstTimeoutTime" BU_SG_REL_ EMS SG_ 2348814097 TSC1EMSrVMCU_EnOvrdCtrlM 3000;
BA_REL_ "GenSigTimeoutTime" BU_SG_REL_ EMS SG_ 2348814097 TSC1EMSrVMCU_EnOvrdCtrlM 300;
BA_REL_ "GenSigFirstTimeoutTime" BU_SG_REL_ EBS SG_ 2348814097 TSC1EMSrVMCU_EnOvrdCtrlM 3000;
BA_REL_ "GenSigTimeoutTime" BU_SG_REL_ EBS SG_ 2348814097 TSC1EMSrVMCU_EnOvrdCtrlM 300;
BA_REL_ "GenSigFirstTimeoutTime" BU_SG_REL_ EMS SG_ 2348814083 TSC1EMSrTECU_OvrdCtrlMPr 3000;
BA_REL_ "GenSigTimeoutTime" BU_SG_REL_ EMS SG_ 2348814083 TSC1EMSrTECU_OvrdCtrlMPr 300;
BA_REL_ "GenSigFirstTimeoutTime" BU_SG_REL_ EMS SG_ 2348814083 TSC1EMSrTECU_EnRSpdCtrlC 3000;
BA_REL_ "GenSigTimeoutTime" BU_SG_REL_ EMS SG_ 2348814083 TSC1EMSrTECU_EnRSpdCtrlC 300;
BA_REL_ "GenSigFirstTimeoutTime" BU_SG_REL_ EMS SG_ 2348814083 TSC1EMSrTECU_EnOvrdCtrlM 3000;
BA_REL_ "GenSigTimeoutTime" BU_SG_REL_ EMS SG_ 2348814083 TSC1EMSrTECU_EnOvrdCtrlM 300;
BA_REL_ "GenSigFirstTimeoutTime" BU_SG_REL_ EMS SG_ 2348814083 TSC1EMSrTECU_EnRTrqTrqLm 3000;
BA_REL_ "GenSigTimeoutTime" BU_SG_REL_ EMS SG_ 2348814083 TSC1EMSrTECU_EnRTrqTrqLm 300;
BA_REL_ "GenSigFirstTimeoutTime" BU_SG_REL_ EMS SG_ 2348814083 TSC1EMSrTECU_EnRSpdSpdLm 3000;
BA_REL_ "GenSigTimeoutTime" BU_SG_REL_ EMS SG_ 2348814083 TSC1EMSrTECU_EnRSpdSpdLm 300;
BA_REL_ "GenSigFirstTimeoutTime" BU_SG_REL_ TECU SG_ 2348814091 TSC1EMSrABS_EnRTrqTrqLm 3000;
BA_REL_ "GenSigTimeoutTime" BU_SG_REL_ TECU SG_ 2348814091 TSC1EMSrABS_EnRTrqTrqLm 300;
BA_REL_ "GenSigFirstTimeoutTime" BU_SG_REL_ EMS SG_ 2348814091 TSC1EMSrABS_EnRTrqTrqLm 3000;
BA_REL_ "GenSigTimeoutTime" BU_SG_REL_ EMS SG_ 2348814091 TSC1EMSrABS_EnRTrqTrqLm 300;
BA_REL_ "GenSigFirstTimeoutTime" BU_SG_REL_ TECU SG_ 2348814091 TSC1EMSrABS_EnRSpdCtrlC 3000;
BA_REL_ "GenSigTimeoutTime" BU_SG_REL_ TECU SG_ 2348814091 TSC1EMSrABS_EnRSpdCtrlC 300;
BA_REL_ "GenSigFirstTimeoutTime" BU_SG_REL_ EMS SG_ 2348814091 TSC1EMSrABS_EnRSpdCtrlC 3000;
BA_REL_ "GenSigTimeoutTime" BU_SG_REL_ EMS SG_ 2348814091 TSC1EMSrABS_EnRSpdCtrlC 300;
BA_REL_ "GenSigFirstTimeoutTime" BU_SG_REL_ TECU SG_ 2348814091 TSC1EMSrABS_OvrdCtrlMPr 3000;
BA_REL_ "GenSigTimeoutTime" BU_SG_REL_ TECU SG_ 2348814091 TSC1EMSrABS_OvrdCtrlMPr 300;
BA_REL_ "GenSigFirstTimeoutTime" BU_SG_REL_ EMS SG_ 2348814091 TSC1EMSrABS_OvrdCtrlMPr 3000;
BA_REL_ "GenSigTimeoutTime" BU_SG_REL_ EMS SG_ 2348814091 TSC1EMSrABS_OvrdCtrlMPr 300;
BA_REL_ "GenSigFirstTimeoutTime" BU_SG_REL_ TECU SG_ 2348814091 TSC1EMSrABS_EnOvrdCtrlM 3000;
BA_REL_ "GenSigTimeoutTime" BU_SG_REL_ TECU SG_ 2348814091 TSC1EMSrABS_EnOvrdCtrlM 300;
BA_REL_ "GenSigFirstTimeoutTime" BU_SG_REL_ EMS SG_ 2348814091 TSC1EMSrABS_EnOvrdCtrlM 3000;
BA_REL_ "GenSigTimeoutTime" BU_SG_REL_ EMS SG_ 2348814091 TSC1EMSrABS_EnOvrdCtrlM 300;
BA_REL_ "GenSigFirstTimeoutTime" BU_SG_REL_ TECU SG_ 2348814091 TSC1EMSrABS_EnRSpdSpdLm 3000;
BA_REL_ "GenSigTimeoutTime" BU_SG_REL_ TECU SG_ 2348814091 TSC1EMSrABS_EnRSpdSpdLm 300;
BA_REL_ "GenSigFirstTimeoutTime" BU_SG_REL_ EMS SG_ 2348814091 TSC1EMSrABS_EnRSpdSpdLm 3000;
BA_REL_ "GenSigTimeoutTime" BU_SG_REL_ EMS SG_ 2348814091 TSC1EMSrABS_EnRSpdSpdLm 300;
BA_REL_ "GenSigFirstTimeoutTime" BU_SG_REL_ BBM SG_ 2566846467 TransmissionOilTemp_ISig_3 24000;
BA_REL_ "GenSigTimeoutTime" BU_SG_REL_ BBM SG_ 2566846467 TransmissionOilTemp_ISig_3 6000;
BA_REL_ "GenSigFirstTimeoutTime" BU_SG_REL_ EMS SG_ 2566846467 TransmissionOilTemp_ISig_3 24000;
BA_REL_ "GenSigTimeoutTime" BU_SG_REL_ EMS SG_ 2566846467 TransmissionOilTemp_ISig_3 6000;
BA_REL_ "GenSigFirstTimeoutTime" BU_SG_REL_ HMIIOM SG_ 2566846467 TransmissionOilTemp_ISig_3 24000;
BA_REL_ "GenSigTimeoutTime" BU_SG_REL_ HMIIOM SG_ 2566846467 TransmissionOilTemp_ISig_3 6000;
BA_REL_ "GenSigFirstTimeoutTime" BU_SG_REL_ HMIIOM SG_ 2566846467 TransmissionOilLevel_ISig_3 24000;
BA_REL_ "GenSigTimeoutTime" BU_SG_REL_ HMIIOM SG_ 2566846467 TransmissionOilLevel_ISig_3 6000;
BA_REL_ "GenSigFirstTimeoutTime" BU_SG_REL_ HMIIOM SG_ 2566882307 TransmissionGCVW_ISig_3 3000;
BA_REL_ "GenSigTimeoutTime" BU_SG_REL_ HMIIOM SG_ 2566882307 TransmissionGCVW_ISig_3 600;
BA_REL_ "GenSigFirstTimeoutTime" BU_SG_REL_ EMS SG_ 2566882307 TransmissionGCVW_ISig_3 3000;
BA_REL_ "GenSigTimeoutTime" BU_SG_REL_ EMS SG_ 2566882307 TransmissionGCVW_ISig_3 570;
BA_REL_ "GenSigFirstTimeoutTime" BU_SG_REL_ VMCU SG_ 2566882307 TransmissionGCVW_ISig_3 3000;
BA_REL_ "GenSigTimeoutTime" BU_SG_REL_ VMCU SG_ 2566882307 TransmissionGCVW_ISig_3 570;
BA_REL_ "GenSigFirstTimeoutTime" BU_SG_REL_ EBS SG_ 2566882307 PermittedHSAPressure 3000;
BA_REL_ "GenSigTimeoutTime" BU_SG_REL_ EBS SG_ 2566882307 PermittedHSAPressure 570;
BA_REL_ "GenSigFirstTimeoutTime" BU_SG_REL_ VMCU SG_ 2566882307 TransmEngineCrankEnable_ISig_3 3000;
BA_REL_ "GenSigTimeoutTime" BU_SG_REL_ VMCU SG_ 2566882307 TransmEngineCrankEnable_ISig_3 570;
BA_REL_ "GenSigFirstTimeoutTime" BU_SG_REL_ HMIIOM SG_ 2566842094 TachographLocalMinuteOffset_ISig 24000;
BA_REL_ "GenSigTimeoutTime" BU_SG_REL_ HMIIOM SG_ 2566842094 TachographLocalMinuteOffset_ISig 6000;
BA_REL_ "GenSigFirstTimeoutTime" BU_SG_REL_ BBM SG_ 2566842094 TachographLocalMinuteOffset_ISig 24000;
BA_REL_ "GenSigTimeoutTime" BU_SG_REL_ BBM SG_ 2566842094 TachographLocalMinuteOffset_ISig 6000;
BA_REL_ "GenSigFirstTimeoutTime" BU_SG_REL_ HMIIOM SG_ 2566842094 TachographMinutes 24000;
BA_REL_ "GenSigTimeoutTime" BU_SG_REL_ HMIIOM SG_ 2566842094 TachographMinutes 6000;
BA_REL_ "GenSigFirstTimeoutTime" BU_SG_REL_ HMIIOM SG_ 2566842094 TachographYears 24000;
BA_REL_ "GenSigTimeoutTime" BU_SG_REL_ HMIIOM SG_ 2566842094 TachographYears 6000;
BA_REL_ "GenSigFirstTimeoutTime" BU_SG_REL_ HMIIOM SG_ 2566842094 TachographSeconds 24000;
BA_REL_ "GenSigTimeoutTime" BU_SG_REL_ HMIIOM SG_ 2566842094 TachographSeconds 6000;
BA_REL_ "GenSigFirstTimeoutTime" BU_SG_REL_ HMIIOM SG_ 2566842094 TachographHours 24000;
BA_REL_ "GenSigTimeoutTime" BU_SG_REL_ HMIIOM SG_ 2566842094 TachographHours 6000;
BA_REL_ "GenSigFirstTimeoutTime" BU_SG_REL_ HMIIOM SG_ 2566842094 TachographMonths 24000;
BA_REL_ "GenSigTimeoutTime" BU_SG_REL_ HMIIOM SG_ 2566842094 TachographMonths 6000;
BA_REL_ "GenSigFirstTimeoutTime" BU_SG_REL_ BBM SG_ 2566842094 TachographLocalHourOffset_ISig_3 24000;
BA_REL_ "GenSigTimeoutTime" BU_SG_REL_ BBM SG_ 2566842094 TachographLocalHourOffset_ISig_3 6000;
BA_REL_ "GenSigFirstTimeoutTime" BU_SG_REL_ HMIIOM SG_ 2566842094 TachographLocalHourOffset_ISig_3 24000;
BA_REL_ "GenSigTimeoutTime" BU_SG_REL_ HMIIOM SG_ 2566842094 TachographLocalHourOffset_ISig_3 6000;
BA_REL_ "GenSigFirstTimeoutTime" BU_SG_REL_ HMIIOM SG_ 2566842094 TachographDays 24000;
BA_REL_ "GenSigTimeoutTime" BU_SG_REL_ HMIIOM SG_ 2566842094 TachographDays 6000;
BA_REL_ "GenSigFirstTimeoutTime" BU_SG_REL_ EBS SG_ 2566841879 MonthUTC_ISig_3 6000;
BA_REL_ "GenSigTimeoutTime" BU_SG_REL_ EBS SG_ 2566841879 MonthUTC_ISig_3 1500;
BA_REL_ "GenSigFirstTimeoutTime" BU_SG_REL_ TECU SG_ 2566841879 MonthUTC_ISig_3 6000;
BA_REL_ "GenSigTimeoutTime" BU_SG_REL_ TECU SG_ 2566841879 MonthUTC_ISig_3 1500;
BA_REL_ "GenSigFirstTimeoutTime" BU_SG_REL_ ACM SG_ 2566841879 MonthUTC_ISig_3 6000;
BA_REL_ "GenSigTimeoutTime" BU_SG_REL_ ACM SG_ 2566841879 MonthUTC_ISig_3 1500;
BA_REL_ "GenSigFirstTimeoutTime" BU_SG_REL_ DACU SG_ 2566841879 MonthUTC_ISig_3 6000;
BA_REL_ "GenSigTimeoutTime" BU_SG_REL_ DACU SG_ 2566841879 MonthUTC_ISig_3 1500;
BA_REL_ "GenSigFirstTimeoutTime" BU_SG_REL_ EMS SG_ 2566841879 MonthUTC_ISig_3 6000;
BA_REL_ "GenSigTimeoutTime" BU_SG_REL_ EMS SG_ 2566841879 MonthUTC_ISig_3 1500;
BA_REL_ "GenSigFirstTimeoutTime" BU_SG_REL_ BBM SG_ 2566841879 MonthUTC_ISig_3 6000;
BA_REL_ "GenSigTimeoutTime" BU_SG_REL_ BBM SG_ 2566841879 MonthUTC_ISig_3 1500;
BA_REL_ "GenSigFirstTimeoutTime" BU_SG_REL_ VMCU SG_ 2566841879 MonthUTC_ISig_3 6000;
BA_REL_ "GenSigTimeoutTime" BU_SG_REL_ VMCU SG_ 2566841879 MonthUTC_ISig_3 1500;
BA_REL_ "GenSigFirstTimeoutTime" BU_SG_REL_ CIOM SG_ 2566841879 MonthUTC_ISig_3 6000;
BA_REL_ "GenSigTimeoutTime" BU_SG_REL_ CIOM SG_ 2566841879 MonthUTC_ISig_3 1500;
BA_REL_ "GenSigFirstTimeoutTime" BU_SG_REL_ DACU SG_ 2566841879 SecondsUTC_ISig_3 6000;
BA_REL_ "GenSigTimeoutTime" BU_SG_REL_ DACU SG_ 2566841879 SecondsUTC_ISig_3 1500;
BA_REL_ "GenSigFirstTimeoutTime" BU_SG_REL_ TECU SG_ 2566841879 SecondsUTC_ISig_3 6000;
BA_REL_ "GenSigTimeoutTime" BU_SG_REL_ TECU SG_ 2566841879 SecondsUTC_ISig_3 1500;
BA_REL_ "GenSigFirstTimeoutTime" BU_SG_REL_ CIOM SG_ 2566841879 SecondsUTC_ISig_3 6000;
BA_REL_ "GenSigTimeoutTime" BU_SG_REL_ CIOM SG_ 2566841879 SecondsUTC_ISig_3 1500;
BA_REL_ "GenSigFirstTimeoutTime" BU_SG_REL_ ACM SG_ 2566841879 SecondsUTC_ISig_3 6000;
BA_REL_ "GenSigTimeoutTime" BU_SG_REL_ ACM SG_ 2566841879 SecondsUTC_ISig_3 1500;
BA_REL_ "GenSigFirstTimeoutTime" BU_SG_REL_ VMCU SG_ 2566841879 SecondsUTC_ISig_3 6000;
BA_REL_ "GenSigTimeoutTime" BU_SG_REL_ VMCU SG_ 2566841879 SecondsUTC_ISig_3 1500;
BA_REL_ "GenSigFirstTimeoutTime" BU_SG_REL_ BBM SG_ 2566841879 SecondsUTC_ISig_3 6000;
BA_REL_ "GenSigTimeoutTime" BU_SG_REL_ BBM SG_ 2566841879 SecondsUTC_ISig_3 1500;
BA_REL_ "GenSigFirstTimeoutTime" BU_SG_REL_ EBS SG_ 2566841879 SecondsUTC_ISig_3 6000;
BA_REL_ "GenSigTimeoutTime" BU_SG_REL_ EBS SG_ 2566841879 SecondsUTC_ISig_3 1500;
BA_REL_ "GenSigFirstTimeoutTime" BU_SG_REL_ EMS SG_ 2566841879 SecondsUTC_ISig_3 6000;
BA_REL_ "GenSigTimeoutTime" BU_SG_REL_ EMS SG_ 2566841879 SecondsUTC_ISig_3 1500;
BA_REL_ "GenSigFirstTimeoutTime" BU_SG_REL_ EBS SG_ 2566841879 HoursUTC_ISig_3 6000;
BA_REL_ "GenSigTimeoutTime" BU_SG_REL_ EBS SG_ 2566841879 HoursUTC_ISig_3 1500;
BA_REL_ "GenSigFirstTimeoutTime" BU_SG_REL_ DACU SG_ 2566841879 HoursUTC_ISig_3 6000;
BA_REL_ "GenSigTimeoutTime" BU_SG_REL_ DACU SG_ 2566841879 HoursUTC_ISig_3 1500;
BA_REL_ "GenSigFirstTimeoutTime" BU_SG_REL_ ACM SG_ 2566841879 HoursUTC_ISig_3 6000;
BA_REL_ "GenSigTimeoutTime" BU_SG_REL_ ACM SG_ 2566841879 HoursUTC_ISig_3 1500;
BA_REL_ "GenSigFirstTimeoutTime" BU_SG_REL_ BBM SG_ 2566841879 HoursUTC_ISig_3 6000;
BA_REL_ "GenSigTimeoutTime" BU_SG_REL_ BBM SG_ 2566841879 HoursUTC_ISig_3 1500;
BA_REL_ "GenSigFirstTimeoutTime" BU_SG_REL_ TECU SG_ 2566841879 HoursUTC_ISig_3 6000;
BA_REL_ "GenSigTimeoutTime" BU_SG_REL_ TECU SG_ 2566841879 HoursUTC_ISig_3 1500;
BA_REL_ "GenSigFirstTimeoutTime" BU_SG_REL_ CIOM SG_ 2566841879 HoursUTC_ISig_3 6000;
BA_REL_ "GenSigTimeoutTime" BU_SG_REL_ CIOM SG_ 2566841879 HoursUTC_ISig_3 1500;
BA_REL_ "GenSigFirstTimeoutTime" BU_SG_REL_ VMCU SG_ 2566841879 HoursUTC_ISig_3 6000;
BA_REL_ "GenSigTimeoutTime" BU_SG_REL_ VMCU SG_ 2566841879 HoursUTC_ISig_3 1500;
BA_REL_ "GenSigFirstTimeoutTime" BU_SG_REL_ EMS SG_ 2566841879 HoursUTC_ISig_3 6000;
BA_REL_ "GenSigTimeoutTime" BU_SG_REL_ EMS SG_ 2566841879 HoursUTC_ISig_3 1500;
BA_REL_ "GenSigFirstTimeoutTime" BU_SG_REL_ EBS SG_ 2566841879 YearUTC_ISig_3 6000;
BA_REL_ "GenSigTimeoutTime" BU_SG_REL_ EBS SG_ 2566841879 YearUTC_ISig_3 1500;
BA_REL_ "GenSigFirstTimeoutTime" BU_SG_REL_ EMS SG_ 2566841879 YearUTC_ISig_3 6000;
BA_REL_ "GenSigTimeoutTime" BU_SG_REL_ EMS SG_ 2566841879 YearUTC_ISig_3 1500;
BA_REL_ "GenSigFirstTimeoutTime" BU_SG_REL_ DACU SG_ 2566841879 YearUTC_ISig_3 6000;
BA_REL_ "GenSigTimeoutTime" BU_SG_REL_ DACU SG_ 2566841879 YearUTC_ISig_3 1500;
BA_REL_ "GenSigFirstTimeoutTime" BU_SG_REL_ VMCU SG_ 2566841879 YearUTC_ISig_3 6000;
BA_REL_ "GenSigTimeoutTime" BU_SG_REL_ VMCU SG_ 2566841879 YearUTC_ISig_3 1500;
BA_REL_ "GenSigFirstTimeoutTime" BU_SG_REL_ ACM SG_ 2566841879 YearUTC_ISig_3 6000;
BA_REL_ "GenSigTimeoutTime" BU_SG_REL_ ACM SG_ 2566841879 YearUTC_ISig_3 1500;
BA_REL_ "GenSigFirstTimeoutTime" BU_SG_REL_ BBM SG_ 2566841879 YearUTC_ISig_3 6000;
BA_REL_ "GenSigTimeoutTime" BU_SG_REL_ BBM SG_ 2566841879 YearUTC_ISig_3 1500;
BA_REL_ "GenSigFirstTimeoutTime" BU_SG_REL_ CIOM SG_ 2566841879 YearUTC_ISig_3 6000;
BA_REL_ "GenSigTimeoutTime" BU_SG_REL_ CIOM SG_ 2566841879 YearUTC_ISig_3 1500;
BA_REL_ "GenSigFirstTimeoutTime" BU_SG_REL_ TECU SG_ 2566841879 YearUTC_ISig_3 6000;
BA_REL_ "GenSigTimeoutTime" BU_SG_REL_ TECU SG_ 2566841879 YearUTC_ISig_3 1500;
BA_REL_ "GenSigFirstTimeoutTime" BU_SG_REL_ TECU SG_ 2566841879 DayUTC_ISig_3 6000;
BA_REL_ "GenSigTimeoutTime" BU_SG_REL_ TECU SG_ 2566841879 DayUTC_ISig_3 1500;
BA_REL_ "GenSigFirstTimeoutTime" BU_SG_REL_ CIOM SG_ 2566841879 DayUTC_ISig_3 6000;
BA_REL_ "GenSigTimeoutTime" BU_SG_REL_ CIOM SG_ 2566841879 DayUTC_ISig_3 1500;
BA_REL_ "GenSigFirstTimeoutTime" BU_SG_REL_ EBS SG_ 2566841879 DayUTC_ISig_3 6000;
BA_REL_ "GenSigTimeoutTime" BU_SG_REL_ EBS SG_ 2566841879 DayUTC_ISig_3 1500;
BA_REL_ "GenSigFirstTimeoutTime" BU_SG_REL_ VMCU SG_ 2566841879 DayUTC_ISig_3 6000;
BA_REL_ "GenSigTimeoutTime" BU_SG_REL_ VMCU SG_ 2566841879 DayUTC_ISig_3 1500;
BA_REL_ "GenSigFirstTimeoutTime" BU_SG_REL_ EMS SG_ 2566841879 DayUTC_ISig_3 6000;
BA_REL_ "GenSigTimeoutTime" BU_SG_REL_ EMS SG_ 2566841879 DayUTC_ISig_3 1500;
BA_REL_ "GenSigFirstTimeoutTime" BU_SG_REL_ DACU SG_ 2566841879 DayUTC_ISig_3 6000;
BA_REL_ "GenSigTimeoutTime" BU_SG_REL_ DACU SG_ 2566841879 DayUTC_ISig_3 1500;
BA_REL_ "GenSigFirstTimeoutTime" BU_SG_REL_ ACM SG_ 2566841879 DayUTC_ISig_3 6000;
BA_REL_ "GenSigTimeoutTime" BU_SG_REL_ ACM SG_ 2566841879 DayUTC_ISig_3 1500;
BA_REL_ "GenSigFirstTimeoutTime" BU_SG_REL_ BBM SG_ 2566841879 DayUTC_ISig_3 6000;
BA_REL_ "GenSigTimeoutTime" BU_SG_REL_ BBM SG_ 2566841879 DayUTC_ISig_3 1500;
BA_REL_ "GenSigFirstTimeoutTime" BU_SG_REL_ DACU SG_ 2566841879 MinutesUTC_ISig_3 6000;
BA_REL_ "GenSigTimeoutTime" BU_SG_REL_ DACU SG_ 2566841879 MinutesUTC_ISig_3 1500;
BA_REL_ "GenSigFirstTimeoutTime" BU_SG_REL_ VMCU SG_ 2566841879 MinutesUTC_ISig_3 6000;
BA_REL_ "GenSigTimeoutTime" BU_SG_REL_ VMCU SG_ 2566841879 MinutesUTC_ISig_3 1500;
BA_REL_ "GenSigFirstTimeoutTime" BU_SG_REL_ TECU SG_ 2566841879 MinutesUTC_ISig_3 6000;
BA_REL_ "GenSigTimeoutTime" BU_SG_REL_ TECU SG_ 2566841879 MinutesUTC_ISig_3 1500;
BA_REL_ "GenSigFirstTimeoutTime" BU_SG_REL_ CIOM SG_ 2566841879 MinutesUTC_ISig_3 6000;
BA_REL_ "GenSigTimeoutTime" BU_SG_REL_ CIOM SG_ 2566841879 MinutesUTC_ISig_3 1500;
BA_REL_ "GenSigFirstTimeoutTime" BU_SG_REL_ ACM SG_ 2566841879 MinutesUTC_ISig_3 6000;
BA_REL_ "GenSigTimeoutTime" BU_SG_REL_ ACM SG_ 2566841879 MinutesUTC_ISig_3 1500;
BA_REL_ "GenSigFirstTimeoutTime" BU_SG_REL_ EMS SG_ 2566841879 MinutesUTC_ISig_3 6000;
BA_REL_ "GenSigTimeoutTime" BU_SG_REL_ EMS SG_ 2566841879 MinutesUTC_ISig_3 1500;
BA_REL_ "GenSigFirstTimeoutTime" BU_SG_REL_ EBS SG_ 2566841879 MinutesUTC_ISig_3 6000;
BA_REL_ "GenSigTimeoutTime" BU_SG_REL_ EBS SG_ 2566841879 MinutesUTC_ISig_3 1500;
BA_REL_ "GenSigFirstTimeoutTime" BU_SG_REL_ BBM SG_ 2566841879 MinutesUTC_ISig_3 6000;
BA_REL_ "GenSigTimeoutTime" BU_SG_REL_ BBM SG_ 2566841879 MinutesUTC_ISig_3 1500;
BA_REL_ "GenSigFirstTimeoutTime" BU_SG_REL_ BBM SG_ 2365484270 Driver2TimeRelatedStates_ISig_3 3000;
BA_REL_ "GenSigTimeoutTime" BU_SG_REL_ BBM SG_ 2365484270 Driver2TimeRelatedStates_ISig_3 300;
BA_REL_ "GenSigFirstTimeoutTime" BU_SG_REL_ CIOM SG_ 2365484270 Driver2TimeRelatedStates_ISig_3 3000;
BA_REL_ "GenSigTimeoutTime" BU_SG_REL_ CIOM SG_ 2365484270 Driver2TimeRelatedStates_ISig_3 300;
BA_REL_ "GenSigFirstTimeoutTime" BU_SG_REL_ HMIIOM SG_ 2365484270 Driver2TimeRelatedStates_ISig_3 3000;
BA_REL_ "GenSigTimeoutTime" BU_SG_REL_ HMIIOM SG_ 2365484270 Driver2TimeRelatedStates_ISig_3 300;
BA_REL_ "GenSigFirstTimeoutTime" BU_SG_REL_ HMIIOM SG_ 2365484270 VehicleMotion_ISig_3 3000;
BA_REL_ "GenSigTimeoutTime" BU_SG_REL_ HMIIOM SG_ 2365484270 VehicleMotion_ISig_3 300;
BA_REL_ "GenSigFirstTimeoutTime" BU_SG_REL_ CIOM SG_ 2365484270 VehicleMotion_ISig_3 3000;
BA_REL_ "GenSigTimeoutTime" BU_SG_REL_ CIOM SG_ 2365484270 VehicleMotion_ISig_3 300;
BA_REL_ "GenSigFirstTimeoutTime" BU_SG_REL_ BBM SG_ 2365484270 VehicleMotion_ISig_3 3000;
BA_REL_ "GenSigTimeoutTime" BU_SG_REL_ BBM SG_ 2365484270 VehicleMotion_ISig_3 300;
BA_REL_ "GenSigFirstTimeoutTime" BU_SG_REL_ CIOM SG_ 2365484270 TachographVehicleSpeed_ISig_3 3000;
BA_REL_ "GenSigTimeoutTime" BU_SG_REL_ CIOM SG_ 2365484270 TachographVehicleSpeed_ISig_3 300;
BA_REL_ "GenSigFirstTimeoutTime" BU_SG_REL_ VMCU SG_ 2365484270 TachographVehicleSpeed_ISig_3 3000;
BA_REL_ "GenSigTimeoutTime" BU_SG_REL_ VMCU SG_ 2365484270 TachographVehicleSpeed_ISig_3 300;
BA_REL_ "GenSigFirstTimeoutTime" BU_SG_REL_ BBM SG_ 2365484270 TachographVehicleSpeed_ISig_3 3000;
BA_REL_ "GenSigTimeoutTime" BU_SG_REL_ BBM SG_ 2365484270 TachographVehicleSpeed_ISig_3 300;
BA_REL_ "GenSigFirstTimeoutTime" BU_SG_REL_ HMIIOM SG_ 2365484270 TachographVehicleSpeed_ISig_3 3000;
BA_REL_ "GenSigTimeoutTime" BU_SG_REL_ HMIIOM SG_ 2365484270 TachographVehicleSpeed_ISig_3 120;
BA_REL_ "GenSigFirstTimeoutTime" BU_SG_REL_ BBM SG_ 2365484270 TachographPerformance_ISig_3 3000;
BA_REL_ "GenSigTimeoutTime" BU_SG_REL_ BBM SG_ 2365484270 TachographPerformance_ISig_3 300;
BA_REL_ "GenSigFirstTimeoutTime" BU_SG_REL_ CIOM SG_ 2365484270 TachographPerformance_ISig_3 3000;
BA_REL_ "GenSigTimeoutTime" BU_SG_REL_ CIOM SG_ 2365484270 TachographPerformance_ISig_3 300;
BA_REL_ "GenSigFirstTimeoutTime" BU_SG_REL_ HMIIOM SG_ 2365484270 TachographPerformance_ISig_3 3000;
BA_REL_ "GenSigTimeoutTime" BU_SG_REL_ HMIIOM SG_ 2365484270 TachographPerformance_ISig_3 300;
BA_REL_ "GenSigFirstTimeoutTime" BU_SG_REL_ VMCU SG_ 2365484270 TachographPerformance_ISig_3 3000;
BA_REL_ "GenSigTimeoutTime" BU_SG_REL_ VMCU SG_ 2365484270 TachographPerformance_ISig_3 300;
BA_REL_ "GenSigFirstTimeoutTime" BU_SG_REL_ BBM SG_ 2365484270 Driver1WorkingState_ISig_3 3000;
BA_REL_ "GenSigTimeoutTime" BU_SG_REL_ BBM SG_ 2365484270 Driver1WorkingState_ISig_3 300;
BA_REL_ "GenSigFirstTimeoutTime" BU_SG_REL_ HMIIOM SG_ 2365484270 Driver1WorkingState_ISig_3 3000;
BA_REL_ "GenSigTimeoutTime" BU_SG_REL_ HMIIOM SG_ 2365484270 Driver1WorkingState_ISig_3 300;
BA_REL_ "GenSigFirstTimeoutTime" BU_SG_REL_ CIOM SG_ 2365484270 Driver1WorkingState_ISig_3 3000;
BA_REL_ "GenSigTimeoutTime" BU_SG_REL_ CIOM SG_ 2365484270 Driver1WorkingState_ISig_3 300;
BA_REL_ "GenSigFirstTimeoutTime" BU_SG_REL_ CIOM SG_ 2365484270 Driver1TimeRelatedStates_ISig_3 3000;
BA_REL_ "GenSigTimeoutTime" BU_SG_REL_ CIOM SG_ 2365484270 Driver1TimeRelatedStates_ISig_3 300;
BA_REL_ "GenSigFirstTimeoutTime" BU_SG_REL_ BBM SG_ 2365484270 Driver1TimeRelatedStates_ISig_3 3000;
BA_REL_ "GenSigTimeoutTime" BU_SG_REL_ BBM SG_ 2365484270 Driver1TimeRelatedStates_ISig_3 300;
BA_REL_ "GenSigFirstTimeoutTime" BU_SG_REL_ HMIIOM SG_ 2365484270 Driver1TimeRelatedStates_ISig_3 3000;
BA_REL_ "GenSigTimeoutTime" BU_SG_REL_ HMIIOM SG_ 2365484270 Driver1TimeRelatedStates_ISig_3 300;
BA_REL_ "GenSigFirstTimeoutTime" BU_SG_REL_ CIOM SG_ 2365484270 DriverCardDriver2_ISig_3 3000;
BA_REL_ "GenSigTimeoutTime" BU_SG_REL_ CIOM SG_ 2365484270 DriverCardDriver2_ISig_3 300;
BA_REL_ "GenSigFirstTimeoutTime" BU_SG_REL_ BBM SG_ 2365484270 DriverCardDriver2_ISig_3 3000;
BA_REL_ "GenSigTimeoutTime" BU_SG_REL_ BBM SG_ 2365484270 DriverCardDriver2_ISig_3 300;
BA_REL_ "GenSigFirstTimeoutTime" BU_SG_REL_ HMIIOM SG_ 2365484270 DriverCardDriver2_ISig_3 3000;
BA_REL_ "GenSigTimeoutTime" BU_SG_REL_ HMIIOM SG_ 2365484270 DriverCardDriver2_ISig_3 300;
BA_REL_ "GenSigFirstTimeoutTime" BU_SG_REL_ VMCU SG_ 2365484270 TachographOutputShaftSpeed_ISig_ 3000;
BA_REL_ "GenSigTimeoutTime" BU_SG_REL_ VMCU SG_ 2365484270 TachographOutputShaftSpeed_ISig_ 300;
BA_REL_ "GenSigFirstTimeoutTime" BU_SG_REL_ BBM SG_ 2365484270 TachographOutputShaftSpeed_ISig_ 3000;
BA_REL_ "GenSigTimeoutTime" BU_SG_REL_ BBM SG_ 2365484270 TachographOutputShaftSpeed_ISig_ 300;
BA_REL_ "GenSigFirstTimeoutTime" BU_SG_REL_ CIOM SG_ 2365484270 HandlingInformation_ISig_3 3000;
BA_REL_ "GenSigTimeoutTime" BU_SG_REL_ CIOM SG_ 2365484270 HandlingInformation_ISig_3 300;
BA_REL_ "GenSigFirstTimeoutTime" BU_SG_REL_ VMCU SG_ 2365484270 HandlingInformation_ISig_3 3000;
BA_REL_ "GenSigTimeoutTime" BU_SG_REL_ VMCU SG_ 2365484270 HandlingInformation_ISig_3 300;
BA_REL_ "GenSigFirstTimeoutTime" BU_SG_REL_ HMIIOM SG_ 2365484270 HandlingInformation_ISig_3 3000;
BA_REL_ "GenSigTimeoutTime" BU_SG_REL_ HMIIOM SG_ 2365484270 HandlingInformation_ISig_3 300;
BA_REL_ "GenSigFirstTimeoutTime" BU_SG_REL_ BBM SG_ 2365484270 HandlingInformation_ISig_3 3000;
BA_REL_ "GenSigTimeoutTime" BU_SG_REL_ BBM SG_ 2365484270 HandlingInformation_ISig_3 300;
BA_REL_ "GenSigFirstTimeoutTime" BU_SG_REL_ CIOM SG_ 2365484270 DriverCardDriver1_ISig_3 3000;
BA_REL_ "GenSigTimeoutTime" BU_SG_REL_ CIOM SG_ 2365484270 DriverCardDriver1_ISig_3 300;
BA_REL_ "GenSigFirstTimeoutTime" BU_SG_REL_ VMCU SG_ 2365484270 DriverCardDriver1_ISig_3 3000;
BA_REL_ "GenSigTimeoutTime" BU_SG_REL_ VMCU SG_ 2365484270 DriverCardDriver1_ISig_3 300;
BA_REL_ "GenSigFirstTimeoutTime" BU_SG_REL_ HMIIOM SG_ 2365484270 DriverCardDriver1_ISig_3 3000;
BA_REL_ "GenSigTimeoutTime" BU_SG_REL_ HMIIOM SG_ 2365484270 DriverCardDriver1_ISig_3 300;
BA_REL_ "GenSigFirstTimeoutTime" BU_SG_REL_ BBM SG_ 2365484270 DriverCardDriver1_ISig_3 3000;
BA_REL_ "GenSigTimeoutTime" BU_SG_REL_ BBM SG_ 2365484270 DriverCardDriver1_ISig_3 300;
BA_REL_ "GenSigFirstTimeoutTime" BU_SG_REL_ DACU SG_ 2365484270 DriverCardDriver1_ISig_3 3000;
BA_REL_ "GenSigTimeoutTime" BU_SG_REL_ DACU SG_ 2365484270 DriverCardDriver1_ISig_3 120;
BA_REL_ "GenSigFirstTimeoutTime" BU_SG_REL_ HMIIOM SG_ 2365484270 SystemEvent_ISig_3 3000;
BA_REL_ "GenSigTimeoutTime" BU_SG_REL_ HMIIOM SG_ 2365484270 SystemEvent_ISig_3 300;
BA_REL_ "GenSigFirstTimeoutTime" BU_SG_REL_ BBM SG_ 2365484270 SystemEvent_ISig_3 3000;
BA_REL_ "GenSigTimeoutTime" BU_SG_REL_ BBM SG_ 2365484270 SystemEvent_ISig_3 300;
BA_REL_ "GenSigFirstTimeoutTime" BU_SG_REL_ VMCU SG_ 2365484270 SystemEvent_ISig_3 3000;
BA_REL_ "GenSigTimeoutTime" BU_SG_REL_ VMCU SG_ 2365484270 SystemEvent_ISig_3 300;
BA_REL_ "GenSigFirstTimeoutTime" BU_SG_REL_ CIOM SG_ 2365484270 SystemEvent_ISig_3 3000;
BA_REL_ "GenSigTimeoutTime" BU_SG_REL_ CIOM SG_ 2365484270 SystemEvent_ISig_3 300;
BA_REL_ "GenSigFirstTimeoutTime" BU_SG_REL_ CIOM SG_ 2365484270 VehicleOverspeed_ISig_3 3000;
BA_REL_ "GenSigTimeoutTime" BU_SG_REL_ CIOM SG_ 2365484270 VehicleOverspeed_ISig_3 300;
BA_REL_ "GenSigFirstTimeoutTime" BU_SG_REL_ BBM SG_ 2365484270 VehicleOverspeed_ISig_3 3000;
BA_REL_ "GenSigTimeoutTime" BU_SG_REL_ BBM SG_ 2365484270 VehicleOverspeed_ISig_3 300;
BA_REL_ "GenSigFirstTimeoutTime" BU_SG_REL_ HMIIOM SG_ 2365484270 VehicleOverspeed_ISig_3 3000;
BA_REL_ "GenSigTimeoutTime" BU_SG_REL_ HMIIOM SG_ 2365484270 VehicleOverspeed_ISig_3 300;
BA_REL_ "GenSigFirstTimeoutTime" BU_SG_REL_ CIOM SG_ 2365484270 Driver2WorkingState_ISig_3 3000;
BA_REL_ "GenSigTimeoutTime" BU_SG_REL_ CIOM SG_ 2365484270 Driver2WorkingState_ISig_3 300;
BA_REL_ "GenSigFirstTimeoutTime" BU_SG_REL_ BBM SG_ 2365484270 Driver2WorkingState_ISig_3 3000;
BA_REL_ "GenSigTimeoutTime" BU_SG_REL_ BBM SG_ 2365484270 Driver2WorkingState_ISig_3 300;
BA_REL_ "GenSigFirstTimeoutTime" BU_SG_REL_ HMIIOM SG_ 2365484270 Driver2WorkingState_ISig_3 3000;
BA_REL_ "GenSigTimeoutTime" BU_SG_REL_ HMIIOM SG_ 2365484270 Driver2WorkingState_ISig_3 300;
BA_REL_ "GenSigFirstTimeoutTime" BU_SG_REL_ TECU SG_ 2348876549 TransmissionMode4 3000;
BA_REL_ "GenSigTimeoutTime" BU_SG_REL_ TECU SG_ 2348876549 TransmissionMode4 300;
BA_REL_ "GenSigFirstTimeoutTime" BU_SG_REL_ TECU SG_ 2348876549 TransmissionRequestedGear 3000;
BA_REL_ "GenSigTimeoutTime" BU_SG_REL_ TECU SG_ 2348876549 TransmissionRequestedGear 300;
BA_REL_ "GenSigFirstTimeoutTime" BU_SG_REL_ TECU SG_ 2348876549 TransmShiftSelectorDisplayMode 3000;
BA_REL_ "GenSigTimeoutTime" BU_SG_REL_ TECU SG_ 2348876549 TransmShiftSelectorDisplayMode 300;
BA_REL_ "GenSigFirstTimeoutTime" BU_SG_REL_ TECU SG_ 2348876549 TransmissionMode3 3000;
BA_REL_ "GenSigTimeoutTime" BU_SG_REL_ TECU SG_ 2348876549 TransmissionMode3 300;
BA_REL_ "GenSigFirstTimeoutTime" BU_SG_REL_ HMIIOM SG_ 2499792656 DrivelineRetarderStat_ISig_3 3000;
BA_REL_ "GenSigTimeoutTime" BU_SG_REL_ HMIIOM SG_ 2499792656 DrivelineRetarderStat_ISig_3 900;
BA_REL_ "GenSigFirstTimeoutTime" BU_SG_REL_ EBS SG_ 2566840592 DrivelineRetarderRefTorque 65000;
BA_REL_ "GenSigTimeoutTime" BU_SG_REL_ EBS SG_ 2566840592 DrivelineRetarderRefTorque 30000;
BA_REL_ "GenSigFirstTimeoutTime" BU_SG_REL_ VMCU SG_ 2566840592 DrivelineRetarderRefTorque 65000;
BA_REL_ "GenSigTimeoutTime" BU_SG_REL_ VMCU SG_ 2566840592 DrivelineRetarderRefTorque 30000;
BA_REL_ "GenSigFirstTimeoutTime" BU_SG_REL_ DACU SG_ 2566840592 DrivelineRetarderRefTorque 65000;
BA_REL_ "GenSigTimeoutTime" BU_SG_REL_ DACU SG_ 2566840592 DrivelineRetarderRefTorque 30000;
BA_REL_ "GenSigFirstTimeoutTime" BU_SG_REL_ TECU SG_ 2566840592 DrivelineRetarderRefTorque 60000;
BA_REL_ "GenSigTimeoutTime" BU_SG_REL_ TECU SG_ 2566840592 DrivelineRetarderRefTorque 30000;
BA_REL_ "GenSigFirstTimeoutTime" BU_SG_REL_ EMS SG_ 2566840592 DrivelineRetarderRefTorque 65000;
BA_REL_ "GenSigTimeoutTime" BU_SG_REL_ EMS SG_ 2566840592 DrivelineRetarderRefTorque 30000;
BA_REL_ "GenSigFirstTimeoutTime" BU_SG_REL_ EMS SG_ 2566840592 DrivelineRetarderLocation 65000;
BA_REL_ "GenSigTimeoutTime" BU_SG_REL_ EMS SG_ 2566840592 DrivelineRetarderLocation 30000;
BA_REL_ "GenSigFirstTimeoutTime" BU_SG_REL_ DACU SG_ 2566840592 DrivelineRetarderLocation 65000;
BA_REL_ "GenSigTimeoutTime" BU_SG_REL_ DACU SG_ 2566840592 DrivelineRetarderLocation 30000;
BA_REL_ "GenSigFirstTimeoutTime" BU_SG_REL_ EBS SG_ 2566840592 DrivelineRetarderLocation 65000;
BA_REL_ "GenSigTimeoutTime" BU_SG_REL_ EBS SG_ 2566840592 DrivelineRetarderLocation 30000;
BA_REL_ "GenSigFirstTimeoutTime" BU_SG_REL_ EBS SG_ 2566840592 DrivelineRetarderType 65000;
BA_REL_ "GenSigTimeoutTime" BU_SG_REL_ EBS SG_ 2566840592 DrivelineRetarderType 30000;
BA_REL_ "GenSigFirstTimeoutTime" BU_SG_REL_ TECU SG_ 2566840591 EngRetConf_RetCtrlMethod 65000;
BA_REL_ "GenSigTimeoutTime" BU_SG_REL_ TECU SG_ 2566840591 EngRetConf_RetCtrlMethod 30000;
BA_REL_ "GenSigFirstTimeoutTime" BU_SG_REL_ TECU SG_ 2566840591 EngRetConf_RetSpeedAtP4 65000;
BA_REL_ "GenSigTimeoutTime" BU_SG_REL_ TECU SG_ 2566840591 EngRetConf_RetSpeedAtP4 30000;
BA_REL_ "GenSigFirstTimeoutTime" BU_SG_REL_ HMIIOM SG_ 2566840591 EngRetConf_MaxRetSpeedP2 65000;
BA_REL_ "GenSigTimeoutTime" BU_SG_REL_ HMIIOM SG_ 2566840591 EngRetConf_MaxRetSpeedP2 30000;
BA_REL_ "GenSigFirstTimeoutTime" BU_SG_REL_ TECU SG_ 2566840591 EngRetConf_MaxRetSpeedP2 65000;
BA_REL_ "GenSigTimeoutTime" BU_SG_REL_ TECU SG_ 2566840591 EngRetConf_MaxRetSpeedP2 30000;
BA_REL_ "GenSigFirstTimeoutTime" BU_SG_REL_ TECU SG_ 2566840591 EngRetConf_PerTrqAtP3 65000;
BA_REL_ "GenSigTimeoutTime" BU_SG_REL_ TECU SG_ 2566840591 EngRetConf_PerTrqAtP3 30000;
BA_REL_ "GenSigFirstTimeoutTime" BU_SG_REL_ TECU SG_ 2566840591 EngRetConf_RetSpeedAtP5 65000;
BA_REL_ "GenSigTimeoutTime" BU_SG_REL_ TECU SG_ 2566840591 EngRetConf_RetSpeedAtP5 30000;
BA_REL_ "GenSigFirstTimeoutTime" BU_SG_REL_ TECU SG_ 2566840591 EngRetConf_speedAtIdleP1 65000;
BA_REL_ "GenSigTimeoutTime" BU_SG_REL_ TECU SG_ 2566840591 EngRetConf_speedAtIdleP1 30000;
BA_REL_ "GenSigFirstTimeoutTime" BU_SG_REL_ TECU SG_ 2566840591 EngRetConf_PerTrqAtP4 65000;
BA_REL_ "GenSigTimeoutTime" BU_SG_REL_ TECU SG_ 2566840591 EngRetConf_PerTrqAtP4 30000;
BA_REL_ "GenSigFirstTimeoutTime" BU_SG_REL_ VMCU SG_ 2566840591 ReferenceEngineRetarderTorque 65000;
BA_REL_ "GenSigTimeoutTime" BU_SG_REL_ VMCU SG_ 2566840591 ReferenceEngineRetarderTorque 30000;
BA_REL_ "GenSigFirstTimeoutTime" BU_SG_REL_ EBS SG_ 2566840591 ReferenceEngineRetarderTorque 65000;
BA_REL_ "GenSigTimeoutTime" BU_SG_REL_ EBS SG_ 2566840591 ReferenceEngineRetarderTorque 30000;
BA_REL_ "GenSigFirstTimeoutTime" BU_SG_REL_ VGGSECUSystem SG_ 2566840591 ReferenceEngineRetarderTorque 65000;
BA_REL_ "GenSigTimeoutTime" BU_SG_REL_ VGGSECUSystem SG_ 2566840591 ReferenceEngineRetarderTorque 30000;
BA_REL_ "GenSigFirstTimeoutTime" BU_SG_REL_ DACU SG_ 2566840591 ReferenceEngineRetarderTorque 65000;
BA_REL_ "GenSigTimeoutTime" BU_SG_REL_ DACU SG_ 2566840591 ReferenceEngineRetarderTorque 30000;
BA_REL_ "GenSigFirstTimeoutTime" BU_SG_REL_ RECU_Virt SG_ 2566840591 ReferenceEngineRetarderTorque 65000;
BA_REL_ "GenSigTimeoutTime" BU_SG_REL_ RECU_Virt SG_ 2566840591 ReferenceEngineRetarderTorque 30000;
BA_REL_ "GenSigFirstTimeoutTime" BU_SG_REL_ TECU SG_ 2566840591 ReferenceEngineRetarderTorque 65000;
BA_REL_ "GenSigTimeoutTime" BU_SG_REL_ TECU SG_ 2566840591 ReferenceEngineRetarderTorque 30000;
BA_REL_ "GenSigFirstTimeoutTime" BU_SG_REL_ TECU SG_ 2566840591 EngRetConf_PerTrqAtIdleP1 65000;
BA_REL_ "GenSigTimeoutTime" BU_SG_REL_ TECU SG_ 2566840591 EngRetConf_PerTrqAtIdleP1 30000;
BA_REL_ "GenSigFirstTimeoutTime" BU_SG_REL_ TECU SG_ 2566840591 EngRetConf_RetSpeedAtP3 65000;
BA_REL_ "GenSigTimeoutTime" BU_SG_REL_ TECU SG_ 2566840591 EngRetConf_RetSpeedAtP3 30000;
BA_REL_ "GenSigFirstTimeoutTime" BU_SG_REL_ TECU SG_ 2566840591 EngRetConf_PerTrqAtMaxSpeedP2 65000;
BA_REL_ "GenSigTimeoutTime" BU_SG_REL_ TECU SG_ 2566840591 EngRetConf_PerTrqAtMaxSpeedP2 30000;
BA_REL_ "GenSigFirstTimeoutTime" BU_SG_REL_ TECU SG_ 2566840591 EngRetConf_PerTrqAtP5 65000;
BA_REL_ "GenSigTimeoutTime" BU_SG_REL_ TECU SG_ 2566840591 EngRetConf_PerTrqAtP5 30000;
BA_REL_ "GenSigFirstTimeoutTime" BU_SG_REL_ HMIIOM SG_ 2566899694 TwoWeeksTotalOdometer 65535;
BA_REL_ "GenSigTimeoutTime" BU_SG_REL_ HMIIOM SG_ 2566899694 TwoWeeksTotalOdometer 65535;
BA_REL_ "GenSigFirstTimeoutTime" BU_SG_REL_ HMIIOM SG_ 2566899694 WeeklyTotalOdometer 65535;
BA_REL_ "GenSigTimeoutTime" BU_SG_REL_ HMIIOM SG_ 2566899694 WeeklyTotalOdometer 65535;
BA_REL_ "GenSigFirstTimeoutTime" BU_SG_REL_ HMIIOM SG_ 2566899694 DailyRestingTimeShift1_ISig_3 65535;
BA_REL_ "GenSigTimeoutTime" BU_SG_REL_ HMIIOM SG_ 2566899694 DailyRestingTimeShift1_ISig_3 65535;
BA_REL_ "GenSigFirstTimeoutTime" BU_SG_REL_ HMIIOM SG_ 2566899694 RestingPeriodFlagShift2_ISig_3 65535;
BA_REL_ "GenSigTimeoutTime" BU_SG_REL_ HMIIOM SG_ 2566899694 RestingPeriodFlagShift2_ISig_3 65535;
BA_REL_ "GenSigFirstTimeoutTime" BU_SG_REL_ HMIIOM SG_ 2566899694 AvailableCounter 65535;
BA_REL_ "GenSigTimeoutTime" BU_SG_REL_ HMIIOM SG_ 2566899694 AvailableCounter 65535;
BA_REL_ "GenSigFirstTimeoutTime" BU_SG_REL_ HMIIOM SG_ 2566899694 DailyDrivingTimeShift4_ISig_3 65535;
BA_REL_ "GenSigTimeoutTime" BU_SG_REL_ HMIIOM SG_ 2566899694 DailyDrivingTimeShift4_ISig_3 65535;
BA_REL_ "GenSigFirstTimeoutTime" BU_SG_REL_ HMIIOM SG_ 2566899694 DailyDrivingPeriod_ISig_3 65535;
BA_REL_ "GenSigTimeoutTime" BU_SG_REL_ HMIIOM SG_ 2566899694 DailyDrivingPeriod_ISig_3 65535;
BA_REL_ "GenSigFirstTimeoutTime" BU_SG_REL_ HMIIOM SG_ 2566899694 DailyRestingTimeShift7_ISig_3 65535;
BA_REL_ "GenSigTimeoutTime" BU_SG_REL_ HMIIOM SG_ 2566899694 DailyRestingTimeShift7_ISig_3 65535;
BA_REL_ "GenSigFirstTimeoutTime" BU_SG_REL_ HMIIOM SG_ 2566899694 UnknownPeriodShift1_ISig_3 65535;
BA_REL_ "GenSigTimeoutTime" BU_SG_REL_ HMIIOM SG_ 2566899694 UnknownPeriodShift1_ISig_3 65535;
BA_REL_ "GenSigFirstTimeoutTime" BU_SG_REL_ HMIIOM SG_ 2566899694 RestingPeriodFlagShift1_ISig_3 65535;
BA_REL_ "GenSigTimeoutTime" BU_SG_REL_ HMIIOM SG_ 2566899694 RestingPeriodFlagShift1_ISig_3 65535;
BA_REL_ "GenSigFirstTimeoutTime" BU_SG_REL_ HMIIOM SG_ 2566899694 DrivingCounter 65535;
BA_REL_ "GenSigTimeoutTime" BU_SG_REL_ HMIIOM SG_ 2566899694 DrivingCounter 65535;
BA_REL_ "GenSigFirstTimeoutTime" BU_SG_REL_ HMIIOM SG_ 2566899694 DailyDrivingTimeShift3_ISig_3 65535;
BA_REL_ "GenSigTimeoutTime" BU_SG_REL_ HMIIOM SG_ 2566899694 DailyDrivingTimeShift3_ISig_3 65535;
BA_REL_ "GenSigFirstTimeoutTime" BU_SG_REL_ HMIIOM SG_ 2566899694 DailyRestingTimeShift2_ISig_3 65535;
BA_REL_ "GenSigTimeoutTime" BU_SG_REL_ HMIIOM SG_ 2566899694 DailyRestingTimeShift2_ISig_3 65535;
BA_REL_ "GenSigFirstTimeoutTime" BU_SG_REL_ HMIIOM SG_ 2566899694 DailyRestingTimeShift3_ISig_3 65535;
BA_REL_ "GenSigTimeoutTime" BU_SG_REL_ HMIIOM SG_ 2566899694 DailyRestingTimeShift3_ISig_3 65535;
BA_REL_ "GenSigFirstTimeoutTime" BU_SG_REL_ HMIIOM SG_ 2566899694 UnknownPeriodShift2_ISig_3 65535;
BA_REL_ "GenSigTimeoutTime" BU_SG_REL_ HMIIOM SG_ 2566899694 UnknownPeriodShift2_ISig_3 65535;
BA_REL_ "GenSigFirstTimeoutTime" BU_SG_REL_ HMIIOM SG_ 2566899694 RestingPeriodFlag_ISig_3 65535;
BA_REL_ "GenSigTimeoutTime" BU_SG_REL_ HMIIOM SG_ 2566899694 RestingPeriodFlag_ISig_3 65535;
BA_REL_ "GenSigFirstTimeoutTime" BU_SG_REL_ HMIIOM SG_ 2566899694 TwoWeekTotalDrvingTime_ISig_3 65535;
BA_REL_ "GenSigTimeoutTime" BU_SG_REL_ HMIIOM SG_ 2566899694 TwoWeekTotalDrvingTime_ISig_3 65535;
BA_REL_ "GenSigFirstTimeoutTime" BU_SG_REL_ HMIIOM SG_ 2566899694 UnknownPeriodShift4_ISig_3 65535;
BA_REL_ "GenSigTimeoutTime" BU_SG_REL_ HMIIOM SG_ 2566899694 UnknownPeriodShift4_ISig_3 65535;
BA_REL_ "GenSigFirstTimeoutTime" BU_SG_REL_ HMIIOM SG_ 2566899694 DailyDrivingTimeShift2_ISig_3 65535;
BA_REL_ "GenSigTimeoutTime" BU_SG_REL_ HMIIOM SG_ 2566899694 DailyDrivingTimeShift2_ISig_3 65535;
BA_REL_ "GenSigFirstTimeoutTime" BU_SG_REL_ HMIIOM SG_ 2566899694 RestingPeriodFlagShift6_ISig_3 65535;
BA_REL_ "GenSigTimeoutTime" BU_SG_REL_ HMIIOM SG_ 2566899694 RestingPeriodFlagShift6_ISig_3 65535;
BA_REL_ "GenSigFirstTimeoutTime" BU_SG_REL_ HMIIOM SG_ 2566899694 DailyRestingTimeShift4_ISig_3 65535;
BA_REL_ "GenSigTimeoutTime" BU_SG_REL_ HMIIOM SG_ 2566899694 DailyRestingTimeShift4_ISig_3 65535;
BA_REL_ "GenSigFirstTimeoutTime" BU_SG_REL_ HMIIOM SG_ 2566899694 RestingPeriodFlagShift5_ISig_3 65535;
BA_REL_ "GenSigTimeoutTime" BU_SG_REL_ HMIIOM SG_ 2566899694 RestingPeriodFlagShift5_ISig_3 65535;
BA_REL_ "GenSigFirstTimeoutTime" BU_SG_REL_ HMIIOM SG_ 2566899694 RestingPeriodFlagShift3_ISig_3 65535;
BA_REL_ "GenSigTimeoutTime" BU_SG_REL_ HMIIOM SG_ 2566899694 RestingPeriodFlagShift3_ISig_3 65535;
BA_REL_ "GenSigFirstTimeoutTime" BU_SG_REL_ HMIIOM SG_ 2566899694 DailyDrivingTimeShift5_ISig_3 65535;
BA_REL_ "GenSigTimeoutTime" BU_SG_REL_ HMIIOM SG_ 2566899694 DailyDrivingTimeShift5_ISig_3 65535;
BA_REL_ "GenSigFirstTimeoutTime" BU_SG_REL_ HMIIOM SG_ 2566899694 DailyRestingTimeShift6_ISig_3 65535;
BA_REL_ "GenSigTimeoutTime" BU_SG_REL_ HMIIOM SG_ 2566899694 DailyRestingTimeShift6_ISig_3 65535;
BA_REL_ "GenSigFirstTimeoutTime" BU_SG_REL_ HMIIOM SG_ 2566899694 WeeklyTotalDrivingTime_ISig_3 65535;
BA_REL_ "GenSigTimeoutTime" BU_SG_REL_ HMIIOM SG_ 2566899694 WeeklyTotalDrivingTime_ISig_3 65535;
BA_REL_ "GenSigFirstTimeoutTime" BU_SG_REL_ HMIIOM SG_ 2566899694 UnknownPeriodShift7_ISig_3 65535;
BA_REL_ "GenSigTimeoutTime" BU_SG_REL_ HMIIOM SG_ 2566899694 UnknownPeriodShift7_ISig_3 65535;
BA_REL_ "GenSigFirstTimeoutTime" BU_SG_REL_ HMIIOM SG_ 2566899694 DailyOdometer 65535;
BA_REL_ "GenSigTimeoutTime" BU_SG_REL_ HMIIOM SG_ 2566899694 DailyOdometer 65535;
BA_REL_ "GenSigFirstTimeoutTime" BU_SG_REL_ HMIIOM SG_ 2566899694 UnknownPeriodShift6_ISig_3 65535;
BA_REL_ "GenSigTimeoutTime" BU_SG_REL_ HMIIOM SG_ 2566899694 UnknownPeriodShift6_ISig_3 65535;
BA_REL_ "GenSigFirstTimeoutTime" BU_SG_REL_ HMIIOM SG_ 2566899694 DailyRestingTimeShift5_ISig_3 65535;
BA_REL_ "GenSigTimeoutTime" BU_SG_REL_ HMIIOM SG_ 2566899694 DailyRestingTimeShift5_ISig_3 65535;
BA_REL_ "GenSigFirstTimeoutTime" BU_SG_REL_ HMIIOM SG_ 2566899694 DailyDrivingTimeShift1_ISig_3 65535;
BA_REL_ "GenSigTimeoutTime" BU_SG_REL_ HMIIOM SG_ 2566899694 DailyDrivingTimeShift1_ISig_3 65535;
BA_REL_ "GenSigFirstTimeoutTime" BU_SG_REL_ HMIIOM SG_ 2566899694 UnknownPeriodShift3_ISig_3 65535;
BA_REL_ "GenSigTimeoutTime" BU_SG_REL_ HMIIOM SG_ 2566899694 UnknownPeriodShift3_ISig_3 65535;
BA_REL_ "GenSigFirstTimeoutTime" BU_SG_REL_ HMIIOM SG_ 2566899694 RestingPeriodFlagShift4_ISig_3 65535;
BA_REL_ "GenSigTimeoutTime" BU_SG_REL_ HMIIOM SG_ 2566899694 RestingPeriodFlagShift4_ISig_3 65535;
BA_REL_ "GenSigFirstTimeoutTime" BU_SG_REL_ HMIIOM SG_ 2566899694 DailyDrivingTimeShift6_ISig_3 65535;
BA_REL_ "GenSigTimeoutTime" BU_SG_REL_ HMIIOM SG_ 2566899694 DailyDrivingTimeShift6_ISig_3 65535;
BA_REL_ "GenSigFirstTimeoutTime" BU_SG_REL_ HMIIOM SG_ 2566899694 UnknownPeriodShift5_ISig_3 65535;
BA_REL_ "GenSigTimeoutTime" BU_SG_REL_ HMIIOM SG_ 2566899694 UnknownPeriodShift5_ISig_3 65535;
BA_REL_ "GenSigFirstTimeoutTime" BU_SG_REL_ HMIIOM SG_ 2566899694 WorkCounter 65535;
BA_REL_ "GenSigTimeoutTime" BU_SG_REL_ HMIIOM SG_ 2566899694 WorkCounter 65535;
BA_REL_ "GenSigFirstTimeoutTime" BU_SG_REL_ VMCU SG_ 2566898926 Drvr1CumuBreakTime_Tacho 65000;
BA_REL_ "GenSigTimeoutTime" BU_SG_REL_ VMCU SG_ 2566898926 Drvr1CumuBreakTime_Tacho 60000;
BA_REL_ "GenSigFirstTimeoutTime" BU_SG_REL_ VMCU SG_ 2566898926 Drvr1CurDurSelectActy_Tacho 65000;
BA_REL_ "GenSigTimeoutTime" BU_SG_REL_ VMCU SG_ 2566898926 Drvr1CurDurSelectActy_Tacho 60000;
BA_REL_ "GenSigFirstTimeoutTime" BU_SG_REL_ VMCU SG_ 2566898926 Driver1CardUnload_Tacho 65000;
BA_REL_ "GenSigTimeoutTime" BU_SG_REL_ VMCU SG_ 2566898926 Driver1CardUnload_Tacho 60000;
BA_REL_ "GenSigFirstTimeoutTime" BU_SG_REL_ VMCU SG_ 2566898926 EndofLifeDriver1Card_Tacho 65000;
BA_REL_ "GenSigTimeoutTime" BU_SG_REL_ VMCU SG_ 2566898926 EndofLifeDriver1Card_Tacho 60000;
BA_REL_ "GenSigFirstTimeoutTime" BU_SG_REL_ VMCU SG_ 2566898926 DrawerState_Tacho 65000;
BA_REL_ "GenSigTimeoutTime" BU_SG_REL_ VMCU SG_ 2566898926 DrawerState_Tacho 60000;
BA_REL_ "GenSigFirstTimeoutTime" BU_SG_REL_ VMCU SG_ 2566898926 Drvr1ContinDrivingTime_Tacho 65000;
BA_REL_ "GenSigTimeoutTime" BU_SG_REL_ VMCU SG_ 2566898926 Drvr1ContinDrivingTime_Tacho 60000;
BA_REL_ "GenSigFirstTimeoutTime" BU_SG_REL_ VMCU SG_ 2566898670 NextCalibrationDateDay 65535;
BA_REL_ "GenSigTimeoutTime" BU_SG_REL_ VMCU SG_ 2566898670 NextCalibrationDateDay 65535;
BA_REL_ "GenSigFirstTimeoutTime" BU_SG_REL_ VMCU SG_ 2566898670 WVehicleCharacteristicFactor 65535;
BA_REL_ "GenSigTimeoutTime" BU_SG_REL_ VMCU SG_ 2566898670 WVehicleCharacteristicFactor 65535;
BA_REL_ "GenSigFirstTimeoutTime" BU_SG_REL_ VMCU SG_ 2566898670 NextCalibrationDateMonth 65535;
BA_REL_ "GenSigTimeoutTime" BU_SG_REL_ VMCU SG_ 2566898670 NextCalibrationDateMonth 65535;
BA_REL_ "GenSigFirstTimeoutTime" BU_SG_REL_ VMCU SG_ 2566898670 NextCalibrationDateYear 65535;
BA_REL_ "GenSigTimeoutTime" BU_SG_REL_ VMCU SG_ 2566898670 NextCalibrationDateYear 65535;
BA_REL_ "GenSigFirstTimeoutTime" BU_SG_REL_ TECU SG_ 2566759457 Pto2EnableSwitch 3000;
BA_REL_ "GenSigTimeoutTime" BU_SG_REL_ TECU SG_ 2566759457 Pto2EnableSwitch 600;
BA_REL_ "GenSigFirstTimeoutTime" BU_SG_REL_ TECU SG_ 2566759457 Pto1EnableSwitch 3000;
BA_REL_ "GenSigTimeoutTime" BU_SG_REL_ TECU SG_ 2566759457 Pto1EnableSwitch 600;
BA_REL_ "GenSigFirstTimeoutTime" BU_SG_REL_ VMCU SG_ 2566759427 Pto2EngagementConsent 3000;
BA_REL_ "GenSigTimeoutTime" BU_SG_REL_ VMCU SG_ 2566759427 Pto2EngagementConsent 600;
BA_REL_ "GenSigFirstTimeoutTime" BU_SG_REL_ VMCU SG_ 2566759427 Pto1EngagementConsent 3000;
BA_REL_ "GenSigTimeoutTime" BU_SG_REL_ VMCU SG_ 2566759427 Pto1EngagementConsent 600;
BA_REL_ "GenSigFirstTimeoutTime" BU_SG_REL_ CIOM SG_ 2566844928 InstantaneousFuelEconomy_ISig_3 3000;
BA_REL_ "GenSigTimeoutTime" BU_SG_REL_ CIOM SG_ 2566844928 InstantaneousFuelEconomy_ISig_3 600;
BA_REL_ "GenSigFirstTimeoutTime" BU_SG_REL_ HMIIOM SG_ 2566844928 InstantaneousFuelEconomy_ISig_3 3000;
BA_REL_ "GenSigTimeoutTime" BU_SG_REL_ HMIIOM SG_ 2566844928 InstantaneousFuelEconomy_ISig_3 600;
BA_REL_ "GenSigFirstTimeoutTime" BU_SG_REL_ BBM SG_ 2566844928 EngineFuelRate_ISig_3 3000;
BA_REL_ "GenSigTimeoutTime" BU_SG_REL_ BBM SG_ 2566844928 EngineFuelRate_ISig_3 600;
BA_REL_ "GenSigFirstTimeoutTime" BU_SG_REL_ VMCU SG_ 2566844928 EngineFuelRate_ISig_3 3000;
BA_REL_ "GenSigTimeoutTime" BU_SG_REL_ VMCU SG_ 2566844928 EngineFuelRate_ISig_3 600;
BA_REL_ "GenSigFirstTimeoutTime" BU_SG_REL_ HMIIOM SG_ 2566844928 EngineFuelRate_ISig_3 3000;
BA_REL_ "GenSigTimeoutTime" BU_SG_REL_ HMIIOM SG_ 2566844928 EngineFuelRate_ISig_3 600;
BA_REL_ "GenSigFirstTimeoutTime" BU_SG_REL_ CIOM SG_ 2566844928 EngineFuelRate_ISig_3 3000;
BA_REL_ "GenSigTimeoutTime" BU_SG_REL_ CIOM SG_ 2566844928 EngineFuelRate_ISig_3 600;
BA_REL_ "GenSigFirstTimeoutTime" BU_SG_REL_ VGGSECUSystem SG_ 2566825472 EngineTurbo1BoostPressure 12000;
BA_REL_ "GenSigTimeoutTime" BU_SG_REL_ VGGSECUSystem SG_ 2566825472 EngineTurbo1BoostPressure 3000;
BA_REL_ "GenSigFirstTimeoutTime" BU_SG_REL_ HMIIOM SG_ 2566825472 EngineTurbo1BoostPressure 12000;
BA_REL_ "GenSigTimeoutTime" BU_SG_REL_ HMIIOM SG_ 2566825472 EngineTurbo1BoostPressure 3000;
BA_REL_ "GenSigFirstTimeoutTime" BU_SG_REL_ ACM SG_ 2566825472 EngineTurbo1BoostPressure 12000;
BA_REL_ "GenSigTimeoutTime" BU_SG_REL_ ACM SG_ 2566825472 EngineTurbo1BoostPressure 3000;
BA_REL_ "GenSigFirstTimeoutTime" BU_SG_REL_ VGGSECUSystem SG_ 2566845952 EngIntakeManifold1Temp 12000;
BA_REL_ "GenSigTimeoutTime" BU_SG_REL_ VGGSECUSystem SG_ 2566845952 EngIntakeManifold1Temp 3000;
BA_REL_ "GenSigFirstTimeoutTime" BU_SG_REL_ VMCU SG_ 2298372875 FrontAxleRightWheelSpeed_ISig_3 3000;
BA_REL_ "GenSigTimeoutTime" BU_SG_REL_ VMCU SG_ 2298372875 FrontAxleRightWheelSpeed_ISig_3 120;
BA_REL_ "GenSigFirstTimeoutTime" BU_SG_REL_ BBM SG_ 2298372875 FrontAxleRightWheelSpeed_ISig_3 3000;
BA_REL_ "GenSigTimeoutTime" BU_SG_REL_ BBM SG_ 2298372875 FrontAxleRightWheelSpeed_ISig_3 120;
BA_REL_ "GenSigFirstTimeoutTime" BU_SG_REL_ DACU SG_ 2298372875 FrontAxleRightWheelSpeed_ISig_3 3000;
BA_REL_ "GenSigTimeoutTime" BU_SG_REL_ DACU SG_ 2298372875 FrontAxleRightWheelSpeed_ISig_3 120;
BA_REL_ "GenSigFirstTimeoutTime" BU_SG_REL_ VGGSECUSystem SG_ 2298372875 FrontAxleRightWheelSpeed_ISig_3 3000;
BA_REL_ "GenSigTimeoutTime" BU_SG_REL_ VGGSECUSystem SG_ 2298372875 FrontAxleRightWheelSpeed_ISig_3 120;
BA_REL_ "GenSigFirstTimeoutTime" BU_SG_REL_ TECU SG_ 2298372875 FrontAxleRightWheelSpeed_ISig_3 3000;
BA_REL_ "GenSigTimeoutTime" BU_SG_REL_ TECU SG_ 2298372875 FrontAxleRightWheelSpeed_ISig_3 120;
BA_REL_ "GenSigFirstTimeoutTime" BU_SG_REL_ HMIIOM SG_ 2298372875 FrontAxleRightWheelSpeed_ISig_3 3000;
BA_REL_ "GenSigTimeoutTime" BU_SG_REL_ HMIIOM SG_ 2298372875 FrontAxleRightWheelSpeed_ISig_3 120;
BA_REL_ "GenSigFirstTimeoutTime" BU_SG_REL_ BBM SG_ 2298372875 RearAxleLeftWheelSpeed_ISig_3 3000;
BA_REL_ "GenSigTimeoutTime" BU_SG_REL_ BBM SG_ 2298372875 RearAxleLeftWheelSpeed_ISig_3 120;
BA_REL_ "GenSigFirstTimeoutTime" BU_SG_REL_ VMCU SG_ 2298372875 RearAxleLeftWheelSpeed_ISig_3 3000;
BA_REL_ "GenSigTimeoutTime" BU_SG_REL_ VMCU SG_ 2298372875 RearAxleLeftWheelSpeed_ISig_3 120;
BA_REL_ "GenSigFirstTimeoutTime" BU_SG_REL_ VGGSECUSystem SG_ 2298372875 RearAxleLeftWheelSpeed_ISig_3 3000;
BA_REL_ "GenSigTimeoutTime" BU_SG_REL_ VGGSECUSystem SG_ 2298372875 RearAxleLeftWheelSpeed_ISig_3 120;
BA_REL_ "GenSigFirstTimeoutTime" BU_SG_REL_ TECU SG_ 2298372875 RearAxleLeftWheelSpeed_ISig_3 3000;
BA_REL_ "GenSigTimeoutTime" BU_SG_REL_ TECU SG_ 2298372875 RearAxleLeftWheelSpeed_ISig_3 120;
BA_REL_ "GenSigFirstTimeoutTime" BU_SG_REL_ DACU SG_ 2298372875 RearAxleLeftWheelSpeed_ISig_3 3000;
BA_REL_ "GenSigTimeoutTime" BU_SG_REL_ DACU SG_ 2298372875 RearAxleLeftWheelSpeed_ISig_3 120;
BA_REL_ "GenSigFirstTimeoutTime" BU_SG_REL_ BBM SG_ 2298372875 RearAxleRightWheelSpeed_ISig_3 3000;
BA_REL_ "GenSigTimeoutTime" BU_SG_REL_ BBM SG_ 2298372875 RearAxleRightWheelSpeed_ISig_3 120;
BA_REL_ "GenSigFirstTimeoutTime" BU_SG_REL_ VMCU SG_ 2298372875 RearAxleRightWheelSpeed_ISig_3 3000;
BA_REL_ "GenSigTimeoutTime" BU_SG_REL_ VMCU SG_ 2298372875 RearAxleRightWheelSpeed_ISig_3 120;
BA_REL_ "GenSigFirstTimeoutTime" BU_SG_REL_ TECU SG_ 2298372875 RearAxleRightWheelSpeed_ISig_3 3000;
BA_REL_ "GenSigTimeoutTime" BU_SG_REL_ TECU SG_ 2298372875 RearAxleRightWheelSpeed_ISig_3 120;
BA_REL_ "GenSigFirstTimeoutTime" BU_SG_REL_ DACU SG_ 2298372875 RearAxleRightWheelSpeed_ISig_3 3000;
BA_REL_ "GenSigTimeoutTime" BU_SG_REL_ DACU SG_ 2298372875 RearAxleRightWheelSpeed_ISig_3 120;
BA_REL_ "GenSigFirstTimeoutTime" BU_SG_REL_ VGGSECUSystem SG_ 2298372875 RearAxleRightWheelSpeed_ISig_3 3000;
BA_REL_ "GenSigTimeoutTime" BU_SG_REL_ VGGSECUSystem SG_ 2298372875 RearAxleRightWheelSpeed_ISig_3 120;
BA_REL_ "GenSigFirstTimeoutTime" BU_SG_REL_ TECU SG_ 2298372875 FrontAxleLeftWheelSpeed_ISig_3 3000;
BA_REL_ "GenSigTimeoutTime" BU_SG_REL_ TECU SG_ 2298372875 FrontAxleLeftWheelSpeed_ISig_3 120;
BA_REL_ "GenSigFirstTimeoutTime" BU_SG_REL_ HMIIOM SG_ 2298372875 FrontAxleLeftWheelSpeed_ISig_3 3000;
BA_REL_ "GenSigTimeoutTime" BU_SG_REL_ HMIIOM SG_ 2298372875 FrontAxleLeftWheelSpeed_ISig_3 120;
BA_REL_ "GenSigFirstTimeoutTime" BU_SG_REL_ DACU SG_ 2298372875 FrontAxleLeftWheelSpeed_ISig_3 3000;
BA_REL_ "GenSigTimeoutTime" BU_SG_REL_ DACU SG_ 2298372875 FrontAxleLeftWheelSpeed_ISig_3 120;
BA_REL_ "GenSigFirstTimeoutTime" BU_SG_REL_ BBM SG_ 2298372875 FrontAxleLeftWheelSpeed_ISig_3 3000;
BA_REL_ "GenSigTimeoutTime" BU_SG_REL_ BBM SG_ 2298372875 FrontAxleLeftWheelSpeed_ISig_3 120;
BA_REL_ "GenSigFirstTimeoutTime" BU_SG_REL_ VMCU SG_ 2298372875 FrontAxleLeftWheelSpeed_ISig_3 3000;
BA_REL_ "GenSigTimeoutTime" BU_SG_REL_ VMCU SG_ 2298372875 FrontAxleLeftWheelSpeed_ISig_3 120;
BA_REL_ "GenSigFirstTimeoutTime" BU_SG_REL_ VGGSECUSystem SG_ 2298372875 FrontAxleLeftWheelSpeed_ISig_3 3000;
BA_REL_ "GenSigTimeoutTime" BU_SG_REL_ VGGSECUSystem SG_ 2298372875 FrontAxleLeftWheelSpeed_ISig_3 120;
BA_REL_ "GenSigFirstTimeoutTime" BU_SG_REL_ HMIIOM SG_ 2566719744 HighResEngineTotalFuelUsed_ISig_ 24000;
BA_REL_ "GenSigTimeoutTime" BU_SG_REL_ HMIIOM SG_ 2566719744 HighResEngineTotalFuelUsed_ISig_ 6000;
BA_REL_ "GenSigFirstTimeoutTime" BU_SG_REL_ BBM SG_ 2566719744 HighResEngineTotalFuelUsed_ISig_ 24000;
BA_REL_ "GenSigTimeoutTime" BU_SG_REL_ BBM SG_ 2566719744 HighResEngineTotalFuelUsed_ISig_ 6000;
BA_REL_ "GenSigFirstTimeoutTime" BU_SG_REL_ CIOM SG_ 2566719744 HighResEngineTotalFuelUsed_ISig_ 24000;
BA_REL_ "GenSigTimeoutTime" BU_SG_REL_ CIOM SG_ 2566719744 HighResEngineTotalFuelUsed_ISig_ 6000;
BA_REL_ "GenSigFirstTimeoutTime" BU_SG_REL_ HMIIOM SG_ 2566841600 EngineRevolutions_ISig_3 65000;
BA_REL_ "GenSigTimeoutTime" BU_SG_REL_ HMIIOM SG_ 2566841600 EngineRevolutions_ISig_3 30000;
BA_REL_ "GenSigFirstTimeoutTime" BU_SG_REL_ EBS SG_ 2499788567 AutoRearAxleDiffLockActvn_rqst 3000;
BA_REL_ "GenSigTimeoutTime" BU_SG_REL_ EBS SG_ 2499788567 AutoRearAxleDiffLockActvn_rqst 450;
BA_REL_ "GenSigFirstTimeoutTime" BU_SG_REL_ EBS SG_ 2499788567 EHSClutchEngagmntOffsetOpCtrl_IS 3000;
BA_REL_ "GenSigTimeoutTime" BU_SG_REL_ EBS SG_ 2499788567 EHSClutchEngagmntOffsetOpCtrl_IS 450;
BA_REL_ "GenSigFirstTimeoutTime" BU_SG_REL_ EBS SG_ 2499788567 Trailer1LiftAxle1PosReq 3000;
BA_REL_ "GenSigTimeoutTime" BU_SG_REL_ EBS SG_ 2499788567 Trailer1LiftAxle1PosReq 500;
BA_REL_ "GenSigFirstTimeoutTime" BU_SG_REL_ EBS SG_ 2499788567 Trailer2LiftAxle2PosReq 3000;
BA_REL_ "GenSigTimeoutTime" BU_SG_REL_ EBS SG_ 2499788567 Trailer2LiftAxle2PosReq 500;
BA_REL_ "GenSigFirstTimeoutTime" BU_SG_REL_ TECU SG_ 2499788567 DrvrRetarderBrakeBlending_rqst_I 3000;
BA_REL_ "GenSigTimeoutTime" BU_SG_REL_ TECU SG_ 2499788567 DrvrRetarderBrakeBlending_rqst_I 450;
BA_REL_ "GenSigFirstTimeoutTime" BU_SG_REL_ EBS SG_ 2499788567 DrvrRetarderBrakeBlending_rqst_I 3000;
BA_REL_ "GenSigTimeoutTime" BU_SG_REL_ EBS SG_ 2499788567 DrvrRetarderBrakeBlending_rqst_I 450;
BA_REL_ "GenSigFirstTimeoutTime" BU_SG_REL_ VMCU SG_ 2499788567 DrvrRetarderBrakeBlending_rqst_I 3000;
BA_REL_ "GenSigTimeoutTime" BU_SG_REL_ VMCU SG_ 2499788567 DrvrRetarderBrakeBlending_rqst_I 450;
BA_REL_ "GenSigFirstTimeoutTime" BU_SG_REL_ VMCU SG_ 2499788567 DrvrRetarderBrakeProgram_rqst_IS 3000;
BA_REL_ "GenSigTimeoutTime" BU_SG_REL_ VMCU SG_ 2499788567 DrvrRetarderBrakeProgram_rqst_IS 450;
BA_REL_ "GenSigFirstTimeoutTime" BU_SG_REL_ TECU SG_ 2499788567 DrvrRetarderBrakeProgram_rqst_IS 3000;
BA_REL_ "GenSigTimeoutTime" BU_SG_REL_ TECU SG_ 2499788567 DrvrRetarderBrakeProgram_rqst_IS 450;
BA_REL_ "GenSigFirstTimeoutTime" BU_SG_REL_ EBS SG_ 2499788567 RollerBenchModeRequest 3000;
BA_REL_ "GenSigTimeoutTime" BU_SG_REL_ EBS SG_ 2499788567 RollerBenchModeRequest 450;
BA_REL_ "GenSigFirstTimeoutTime" BU_SG_REL_ TECU SG_ 2499788567 GearLeverPositionBackup 3000;
BA_REL_ "GenSigTimeoutTime" BU_SG_REL_ TECU SG_ 2499788567 GearLeverPositionBackup 450;
BA_REL_ "GenSigFirstTimeoutTime" BU_SG_REL_ EBS SG_ 2499788567 EHSClutchEngagmntCalibOpCtrl_ISi 3000;
BA_REL_ "GenSigTimeoutTime" BU_SG_REL_ EBS SG_ 2499788567 EHSClutchEngagmntCalibOpCtrl_ISi 450;
BA_REL_ "GenSigFirstTimeoutTime" BU_SG_REL_ EBS SG_ 2499788567 Trailer3LiftAxle2PosReq 3000;
BA_REL_ "GenSigTimeoutTime" BU_SG_REL_ EBS SG_ 2499788567 Trailer3LiftAxle2PosReq 500;
BA_REL_ "GenSigFirstTimeoutTime" BU_SG_REL_ EBS SG_ 2499788567 Trailer1LiftAxle2PosReq 3000;
BA_REL_ "GenSigTimeoutTime" BU_SG_REL_ EBS SG_ 2499788567 Trailer1LiftAxle2PosReq 500;
BA_REL_ "GenSigFirstTimeoutTime" BU_SG_REL_ VMCU SG_ 2499788567 DriverRetarderRequest_ISig_3 3000;
BA_REL_ "GenSigTimeoutTime" BU_SG_REL_ VMCU SG_ 2499788567 DriverRetarderRequest_ISig_3 450;
BA_REL_ "GenSigFirstTimeoutTime" BU_SG_REL_ EBS SG_ 2499788567 DriverRetarderRequest_ISig_3 3000;
BA_REL_ "GenSigTimeoutTime" BU_SG_REL_ EBS SG_ 2499788567 DriverRetarderRequest_ISig_3 450;
BA_REL_ "GenSigFirstTimeoutTime" BU_SG_REL_ TECU SG_ 2499788567 DriverRetarderRequest_ISig_3 3000;
BA_REL_ "GenSigTimeoutTime" BU_SG_REL_ TECU SG_ 2499788567 DriverRetarderRequest_ISig_3 450;
BA_REL_ "GenSigFirstTimeoutTime" BU_SG_REL_ EMS SG_ 2499788567 DriverRetarderRequest_ISig_3 3000;
BA_REL_ "GenSigTimeoutTime" BU_SG_REL_ EMS SG_ 2499788567 DriverRetarderRequest_ISig_3 450;
BA_REL_ "GenSigFirstTimeoutTime" BU_SG_REL_ RECU_Virt SG_ 2499788567 DriverRetarderRequest_ISig_3 3000;
BA_REL_ "GenSigTimeoutTime" BU_SG_REL_ RECU_Virt SG_ 2499788567 DriverRetarderRequest_ISig_3 450;
BA_REL_ "GenSigFirstTimeoutTime" BU_SG_REL_ EBS SG_ 2499788567 Trailer3LiftAxle1PosReq 3000;
BA_REL_ "GenSigTimeoutTime" BU_SG_REL_ EBS SG_ 2499788567 Trailer3LiftAxle1PosReq 500;
BA_REL_ "GenSigFirstTimeoutTime" BU_SG_REL_ EBS SG_ 2499788567 Trailer2LiftAxle1PosReq 3000;
BA_REL_ "GenSigTimeoutTime" BU_SG_REL_ EBS SG_ 2499788567 Trailer2LiftAxle1PosReq 500;
VAL_ 2348814097 TSC1EMSrVMCU_EnRSpdCtrlC 3 "TSC1EngReqSpeedCtrlCond_StabilityOptDrvlnEngLockup2" 2 "TSC1EngReqSpeedCtrlCond_StabilityOptDrvlnEngLockup1" 1 "TSC1EngReqSpeedCtrlCond_StabilityOptDrvlnDisengNonLockup" 0 "TSC1EngReqSpeedCtrlCond_TransientOptimized" ;
VAL_ 2348814097 TSC1EMSrVMCU_OvrdCtrlMPr 3 "Priority_LowPriority" 2 "Priority_MediumPriority" 1 "Priority_HighPriority" 0 "Priority_HighestPriority" ;
VAL_ 2348814097 TSC1EMSrVMCU_EnOvrdCtrlM 3 "TSC1EngOverrideCtrlMode_SpeedTorqueLimitControl" 2 "TSC1EngOverrideCtrlMode_TorqueControl" 1 "TSC1EngOverrideCtrlMode_SpeedControl" 0 "TSC1EngOverrideCtrlMode_OverrideDisabled" ;
VAL_ 2348814083 TSC1EMSrTECU_OvrdCtrlMPr 3 "Priority_LowPriority" 2 "Priority_MediumPriority" 1 "Priority_HighPriority" 0 "Priority_HighestPriority" ;
VAL_ 2348814083 TSC1EMSrTECU_EnRSpdCtrlC 3 "TSC1EngReqSpeedCtrlCond_StabilityOptDrvlnEngLockup2" 2 "TSC1EngReqSpeedCtrlCond_StabilityOptDrvlnEngLockup1" 1 "TSC1EngReqSpeedCtrlCond_StabilityOptDrvlnDisengNonLockup" 0 "TSC1EngReqSpeedCtrlCond_TransientOptimized" ;
VAL_ 2348814083 TSC1EMSrTECU_EnOvrdCtrlM 3 "TSC1EngOverrideCtrlMode_SpeedTorqueLimitControl" 2 "TSC1EngOverrideCtrlMode_TorqueControl" 1 "TSC1EngOverrideCtrlMode_SpeedControl" 0 "TSC1EngOverrideCtrlMode_OverrideDisabled" ;
VAL_ 2348814091 TSC1EMSrABS_EnRSpdCtrlC 3 "TSC1EngReqSpeedCtrlCond_StabilityOptDrvlnEngLockup2" 2 "TSC1EngReqSpeedCtrlCond_StabilityOptDrvlnEngLockup1" 1 "TSC1EngReqSpeedCtrlCond_StabilityOptDrvlnDisengNonLockup" 0 "TSC1EngReqSpeedCtrlCond_TransientOptimized" ;
VAL_ 2348814091 TSC1EMSrABS_OvrdCtrlMPr 3 "Priority_LowPriority" 2 "Priority_MediumPriority" 1 "Priority_HighPriority" 0 "Priority_HighestPriority" ;
VAL_ 2348814091 TSC1EMSrABS_EnOvrdCtrlM 3 "TSC1EngOverrideCtrlMode_SpeedTorqueLimitControl" 2 "TSC1EngOverrideCtrlMode_TorqueControl" 1 "TSC1EngOverrideCtrlMode_SpeedControl" 0 "TSC1EngOverrideCtrlMode_OverrideDisabled" ;
VAL_ 2566882307 TransmEngineCrankEnable_ISig_3 3 "DisableEnable_NotAvailable" 2 "DisableEnable_Error" 1 "DisableEnable_Enable" 0 "DisableEnable_Disable" ;
VAL_ 2365484270 Driver2TimeRelatedStates_ISig_3 15 "DriverTimeRelatedStates_NotAvailable" 14 "DriverTimeRelatedStates_Error" 13 "DriverTimeRelatedStates_Other" 12 "DriverTimeRelatedStates_Reserved_05" 11 "DriverTimeRelatedStates_Reserved_04" 10 "DriverTimeRelatedStates_Reserved_03" 9 "DriverTimeRelatedStates_Reserved_02" 8 "DriverTimeRelatedStates_Reserved_01" 7 "DriverTimeRelatedStates_Reserved" 6 "DriverTimeRelatedStates_Limit6_16hReached" 5 "DriverTimeRelatedStates_Limit5_15MinutesBefore16h" 4 "DriverTimeRelatedStates_Limit4_9hReached" 3 "DriverTimeRelatedStates_Limit3_15MinutesBefore9h" 2 "DriverTimeRelatedStates_Limit2_4h30minReached" 1 "DriverTimeRelatedStates_Limit1_15minBefore4h30min" 0 "DriverTimeRelatedStates_NormalNoLimitsReached" ;
VAL_ 2365484270 VehicleMotion_ISig_3 3 "NotDetected_NotAvaliable" 2 "NotDetected_Error" 1 "NotDetected_Detected" 0 "NotDetected_NotDetected" ;
VAL_ 2365484270 TachographPerformance_ISig_3 3 "TachographPerformance_NotAvailable" 2 "TachographPerformance_Error" 1 "TachographPerformance_PerformanceAnalysis" 0 "TachographPerformance_NormalPerformance" ;
VAL_ 2365484270 Driver1WorkingState_ISig_3 7 "DriverWorkingState_NotAvailable" 6 "DriverWorkingState_ErrorIndicator" 5 "DriverWorkingState_Reserved_01" 4 "DriverWorkingState_Reserved" 3 "DriverWorkingState_DriveBehindWheel" 2 "DriverWorkingState_WorkLoadingUnloadingWorkingInAnOffice" 1 "DriverWorkingState_DriverAvailableShortBreak" 0 "DriverWorkingState_RestSleeping" ;
VAL_ 2365484270 Driver1TimeRelatedStates_ISig_3 15 "Driver1TimeRelatedStates_NotAvailable" 14 "Driver1TimeRelatedStates_Error" 13 "Driver1TimeRelatedStates_Other" 12 "Driver1TimeRelatedStates_NextMandatoryDriver1CardDownload" 11 "Driver1TimeRelatedStates_Driver1CardExpiryWarning" 10 "Driver1TimeRelatedStates_2WeekDrivingTimeWarning" 9 "Driver1TimeRelatedStates_2WeekDrivingTimePreWarning" 8 "Driver1TimeRelatedStates_WeeklyDrivingTimeWarning" 7 "Driver1TimeRelatedStates_WeeklyDrivingTimePreWarning" 6 "Driver1TimeRelatedStates_DailyWeeklyRestWarning" 5 "Driver1TimeRelatedStates_DailyWeeklyRestPreWarning" 4 "Driver1TimeRelatedStates_DailyDrivingTimeWarning" 3 "Driver1TimeRelatedStates_DailyDrivingTimePreWarning" 2 "Driver1TimeRelatedStates_4h30minReached" 1 "Driver1TimeRelatedStates_15minBefore4h30min" 0 "Driver1TimeRelatedStates_NormalNoLimitsReached" ;
VAL_ 2365484270 DriverCardDriver2_ISig_3 3 "NotPresentPresent_NotAvailable" 2 "NotPresentPresent_ErrorIndicator" 1 "NotPresentPresent_Present" 0 "NotPresentPresent_NotPresent" ;
VAL_ 2365484270 HandlingInformation_ISig_3 3 "HandlingInformation_NotAvailable" 2 "HandlingInformation_Error" 1 "HandlingInformation_HandlingInformation" 0 "HandlingInformation_NoHandlingInformation" ;
VAL_ 2365484270 DriverCardDriver1_ISig_3 3 "NotPresentPresent_NotAvailable" 2 "NotPresentPresent_ErrorIndicator" 1 "NotPresentPresent_Present" 0 "NotPresentPresent_NotPresent" ;
VAL_ 2365484270 SystemEvent_ISig_3 3 "SystemEvent_NotAvailable" 2 "SystemEvent_Error" 1 "SystemEvent_TachographEvent" 0 "SystemEvent_NoTachographEvent" ;
VAL_ 2365484270 VehicleOverspeed_ISig_3 3 "VehicleOverspeed_NotAvailable" 2 "VehicleOverspeed_PreOverspeed" 1 "VehicleOverspeed_Overspeed" 0 "VehicleOverspeed_NoOverspeed" ;
VAL_ 2365484270 Driver2WorkingState_ISig_3 7 "DriverWorkingState_NotAvailable" 6 "DriverWorkingState_ErrorIndicator" 5 "DriverWorkingState_Reserved_01" 4 "DriverWorkingState_Reserved" 3 "DriverWorkingState_DriveBehindWheel" 2 "DriverWorkingState_WorkLoadingUnloadingWorkingInAnOffice" 1 "DriverWorkingState_DriverAvailableShortBreak" 0 "DriverWorkingState_RestSleeping" ;
VAL_ 2348876549 TransmissionMode4 3 "DisableEnable_NotAvailableTakeNoAction" 2 "DisableEnable_Reserved" 1 "DisableEnable_Enable" 0 "DisableEnable_Disable" ;
VAL_ 2348876549 TransmShiftSelectorDisplayMode 3 "OffOn_NotAvailable" 2 "OffOn_Error" 1 "OffOn_On" 0 "OffOn_Off" ;
VAL_ 2348876549 TransmissionMode3 3 "DisableEnable_NotAvailableTakeNoAction" 2 "DisableEnable_Reserved" 1 "DisableEnable_Enable" 0 "DisableEnable_Disable" ;
VAL_ 2631855639 CounterReset_GUIEventCmd 3 "ResetEnum2Bit_NotAvailable" 2 "ResetEnum2Bit_Reserved" 1 "ResetEnum2Bit_Reset" 0 "ResetEnum2Bit_TakeNoAction" ;
VAL_ 2499792656 DrivelineRetarderStat_ISig_3 3 "DrivelineRetarderStat_NotAvailable" 2 "DrivelineRetarderStat_Error" 1 "DrivelineRetarderStat_RetarderCapacityDerated" 0 "DrivelineRetarderStat_RetarderCapacityNotDerated" ;
VAL_ 2566840592 DrivelineRetarderLocation 15 "DrivelineRetarderLocation_NotAvailable" 14 "DrivelineRetarderLocation_Other" 13 "DrivelineRetarderLocation_NotDefined_07" 12 "DrivelineRetarderLocation_NotDefined_06" 11 "DrivelineRetarderLocation_NotDefined_05" 10 "DrivelineRetarderLocation_NotDefined_04" 9 "DrivelineRetarderLocation_NotDefined_03" 8 "DrivelineRetarderLocation_NotDefined_02" 7 "DrivelineRetarderLocation_NotDefined_01" 6 "DrivelineRetarderLocation_NotDefined" 5 "DrivelineRetarderLocation_TrailerVehicleSpeed" 4 "DrivelineRetarderLocation_SecondaryDrivelineOutputShaftRpm" 3 "DrivelineRetarderLocation_SecondaryTransmissionOutput" 2 "DrivelineRetarderLocation_PrimaryTransmissionInputEngineRpm" 1 "DrivelineRetarderLocation_PrimaryEngineExhaustBrake" 0 "DrivelineRetarderLocation_PrimaryEngineCompressionReleaseBrake" ;
VAL_ 2566840592 DrivelineRetarderType 15 "DrivelineRetarderType_NotAvailable" 14 "DrivelineRetarderType_Other" 13 "DrivelineRetarderType_NotDefined_08" 12 "DrivelineRetarderType_NotDefined_07" 11 "DrivelineRetarderType_NotDefined_06" 10 "DrivelineRetarderType_NotDefined_05" 9 "DrivelineRetarderType_NotDefined_04" 8 "DrivelineRetarderType_NotDefined_03" 7 "DrivelineRetarderType_NotDefined_02" 6 "DrivelineRetarderType_NotDefined_01" 5 "DrivelineRetarderType_NotDefined" 4 "DrivelineRetarderType_Exhaust" 3 "DrivelineRetarderType_CompressionRelease" 2 "DrivelineRetarderType_CooledFriction" 1 "DrivelineRetarderType_Hydraulic" 0 "DrivelineRetarderType_ElectricMagnetic" ;
VAL_ 2566899694 RestingPeriodFlagShift2_ISig_3 1 "RestingPeriodFlagShift_Break3hMinAnd9hMaxWithinDrivingShift" 0 "RestingPeriodFlagShift_NoBreak3hMinAnd9hMaxWithinDrivingShift" ;
VAL_ 2566899694 UnknownPeriodShift1_ISig_3 1 "UnknownPeriodShift_UnknownTimeInDailyRestingPeriodShift" 0 "UnknownPeriodShift_NoUnknownTimeInDailyRestingPeriodShift" ;
VAL_ 2566899694 RestingPeriodFlagShift1_ISig_3 1 "RestingPeriodFlagShift_Break3hMinAnd9hMaxWithinDrivingShift" 0 "RestingPeriodFlagShift_NoBreak3hMinAnd9hMaxWithinDrivingShift" ;
VAL_ 2566899694 UnknownPeriodShift2_ISig_3 1 "UnknownPeriodShift_UnknownTimeInDailyRestingPeriodShift" 0 "UnknownPeriodShift_NoUnknownTimeInDailyRestingPeriodShift" ;
VAL_ 2566899694 RestingPeriodFlag_ISig_3 1 "RestingPeriodFlag_Break3hMinAnd9hMaxWithinCurrentDrivingTime" 0 "RestingPeriodFlag_NoBreak3hMinAnd9hMaxWithinCurrentDrivingTime" ;
VAL_ 2566899694 UnknownPeriodShift4_ISig_3 1 "UnknownPeriodShift_UnknownTimeInDailyRestingPeriodShift" 0 "UnknownPeriodShift_NoUnknownTimeInDailyRestingPeriodShift" ;
VAL_ 2566899694 RestingPeriodFlagShift6_ISig_3 1 "RestingPeriodFlagShift_Break3hMinAnd9hMaxWithinDrivingShift" 0 "RestingPeriodFlagShift_NoBreak3hMinAnd9hMaxWithinDrivingShift" ;
VAL_ 2566899694 RestingPeriodFlagShift5_ISig_3 1 "RestingPeriodFlagShift_Break3hMinAnd9hMaxWithinDrivingShift" 0 "RestingPeriodFlagShift_NoBreak3hMinAnd9hMaxWithinDrivingShift" ;
VAL_ 2566899694 RestingPeriodFlagShift3_ISig_3 1 "RestingPeriodFlagShift_Break3hMinAnd9hMaxWithinDrivingShift" 0 "RestingPeriodFlagShift_NoBreak3hMinAnd9hMaxWithinDrivingShift" ;
VAL_ 2566899694 UnknownPeriodShift7_ISig_3 1 "UnknownPeriodShift_UnknownTimeInDailyRestingPeriodShift" 0 "UnknownPeriodShift_NoUnknownTimeInDailyRestingPeriodShift" ;
VAL_ 2566899694 UnknownPeriodShift6_ISig_3 1 "UnknownPeriodShift_UnknownTimeInDailyRestingPeriodShift" 0 "UnknownPeriodShift_NoUnknownTimeInDailyRestingPeriodShift" ;
VAL_ 2566899694 UnknownPeriodShift3_ISig_3 1 "UnknownPeriodShift_UnknownTimeInDailyRestingPeriodShift" 0 "UnknownPeriodShift_NoUnknownTimeInDailyRestingPeriodShift" ;
VAL_ 2566899694 RestingPeriodFlagShift4_ISig_3 1 "RestingPeriodFlagShift_Break3hMinAnd9hMaxWithinDrivingShift" 0 "RestingPeriodFlagShift_NoBreak3hMinAnd9hMaxWithinDrivingShift" ;
VAL_ 2566899694 UnknownPeriodShift5_ISig_3 1 "UnknownPeriodShift_UnknownTimeInDailyRestingPeriodShift" 0 "UnknownPeriodShift_NoUnknownTimeInDailyRestingPeriodShift" ;
VAL_ 2566898926 Driver1CardUnload_Tacho 3 "Alert_NotAvailable" 2 "Alert_Error" 1 "Alert_Alert" 0 "Alert_NoAlert" ;
VAL_ 2566898926 EndofLifeDriver1Card_Tacho 3 "Alert_NotAvailable" 2 "Alert_Error" 1 "Alert_Alert" 0 "Alert_NoAlert" ;
VAL_ 2566898926 DrawerState_Tacho 3 "DrawerState_NotAvailable" 2 "DrawerState_Error" 1 "DrawerState_Close" 0 "DrawerState_Open" ;
VAL_ 2566759457 Pto2EnableSwitch 3 "OffOn_NotAvailable" 2 "OffOn_Error" 1 "OffOn_On" 0 "OffOn_Off" ;
VAL_ 2566759457 Pto1EnableSwitch 3 "OffOn_NotAvailable" 2 "OffOn_Error" 1 "OffOn_On" 0 "OffOn_Off" ;
VAL_ 2566759427 Pto2EngagementConsent 3 "PtoConsent_NotAvailable" 2 "PtoConsent_Error" 1 "PtoConsent_ConsentGivenPTODriveMayBeEngaged" 0 "PtoConsent_ConsentNotGivenPTODriveShouldNotBeEngaged" ;
VAL_ 2566759427 Pto1EngagementConsent 3 "PtoConsent_NotAvailable" 2 "PtoConsent_Error" 1 "PtoConsent_ConsentGivenPTODriveMayBeEngaged" 0 "PtoConsent_ConsentNotGivenPTODriveShouldNotBeEngaged" ;
VAL_ 2499788567 AutoRearAxleDiffLockActvn_rqst 7 "AutoRearAxleDiffLockActvn_rqst_NotAvailable" 6 "AutoRearAxleDiffLockActvn_rqst_Error" 5 "AutoRearAxleDiffLockActvn_rqst_Reserved_02" 4 "AutoRearAxleDiffLockActvn_rqst_Reserved_01" 3 "AutoRearAxleDiffLockActvn_rqst_Reserved" 2 "AutoRearAxleDiffLockActvn_rqst_OnRequested" 1 "AutoRearAxleDiffLockActvn_rqst_OffRequested" 0 "AutoRearAxleDiffLockActvn_rqst_NoRequest" ;
VAL_ 2499788567 Trailer1LiftAxle1PosReq 3 "TrailerLiftAxlePosReq_TakeNoAction" 2 "TrailerLiftAxlePosReq_Reserved" 1 "TrailerLiftAxlePosReq_RequestToLiftTheLiftAxle" 0 "TrailerLiftAxlePosReq_RequestToLowerTheLiftAxle" ;
VAL_ 2499788567 Trailer2LiftAxle2PosReq 3 "TrailerLiftAxlePosReq_TakeNoAction" 2 "TrailerLiftAxlePosReq_Reserved" 1 "TrailerLiftAxlePosReq_RequestToLiftTheLiftAxle" 0 "TrailerLiftAxlePosReq_RequestToLowerTheLiftAxle" ;
VAL_ 2499788567 DrvrRetarderBrakeBlending_rqst_I 3 "OffOn_NotAvailable" 2 "OffOn_Error" 1 "OffOn_On" 0 "OffOn_Off" ;
VAL_ 2499788567 DrvrRetarderBrakeProgram_rqst_IS 3 "OffOn_NotAvailable" 2 "OffOn_Error" 1 "OffOn_On" 0 "OffOn_Off" ;
VAL_ 2499788567 RollerBenchModeRequest 3 "OffOn_NotAvailable" 2 "OffOn_Error" 1 "OffOn_On" 0 "OffOn_Off" ;
VAL_ 2499788567 GearLeverPositionBackup 15 "GearLeverPosition_NotAvailable" 14 "GearLeverPosition_Error" 13 "GearLeverPosition_SpareValue_06" 12 "GearLeverPosition_SpareValue_05" 11 "GearLeverPosition_SpareValue_04" 10 "GearLeverPosition_SpareValue_03" 9 "GearLeverPosition_SpareValue_02" 8 "GearLeverPosition_SpareValue_01" 7 "GearLeverPosition_SpareValue" 6 "GearLeverPosition_SEG6" 5 "GearLeverPosition_LowGear" 4 "GearLeverPosition_Manual" 3 "GearLeverPosition_Automatic" 2 "GearLeverPosition_Neutral" 1 "GearLeverPosition_Reverse" 0 "GearLeverPosition_GearFoldedAway" ;
VAL_ 2499788567 EHSClutchEngagmntCalibOpCtrl_ISi 3 "Request_NotAvailable" 2 "Request_Error" 1 "Request_RequestActive" 0 "Request_NotRequested" ;
VAL_ 2499788567 Trailer3LiftAxle2PosReq 3 "TrailerLiftAxlePosReq_TakeNoAction" 2 "TrailerLiftAxlePosReq_Reserved" 1 "TrailerLiftAxlePosReq_RequestToLiftTheLiftAxle" 0 "TrailerLiftAxlePosReq_RequestToLowerTheLiftAxle" ;
VAL_ 2499788567 Trailer1LiftAxle2PosReq 3 "TrailerLiftAxlePosReq_TakeNoAction" 2 "TrailerLiftAxlePosReq_Reserved" 1 "TrailerLiftAxlePosReq_RequestToLiftTheLiftAxle" 0 "TrailerLiftAxlePosReq_RequestToLowerTheLiftAxle" ;
VAL_ 2499788567 DriverRetarderRequest_ISig_3 7 "DriverRetarderRequest_NotAvailable" 6 "DriverRetarderRequest_Error" 5 "DriverRetarderRequest_Level5" 4 "DriverRetarderRequest_Level4" 3 "DriverRetarderRequest_Level3" 2 "DriverRetarderRequest_Level2" 1 "DriverRetarderRequest_Level1" 0 "DriverRetarderRequest_NoRequest" ;
VAL_ 2499788567 Trailer3LiftAxle1PosReq 3 "TrailerLiftAxlePosReq_TakeNoAction" 2 "TrailerLiftAxlePosReq_Reserved" 1 "TrailerLiftAxlePosReq_RequestToLiftTheLiftAxle" 0 "TrailerLiftAxlePosReq_RequestToLowerTheLiftAxle" ;
VAL_ 2499788567 Trailer2LiftAxle1PosReq 3 "TrailerLiftAxlePosReq_TakeNoAction" 2 "TrailerLiftAxlePosReq_Reserved" 1 "TrailerLiftAxlePosReq_RequestToLiftTheLiftAxle" 0 "TrailerLiftAxlePosReq_RequestToLowerTheLiftAxle" ;
SIG_GROUP_ 2348814097 TSC1EMSrVMCU_sg 1 : TSC1EMSrVMCU_EnRSpdCtrlC TSC1EMSrVMCU_EnRTrqTrqLm TSC1EMSrVMCU_OvrdCtrlMPr TSC1EMSrVMCU_EnRSpdSpdLm TSC1EMSrVMCU_EnOvrdCtrlM;
SIG_GROUP_ 2348814083 TSC1EMSrTECU_sg 1 : TSC1EMSrTECU_OvrdCtrlMPr TSC1EMSrTECU_EnRSpdCtrlC TSC1EMSrTECU_EnOvrdCtrlM TSC1EMSrTECU_EnRTrqTrqLm TSC1EMSrTECU_EnRSpdSpdLm;
SIG_GROUP_ 2348814091 TSC1EMSrABS_sg 1 : TSC1EMSrABS_EnRTrqTrqLm TSC1EMSrABS_EnRSpdCtrlC TSC1EMSrABS_OvrdCtrlMPr TSC1EMSrABS_EnOvrdCtrlM TSC1EMSrABS_EnRSpdSpdLm;
